VERSION "created by canmatrix"

NS_ :

BS_:

BU_: IPD

BO_ 859 ICBAD_BKPCANFD_100ms_FrP34: 8 IPD
 SG_ ISpdLmtMdResp : 25|2@0+ (1,0) [0|3] "null" Vector__XXX
 SG_ IAutoMainBeamLghtReq : 57|2@0+ (1,0) [0|3] "null" Vector__XXX

BO_ 895 ICBAD_BKPCANFD_100ms_FrP36: 16 IPD
 SG_ INarwSpcAstSwSts : 9|2@0+ (1,0) [0|3] "null" Vector__XXX
 SG_ INarwSpcAstBtnSts : 23|3@0+ (1,0) [0|7] "null" Vector__XXX
 SG_ IIPD_VehLckCtrlReq : 31|8@0+ (1,0) [0|255] "null" Vector__XXX
 SG_ IRembParkngInPrmt : 40|1@0+ (1,0) [0|1] "null" Vector__XXX
 SG_ IRembParkngInMapngResp : 41|1@0+ (1,0) [0|1] "null" Vector__XXX
 SG_ IRembParkngInPrmtSwSts : 49|2@0+ (1,0) [0|3] "null" Vector__XXX
 SG_ IRembParkngInMapngIndcr : 60|3@0+ (1,0) [0|7] "null" Vector__XXX
 SG_ IRembParkngInMapRutSeln : 63|3@0+ (1,0) [0|7] "null" Vector__XXX
 SG_ IIPDMCUTemp : 71|8@0+ (1,-40) [-40|215] "℃" Vector__XXX
 SG_ IIPDWtrClntInltReqFlg : 79|1@0+ (1,0) [0|1] "null" Vector__XXX
 SG_ ITrfGreenLghtActn : 103|1@0+ (1,0) [0|1] "null" Vector__XXX
 SG_ IRembParkngInMapngRutID : 108|5@0+ (1,0) [0|31] "null" Vector__XXX
 SG_ IRembParkngInMapngDistToEnd : 119|9@0+ (0.5,0) [0|255.5] "null" Vector__XXX
 SG_ IRembParkngInMapRutDltSeln : 126|4@0+ (1,0) [0|15] "null" Vector__XXX

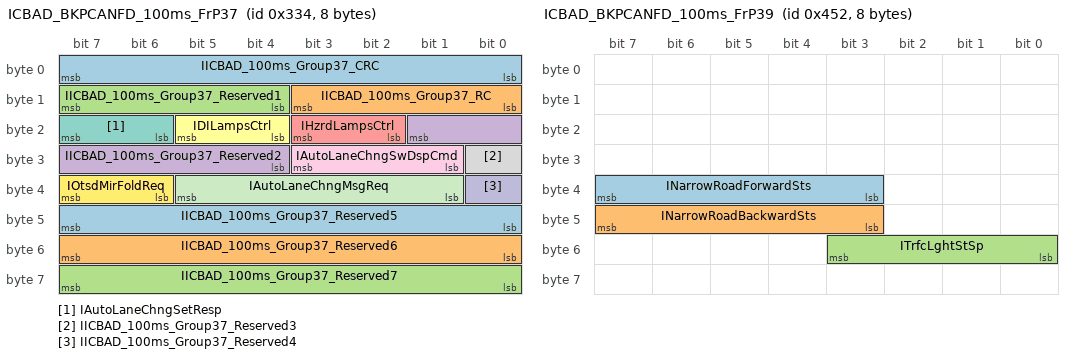
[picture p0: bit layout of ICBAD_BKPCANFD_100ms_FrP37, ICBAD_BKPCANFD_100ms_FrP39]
BO_ 820 ICBAD_BKPCANFD_100ms_FrP37: 8 IPD
 SG_ IICBAD_100ms_Group37_CRC : 7|8@0+ (1,0) [0|255] "null" Vector__XXX
 SG_ IICBAD_100ms_Group37_RC : 11|4@0+ (1,0) [0|15] "null" Vector__XXX
 SG_ IICBAD_100ms_Group37_Reserved1 : 15|4@0+ (1,0) [0|15] "null" Vector__XXX
 SG_ IICBAD_100ms_Group37_Reserved2 : 17|6@0+ (1,0) [0|63] "null" Vector__XXX
 SG_ IHzrdLampsCtrl : 19|2@0+ (1,0) [0|3] "null" Vector__XXX
 SG_ IDILampsCtrl : 21|2@0+ (1,0) [0|3] "null" Vector__XXX
 SG_ IAutoLaneChngSetResp : 23|2@0+ (1,0) [0|3] "null" Vector__XXX
 SG_ IICBAD_100ms_Group37_Reserved3 : 24|1@0+ (1,0) [0|1] "null" Vector__XXX
 SG_ IAutoLaneChngSwDspCmd : 27|3@0+ (1,0) [0|7] "null" Vector__XXX
 SG_ IICBAD_100ms_Group37_Reserved4 : 32|1@0+ (1,0) [0|1] "null" Vector__XXX
 SG_ IAutoLaneChngMsgReq : 37|5@0+ (1,0) [0|31] "null" Vector__XXX
 SG_ IOtsdMirFoldReq : 39|2@0+ (1,0) [0|3] "null" Vector__XXX
 SG_ IICBAD_100ms_Group37_Reserved5 : 47|8@0+ (1,0) [0|255] "null" Vector__XXX
 SG_ IICBAD_100ms_Group37_Reserved6 : 55|8@0+ (1,0) [0|255] "null" Vector__XXX
 SG_ IICBAD_100ms_Group37_Reserved7 : 63|8@0+ (1,0) [0|255] "null" Vector__XXX

BO_ 1105 ICBAD_BKPCANFD_100ms_FrP38: 32 IPD
 SG_ IELKSysSts : 66|3@0+ (1,0) [0|7] "null" Vector__XXX
 SG_ IELKSysFltSts : 74|3@0+ (1,0) [0|7] "null" Vector__XXX
 SG_ IAIParkngSpdswSts : 98|3@0+ (1,0) [0|7] "null" Vector__XXX
 SG_ INrwroadFwdSta : 122|3@0+ (1,0) [0|7] "null" Vector__XXX
 SG_ INrwroadsltSta : 130|3@0+ (1,0) [0|7] "null" Vector__XXX
 SG_ IIPDELKDspCmd : 194|2@0+ (1,0) [0|3] "null" Vector__XXX
 SG_ IMemParkngStrtBtnSts : 201|2@0+ (1,0) [0|3] "null" Vector__XXX
 SG_ IMemParkngBtnRcnm : 203|2@0+ (1,0) [0|3] "null" Vector__XXX
 SG_ IMemParkngBtnSts : 205|2@0+ (1,0) [0|3] "null" Vector__XXX

BO_ 1106 ICBAD_BKPCANFD_100ms_FrP39: 8 IPD
 SG_ INarrowRoadForwardSts : 39|5@0+ (1,0) [0|31] "null" Vector__XXX
 SG_ INarrowRoadBackwardSts : 47|5@0+ (1,0) [0|31] "null" Vector__XXX
 SG_ ITrfcLghtStSp : 51|4@0+ (1,0) [0|15] "null" Vector__XXX

BO_ 151 ICBAD_BKPCANFD_100ms_FrP44: 24 IPD
 SG_ IAIParkngEPAMdsts : 32|1@0+ (1,0) [0|1] "null" Vector__XXX
 SG_ ID2DSwReqResps : 41|2@0+ (1,0) [0|3] "null" Vector__XXX
 SG_ IFCTBSysFltSts : 77|2@0+ (1,0) [0|3] "null" Vector__XXX
 SG_ ID2DPriETClanSwReqResps : 79|2@0+ (1,0) [0|3] "null" Vector__XXX

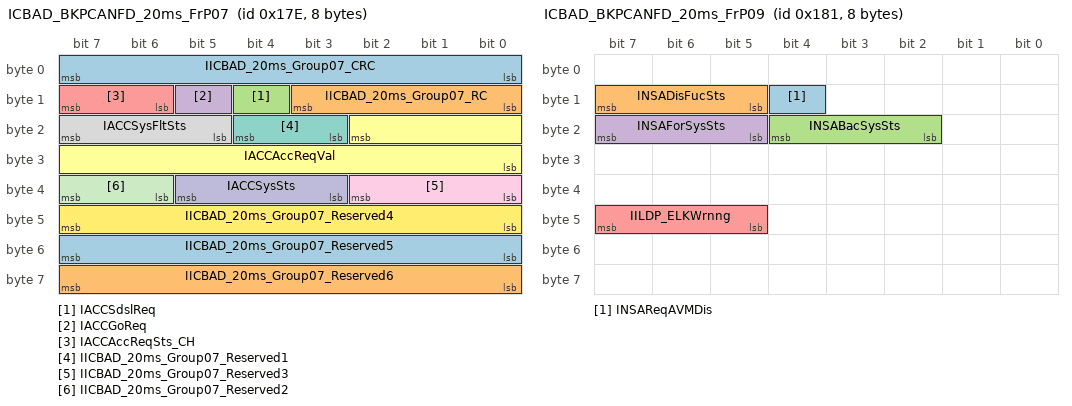
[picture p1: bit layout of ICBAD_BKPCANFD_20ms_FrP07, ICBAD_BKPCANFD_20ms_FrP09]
BO_ 382 ICBAD_BKPCANFD_20ms_FrP07: 8 IPD
 SG_ IICBAD_20ms_Group07_CRC : 7|8@0+ (1,0) [0|255] "null" Vector__XXX
 SG_ IICBAD_20ms_Group07_RC : 11|4@0+ (1,0) [0|15] "null" Vector__XXX
 SG_ IACCSdslReq : 12|1@0+ (1,0) [0|1] "null" Vector__XXX
 SG_ IACCGoReq : 13|1@0+ (1,0) [0|1] "null" Vector__XXX
 SG_ IACCAccReqSts_CH : 15|2@0+ (1,0) [0|3] "null" Vector__XXX
 SG_ IACCAccReqVal : 18|11@0+ (0.006,-10.278) [-10.278|2.004] "null" Vector__XXX
 SG_ IICBAD_20ms_Group07_Reserved1 : 20|2@0+ (1,0) [0|3] "null" Vector__XXX
 SG_ IACCSysFltSts : 23|3@0+ (1,0) [0|7] "null" Vector__XXX
 SG_ IICBAD_20ms_Group07_Reserved3 : 34|3@0+ (1,0) [0|7] "null" Vector__XXX
 SG_ IACCSysSts : 37|3@0+ (1,0) [0|7] "null" Vector__XXX
 SG_ IICBAD_20ms_Group07_Reserved2 : 39|2@0+ (1,0) [0|3] "null" Vector__XXX
 SG_ IICBAD_20ms_Group07_Reserved4 : 47|8@0+ (1,0) [0|255] "null" Vector__XXX
 SG_ IICBAD_20ms_Group07_Reserved5 : 55|8@0+ (1,0) [0|255] "null" Vector__XXX
 SG_ IICBAD_20ms_Group07_Reserved6 : 63|8@0+ (1,0) [0|255] "null" Vector__XXX

BO_ 385 ICBAD_BKPCANFD_20ms_FrP09: 8 IPD
 SG_ INSAReqAVMDis : 12|1@0+ (1,0) [0|1] "null" Vector__XXX
 SG_ INSADisFucSts : 15|3@0+ (1,0) [0|7] "null" Vector__XXX
 SG_ INSABacSysSts : 20|3@0+ (1,0) [0|7] "null" Vector__XXX
 SG_ INSAForSysSts : 23|3@0+ (1,0) [0|7] "null" Vector__XXX
 SG_ IILDP_ELKWrnng : 47|3@0+ (1,0) [0|7] "null" Vector__XXX

BO_ 736 ICBAD_BKPCANFD_50ms_FrP17: 20 IPD
 SG_ IFrtObsDist : 7|8@0+ (1,0) [0|255] "cm" Vector__XXX
 SG_ IFrtMidRObsRng : 11|4@0+ (1,0) [0|15] "null" Vector__XXX
 SG_ IFrtPDCAudWrnng : 15|4@0+ (1,0) [0|15] "null" Vector__XXX
 SG_ IRrMidLObsRng : 19|4@0+ (1,0) [0|15] "null" Vector__XXX
 SG_ IRLObsRng : 23|4@0+ (1,0) [0|15] "null" Vector__XXX
 SG_ IRrMidRObsRng : 31|4@0+ (1,0) [0|15] "null" Vector__XXX
 SG_ IPDCSysSts : 39|4@0+ (1,0) [0|15] "null" Vector__XXX
 SG_ IRrObsDist : 63|8@0+ (1,0) [0|255] "cm" Vector__XXX
 SG_ IFLSideObsRng : 67|4@0+ (1,0) [0|15] "null" Vector__XXX
 SG_ IRrPDCAudWrnng : 71|4@0+ (1,0) [0|15] "null" Vector__XXX
 SG_ IRLSideObsRng : 75|4@0+ (1,0) [0|15] "null" Vector__XXX
 SG_ IFRSideObsRng : 79|4@0+ (1,0) [0|15] "null" Vector__XXX
 SG_ IUndergndParkngGrgSts : 83|2@0+ (1,0) [0|3] "null" Vector__XXX
 SG_ IRRSideObsRng : 87|4@0+ (1,0) [0|15] "null" Vector__XXX
 SG_ IFLObsRng : 123|4@0+ (1,0) [0|15] "null" Vector__XXX
 SG_ IRRObsRng : 131|4@0+ (1,0) [0|15] "null" Vector__XXX
 SG_ IFRObsRng : 135|4@0+ (1,0) [0|15] "null" Vector__XXX
 SG_ ILADSAFnInd : 139|4@0+ (1,0) [0|15] "null" Vector__XXX
 SG_ IFrtMidLObsRng : 143|4@0+ (1,0) [0|15] "null" Vector__XXX
 SG_ IFRSObsRng : 147|4@0+ (1,0) [0|15] "null" Vector__XXX
 SG_ IFLSObsRng : 151|4@0+ (1,0) [0|15] "null" Vector__XXX
 SG_ IRRSObsRng : 155|4@0+ (1,0) [0|15] "null" Vector__XXX
 SG_ IRLSObsRng : 159|4@0+ (1,0) [0|15] "null" Vector__XXX

BO_ 314 ICBAD_CHCANFD_20ms_FrP08: 8 IPD
 SG_ ID2DSysSts : 31|4@0+ (1,0) [0|15] "null" Vector__XXX

BO_ 50 ICBAD_SecOC_ComKeyResp: 8 IPD
 SG_ IIPDTripCntResetResp : 6|1@0+ (1,0) [0|1] "null" Vector__XXX

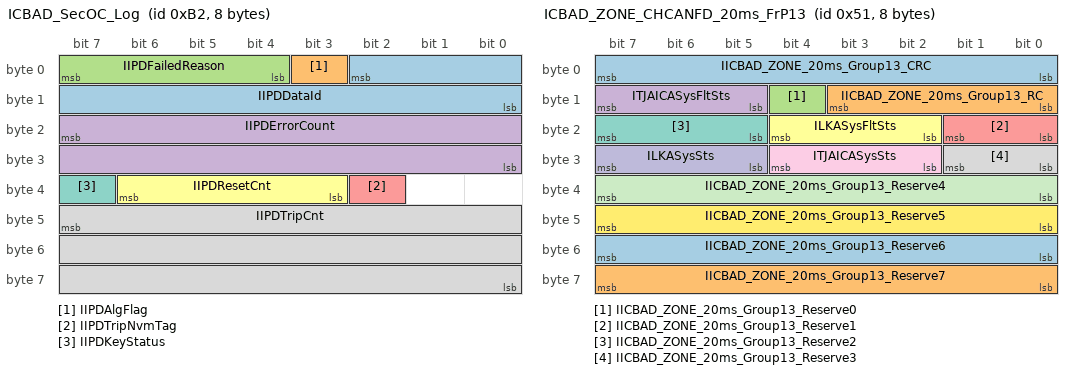
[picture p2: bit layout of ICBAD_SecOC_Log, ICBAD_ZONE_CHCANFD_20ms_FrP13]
BO_ 178 ICBAD_SecOC_Log: 8 IPD
 SG_ IIPDDataId : 2|11@0+ (1,0) [0|2047] "null" Vector__XXX
 SG_ IIPDAlgFlag : 3|1@0+ (1,0) [0|1] "null" Vector__XXX
 SG_ IIPDFailedReason : 7|4@0+ (1,0) [0|15] "null" Vector__XXX
 SG_ IIPDErrorCount : 23|16@0+ (1,0) [0|65535] "null" Vector__XXX
 SG_ IIPDTripNvmTag : 34|1@0+ (1,0) [0|1] "null" Vector__XXX
 SG_ IIPDResetCnt : 38|4@0+ (1,0) [0|15] "null" Vector__XXX
 SG_ IIPDKeyStatus : 39|1@0+ (1,0) [0|1] "null" Vector__XXX
 SG_ IIPDTripCnt : 47|24@0+ (1,0) [0|16777215] "null" Vector__XXX

BO_ 81 ICBAD_ZONE_CHCANFD_20ms_FrP13: 8 IPD
 SG_ IICBAD_ZONE_20ms_Group13_CRC : 7|8@0+ (1,0) [0|255] "null" Vector__XXX
 SG_ IICBAD_ZONE_20ms_Group13_RC : 11|4@0+ (1,0) [0|15] "null" Vector__XXX
 SG_ IICBAD_ZONE_20ms_Group13_Reserve0 : 12|1@0+ (1,0) [0|1] "null" Vector__XXX
 SG_ ITJAICASysFltSts : 15|3@0+ (1,0) [0|7] "null" Vector__XXX
 SG_ IICBAD_ZONE_20ms_Group13_Reserve1 : 17|2@0+ (1,0) [0|3] "null" Vector__XXX
 SG_ ILKASysFltSts : 20|3@0+ (1,0) [0|7] "null" Vector__XXX
 SG_ IICBAD_ZONE_20ms_Group13_Reserve2 : 23|3@0+ (1,0) [0|7] "null" Vector__XXX
 SG_ IICBAD_ZONE_20ms_Group13_Reserve3 : 25|2@0+ (1,0) [0|3] "null" Vector__XXX
 SG_ ITJAICASysSts : 28|3@0+ (1,0) [0|7] "null" Vector__XXX
 SG_ ILKASysSts : 31|3@0+ (1,0) [0|7] "null" Vector__XXX
 SG_ IICBAD_ZONE_20ms_Group13_Reserve4 : 39|8@0+ (1,0) [0|255] "null" Vector__XXX
 SG_ IICBAD_ZONE_20ms_Group13_Reserve5 : 47|8@0+ (1,0) [0|255] "null" Vector__XXX
 SG_ IICBAD_ZONE_20ms_Group13_Reserve6 : 55|8@0+ (1,0) [0|255] "null" Vector__XXX
 SG_ IICBAD_ZONE_20ms_Group13_Reserve7 : 63|8@0+ (1,0) [0|255] "null" Vector__XXX

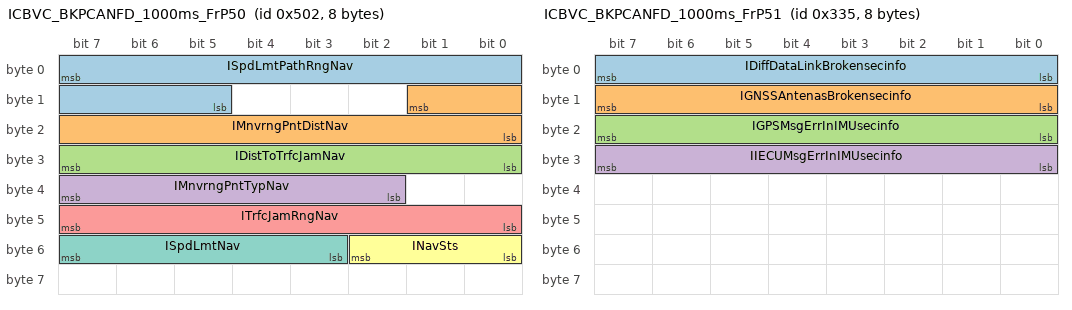
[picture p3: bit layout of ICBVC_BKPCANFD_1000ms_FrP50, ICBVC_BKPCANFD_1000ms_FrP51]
BO_ 1282 ICBVC_BKPCANFD_1000ms_FrP50: 8 Vector__XXX
 SG_ ISpdLmtPathRngNav : 7|11@0+ (0.01,0) [0.00|20.47] "km" IPD
 SG_ IMnvrngPntDistNav : 9|10@0+ (1,0) [0|1023] "m" IPD
 SG_ IDistToTrfcJamNav : 31|8@0+ (0.1,0) [0|25.5] "km" IPD
 SG_ IMnvrngPntTypNav : 39|6@0+ (1,0) [0|63] "null" IPD
 SG_ ITrfcJamRngNav : 47|8@0+ (0.1,0) [0|25.5] "km" IPD
 SG_ INavSts : 50|3@0+ (1,0) [0|7] "null" IPD
 SG_ ISpdLmtNav : 55|5@0+ (5,0) [0|155] "kph" IPD

BO_ 821 ICBVC_BKPCANFD_1000ms_FrP51: 8 Vector__XXX
 SG_ IDiffDataLinkBrokensecinfo : 7|8@0+ (1,0) [0|255] "null" IPD
 SG_ IGNSSAntenasBrokensecinfo : 15|8@0+ (1,0) [0|255] "null" IPD
 SG_ IGPSMsgErrInIMUsecinfo : 23|8@0+ (1,0) [0|255] "null" IPD
 SG_ IIECUMsgErrInIMUsecinfo : 31|8@0+ (1,0) [0|255] "null" IPD

BO_ 66 ICBVC_BKPCANFD_100ms_FrP01: 16 Vector__XXX
 SG_ IDspMeasmtSys : 15|1@0+ (1,0) [0|1] "null" IPD
 SG_ IUsgMdExtrCtrlAvlbl : 16|1@0+ (1,0) [0|1] "null" IPD
 SG_ IUsgMdCtrlSts : 17|1@0+ (1,0) [0|1] "null" IPD
 SG_ IRWSDrvMdReqV : 18|1@0+ (1,0) [0|1] "null" IPD
 SG_ IRWSDrvMdReq : 21|3@0+ (1,0) [0|7] "null" IPD
 SG_ IPDCSwReq : 23|2@0+ (1,0) [0|3] "null" IPD
 SG_ IPwrMdExtrCtrlAvlbl : 24|1@0+ (1,0) [0|1] "null" IPD
 SG_ IMdOfPwrMd : 25|1@0+ (1,0) [0|1] "null" IPD
 SG_ IClstrDspdVehSpd : 39|8@0+ (1,0) [0|255] "kph" IPD
 SG_ IFRSeatVentCtrlSts : 75|4@0+ (1,0) [0|15] "null" Vector__XXX
 SG_ IFLSeatVentCtrlSts : 83|4@0+ (1,0) [0|15] "null" Vector__XXX
 SG_ IFRSeatHeatCtrlSts : 87|4@0+ (1,0) [0|15] "null" Vector__XXX
 SG_ IFLSeatHeatCtrlSts : 95|4@0+ (1,0) [0|15] "null" Vector__XXX

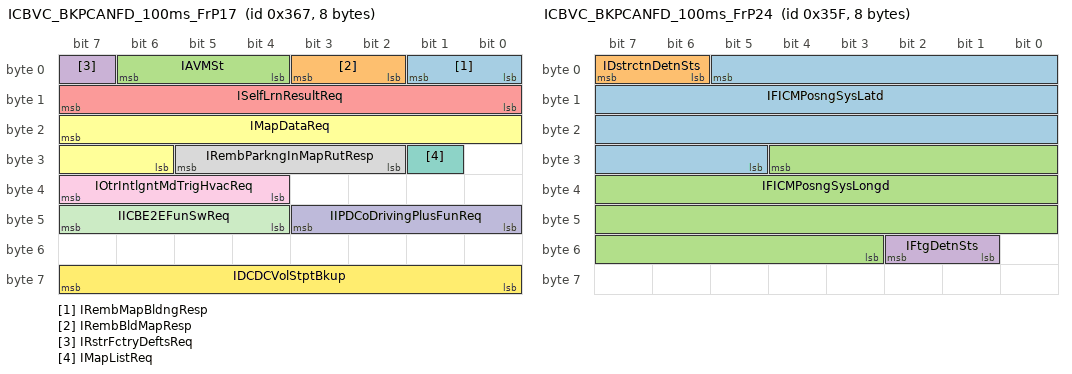
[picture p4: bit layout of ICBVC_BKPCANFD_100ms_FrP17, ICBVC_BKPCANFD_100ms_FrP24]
BO_ 871 ICBVC_BKPCANFD_100ms_FrP17: 8 Vector__XXX
 SG_ IRembMapBldngResp : 1|2@0+ (1,0) [0|3] "null" IPD
 SG_ IRembBldMapResp : 3|2@0+ (1,0) [0|3] "null" IPD
 SG_ IAVMSt : 6|3@0+ (1,0) [0|7] "null" IPD
 SG_ IRstrFctryDeftsReq : 7|1@0+ (1,0) [0|1] "null" IPD
 SG_ ISelfLrnResultReq : 15|8@0+ (1,0) [0|255] "null" IPD
 SG_ IMapDataReq : 23|10@0+ (1,0) [0|1023] "null" IPD
 SG_ IMapListReq : 25|1@0+ (1,0) [0|1] "null" IPD
 SG_ IRembParkngInMapRutResp : 29|4@0+ (1,0) [0|15] "null" IPD
 SG_ IOtrIntlgntMdTrigHvacReq : 39|4@0+ (1,0) [0|15] "null" Vector__XXX
 SG_ IIPDCoDrivingPlusFunReq : 43|4@0+ (1,0) [0|15] "null" IPD
 SG_ IICBE2EFunSwReq : 47|4@0+ (1,0) [0|15] "null" IPD
 SG_ IDCDCVolStptBkup : 63|8@0+ (0.03125,8.5) [8.50000|16.46875] "V" Vector__XXX

BO_ 863 ICBVC_BKPCANFD_100ms_FrP24: 8 Vector__XXX
 SG_ IFICMPosngSysLatd : 5|25@0- (0.000010,0) [-167.772160|167.772150] "Degree" IPD
 SG_ IDstrctnDetnSts : 7|2@0+ (1,0) [0|3] "null" IPD
 SG_ IFICMPosngSysLongd : 28|26@0- (0.000010,0) [-335.544320|335.544310] "Degree" IPD
 SG_ IFtgDetnSts : 50|2@0+ (1,0) [0|3] "null" IPD

BO_ 906 ICBVC_BKPCANFD_100ms_FrP25: 16 Vector__XXX
 SG_ INavCrntRoadTyp : 3|4@0+ (1,0) [0|15] "null" IPD
 SG_ INavNewIcon : 7|4@0+ (1,0) [0|15] "null" IPD
 SG_ IVceCntrl_CriSpdDecreValu : 15|8@0+ (1,0) [0|255] "kph" IPD
 SG_ IVceCntrl_CriSpdIncreValu : 23|8@0+ (1,0) [0|255] "kph" IPD
 SG_ IVceCntrl_CriSpdValu : 31|8@0+ (1,0) [0|255] "kph" IPD
 SG_ IMinorAdjSetReq : 33|2@0+ (1,0) [0|3] "null" IPD
 SG_ IVceCntrl_DistanLevl : 36|3@0+ (1,0) [0|7] "null" IPD
 SG_ IVceCntrl_DecreCriSpd : 39|3@0+ (1,0) [0|7] "null" IPD
 SG_ IParkOutEntrySetReq : 41|2@0+ (1,0) [0|3] "null" IPD
 SG_ IVceCntrl_AIPilot : 44|3@0+ (1,0) [0|7] "null" IPD
 SG_ INavTrfcLghtInfo : 47|3@0+ (1,0) [0|7] "null" IPD
 SG_ INavCountryCode : 49|10@0+ (1,0) [0|1023] "null" IPD
 SG_ IVceCntrl_DistanLevlIncre : 52|3@0+ (1,0) [0|7] "null" IPD
 SG_ IVceCntrl_DistanLevlDecre : 55|3@0+ (1,0) [0|7] "null" IPD
 SG_ INavSpdLmtValUnit : 66|2@0+ (1,0) [0|3] "null" IPD
 SG_ INavNewIconDist : 71|5@0+ (0.1,0) [0|3.1] "null" IPD
 SG_ INavSpdLmtValSts : 73|2@0+ (1,0) [0|3] "null" IPD
 SG_ INavDistFromFrtEleccEye : 79|6@0+ (0.1,0) [0|6.3] "null" IPD
 SG_ INavItvalSpdDetnDistRetDist : 87|15@0+ (0.1,0) [0|3276.7] "null" IPD
 SG_ INavSpdLmtVal : 103|15@0+ (0.015625,0) [0.000000|511.984375] "null" IPD
 SG_ IVceCntrl_IncreCriSpd : 122|3@0+ (1,0) [0|7] "null" IPD
 SG_ INavSpdLmtTyp : 126|4@0+ (1,0) [0|15] "null" IPD

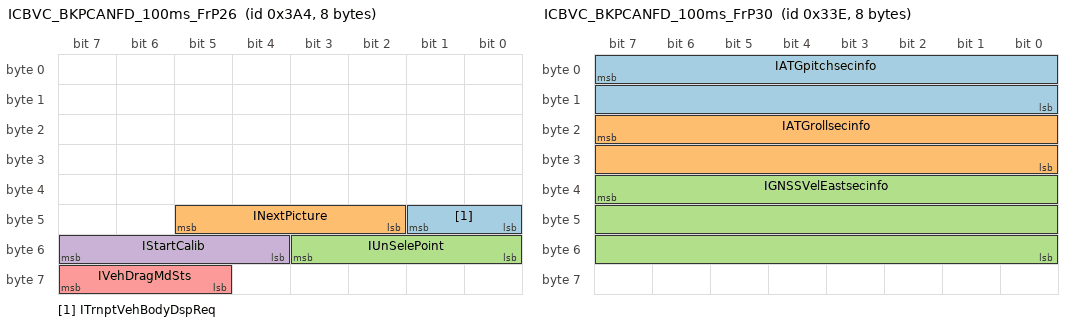
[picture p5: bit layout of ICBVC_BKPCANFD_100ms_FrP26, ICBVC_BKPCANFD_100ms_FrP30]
BO_ 932 ICBVC_BKPCANFD_100ms_FrP26: 8 Vector__XXX
 SG_ ITrnptVehBodyDspReq : 41|2@0+ (1,0) [0|3] "null" IPD
 SG_ INextPicture : 45|4@0+ (1,0) [0|15] "null" IPD
 SG_ IUnSelePoint : 51|4@0+ (1,0) [0|15] "null" IPD
 SG_ IStartCalib : 55|4@0+ (1,0) [0|15] "null" IPD
 SG_ IVehDragMdSts : 63|3@0+ (1,0) [0|7] "null" IPD

BO_ 830 ICBVC_BKPCANFD_100ms_FrP30: 8 Vector__XXX
 SG_ IATGpitchsecinfo : 7|16@0- (0.01,0) [-327.68|327.67] "null" IPD
 SG_ IATGrollsecinfo : 23|16@0- (0.01,0) [-327.68|327.67] "null" IPD
 SG_ IGNSSVelEastsecinfo : 39|24@0- (0.001,0) [-8388.608|8388.607] "null" IPD

BO_ 1104 ICBVC_BKPCANFD_100ms_FrP31: 20 Vector__XXX
 SG_ IParkngFuncICMRsrv01 : 15|4@0+ (1,0) [0|15] "N/A" IPD
 SG_ IMapDelete : 23|8@0+ (1,0) [0|255] "null" IPD
 SG_ IParkngFuncICMRsrv03 : 27|4@0+ (1,0) [0|15] "N/A" IPD
 SG_ IParkngFuncICMRsrv02 : 31|4@0+ (1,0) [0|15] "N/A" IPD
 SG_ IFrntWhlMinorAdjLeft : 35|4@0+ (1,0) [0|15] "null" IPD
 SG_ INrwroadFwdCtlReq : 39|4@0+ (1,0) [0|15] "null" IPD
 SG_ IRearWhlMinorAdjLeft : 43|4@0+ (1,0) [0|15] "null" IPD
 SG_ IFrntWhlMinorAdjRight : 47|4@0+ (1,0) [0|15] "null" IPD
 SG_ IMinorAdjForward : 51|4@0+ (1,0) [0|15] "null" IPD
 SG_ IRearWhlMinorAdjRight : 55|4@0+ (1,0) [0|15] "null" IPD
 SG_ ISpeedRegulationFixedReq : 59|4@0+ (1,0) [0|15] "null" IPD
 SG_ IMinorAdjBackward : 63|4@0+ (1,0) [0|15] "null" IPD
 SG_ IMemParkngReq : 64|1@0+ (1,0) [0|1] "null" IPD
 SG_ IParkngOutDirChs : 67|3@0+ (1,0) [0|7] "null" IPD
 SG_ ISpeedRegulationPerReq : 71|4@0+ (1,0) [0|15] "null" IPD
 SG_ ISlntSrchParkngLotSet : 73|2@0+ (1,0) [0|3] "null" IPD
 SG_ IDIYParkngLotSty : 76|3@0+ (1,0) [0|7] "null" IPD
 SG_ IAIParkngDrvStySet : 79|3@0+ (1,0) [0|7] "null" IPD
 SG_ IFucSwReq1 : 81|2@0+ (1,0) [0|3] "null" IPD
 SG_ IAIParkngSpdsw : 84|3@0+ (1,0) [0|7] "null" IPD
 SG_ IMnrAdjCntrlReq : 87|3@0+ (1,0) [0|7] "null" IPD
 SG_ IUNPSwReq : 89|2@0+ (1,0) [0|3] "null" IPD
 SG_ IFucSwReq2 : 92|3@0+ (1,0) [0|7] "null" IPD
 SG_ IVoicBrdstMode : 95|3@0+ (1,0) [0|7] "null" IPD
 SG_ IManualpilotSwReq : 97|2@0+ (1,0) [0|3] "null" IPD
 SG_ INrwroadsltReq : 100|3@0+ (1,0) [0|7] "null" IPD
 SG_ INrwroadFwdReq : 103|3@0+ (1,0) [0|7] "null" IPD
 SG_ IPilotplusSwReq : 105|2@0+ (1,0) [0|3] "null" IPD
 SG_ IParkngrampastsltReq : 108|3@0+ (1,0) [0|7] "null" IPD
 SG_ IParkngrampastReq : 111|3@0+ (1,0) [0|7] "null" IPD
 SG_ IParkngOutRcmnSet : 113|2@0+ (1,0) [0|3] "null" IPD
 SG_ IAIParkngOutSty : 115|2@0+ (1,0) [0|3] "null" IPD
 SG_ IRvrsTrckParkng : 117|2@0+ (1,0) [0|3] "null" IPD
 SG_ ISpeedRegulationModeReq : 119|2@0+ (1,0) [0|3] "null" IPD
 SG_ IMnrAdjReq : 122|1@0+ (1,0) [0|1] "null" IPD
 SG_ IDIYParkngLotReq : 123|1@0+ (1,0) [0|1] "null" IPD
 SG_ IEdtNameInd : 124|1@0+ (1,0) [0|1] "null" IPD
 SG_ ITryMemParkngNw : 125|1@0+ (1,0) [0|1] "null" IPD
 SG_ IDIYParkngLotSet : 127|2@0+ (1,0) [0|3] "null" IPD
 SG_ IParkngrampastCtlReq : 135|4@0+ (1,0) [0|15] "null" IPD

BO_ 832 ICBVC_BKPCANFD_100ms_FrP35: 8 Vector__XXX
 SG_ IAIPilotSwReq : 1|2@0+ (1,0) [0|3] "null" IPD
 SG_ IAIPilotDrvMdlReq : 4|3@0+ (1,0) [0|7] "null" IPD
 SG_ IFCWSnstvtLvlReq : 7|3@0+ (1,0) [0|7] "null" IPD
 SG_ IELKSwReq : 9|2@0+ (1,0) [0|3] "null" IPD
 SG_ ILDWAdoWrnngReq : 11|2@0+ (1,0) [0|3] "null" IPD
 SG_ IFCWSwReq : 13|2@0+ (1,0) [0|3] "null" IPD
 SG_ ITrfcLghtFuctionSwReq : 15|2@0+ (1,0) [0|3] "null" IPD
 SG_ IDOWSelReq : 17|2@0+ (1,0) [0|3] "null" IPD
 SG_ IBSDSelReq : 19|2@0+ (1,0) [0|3] "null" IPD
 SG_ IAIPilotAudSwReq : 21|2@0+ (1,0) [0|3] "null" IPD
 SG_ IEndToEndPilotSwReq : 23|2@0+ (1,0) [0|3] "null" IPD
 SG_ ILaneChngRecmedMdlReq : 25|2@0+ (1,0) [0|3] "null" IPD
 SG_ IAEBSwReq : 27|2@0+ (1,0) [0|3] "null" IPD
 SG_ ILDWLKAHptWrnngReq : 29|2@0+ (1,0) [0|3] "null" IPD
 SG_ IRCWSelReq : 31|2@0+ (1,0) [0|3] "null" IPD
 SG_ ILaneChngCnfmSwReq : 33|2@0+ (1,0) [0|3] "null" IPD
 SG_ IIntscnDclSwReq : 35|2@0+ (1,0) [0|3] "null" IPD
 SG_ IIntlgntParkngWifiSwReq : 37|2@0+ (1,0) [0|3] "null" IPD
 SG_ IIntlgntParkngNavSwReq : 39|2@0+ (1,0) [0|3] "null" IPD
 SG_ INOASwReq : 41|2@0+ (1,0) [0|3] "null" IPD
 SG_ INOAQukSwReq : 43|2@0+ (1,0) [0|3] "null" IPD
 SG_ INarwSpcAstSwReq : 45|2@0+ (1,0) [0|3] "null" IPD
 SG_ ILaneChngWrnngSwReq : 47|2@0+ (1,0) [0|3] "null" IPD
 SG_ ILDWSnstvtLvlReq : 49|2@0+ (1,0) [0|3] "null" IPD
 SG_ IRembParkngInPrmtSwReq : 51|2@0+ (1,0) [0|3] "null" IPD
 SG_ IRDASwReq : 53|2@0+ (1,0) [0|3] "null" IPD
 SG_ IRCTSysSelReq : 55|2@0+ (1,0) [0|3] "null" IPD
 SG_ ILCASelReq : 57|2@0+ (1,0) [0|3] "null" IPD
 SG_ ILDWLKASwReq : 60|3@0+ (1,0) [0|7] "null" IPD
 SG_ ISpdLmtMdlReq : 63|3@0+ (1,0) [0|7] "null" IPD

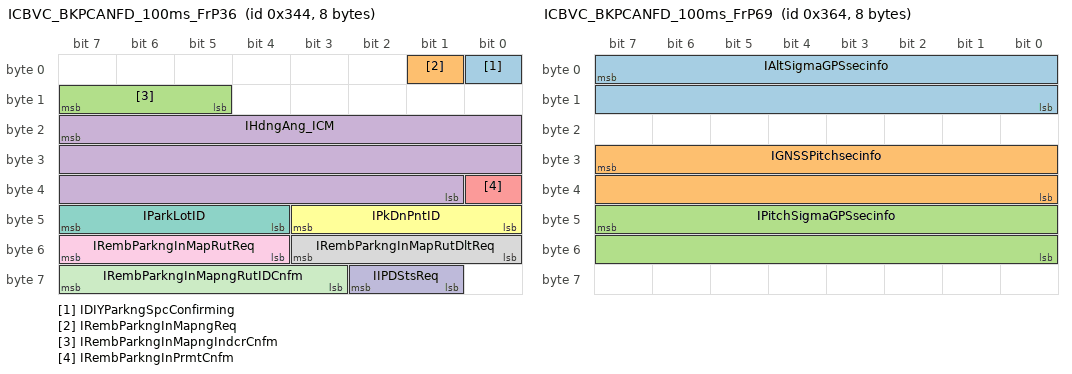
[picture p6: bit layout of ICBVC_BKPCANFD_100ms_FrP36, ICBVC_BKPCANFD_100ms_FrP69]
BO_ 836 ICBVC_BKPCANFD_100ms_FrP36: 8 Vector__XXX
 SG_ IDIYParkngSpcConfirming : 0|1@0+ (1,0) [0|1] "null" IPD
 SG_ IRembParkngInMapngReq : 1|1@0+ (1,0) [0|1] "null" IPD
 SG_ IRembParkngInMapngIndcrCnfm : 15|3@0+ (1,0) [0|7] "null" IPD
 SG_ IHdngAng_ICM : 23|23@0- (0.0000010,-3.14159) [-7.3358940|1.0527130] "null" IPD
 SG_ IRembParkngInPrmtCnfm : 32|1@0+ (1,0) [0|1] "null" IPD
 SG_ IPkDnPntID : 43|4@0+ (1,0) [0|15] "null" IPD
 SG_ IParkLotID : 47|4@0+ (1,0) [0|15] "null" IPD
 SG_ IRembParkngInMapRutDltReq : 51|4@0+ (1,0) [0|15] "null" IPD
 SG_ IRembParkngInMapRutReq : 55|4@0+ (1,0) [0|15] "null" IPD
 SG_ IIPDStsReq : 58|2@0+ (1,0) [0|3] "null" IPD
 SG_ IRembParkngInMapngRutIDCnfm : 63|5@0+ (1,0) [0|31] "null" IPD

BO_ 1007 ICBVC_BKPCANFD_100ms_FrP68: 8 Vector__XXX
 SG_ IGNSSVelNorthsecinfo : 7|24@0- (0.001,0) [-8388.608|8388.607] "null" IPD
 SG_ IGNSSVelUpsecinfo : 31|16@0- (0.001,0) [-32.768|32.767] "null" IPD

BO_ 868 ICBVC_BKPCANFD_100ms_FrP69: 8 Vector__XXX
 SG_ IAltSigmaGPSsecinfo : 7|16@0+ (0.001,0) [0.000|65.535] "null" IPD
 SG_ IGNSSPitchsecinfo : 31|16@0- (0.01,0) [-327.68|327.67] "null" IPD
 SG_ IPitchSigmaGPSsecinfo : 47|16@0+ (0.001,0) [0.000|65.535] "null" IPD

BO_ 827 ICBVC_BKPCANFD_100ms_FrP70: 8 Vector__XXX
 SG_ IGNSSLatitudesecinfo : 15|40@0- (1.0E-009,0) [-549.7558138880|549.7558138870] "Degree" IPD

BO_ 828 ICBVC_BKPCANFD_100ms_FrP71: 8 Vector__XXX
 SG_ IGNSSHeadingsecinfo : 7|16@0+ (0.01,0) [0.00|655.35] "null" IPD
 SG_ IGNSSHeightsecinfo : 31|24@0- (0.001,0) [-8388.608|8388.607] "null" IPD

BO_ 683 ICBVC_BKPCANFD_100ms_FrP72: 12 Vector__XXX
 SG_ IDrvrUseIDBradcst : 7|64@0+ (1,0) [0|18446744073709551615] "null" IPD
 SG_ IDrvrUseIDRoleInfo : 71|3@0+ (1,0) [0|7] "null" IPD

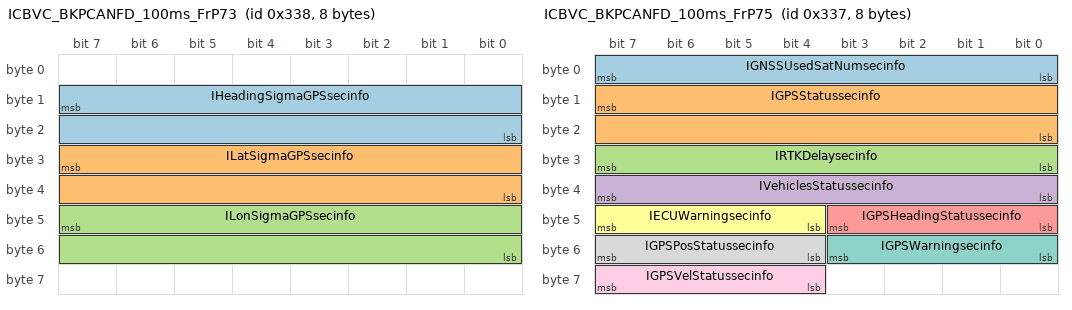
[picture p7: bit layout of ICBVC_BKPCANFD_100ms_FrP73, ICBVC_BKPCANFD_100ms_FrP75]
BO_ 824 ICBVC_BKPCANFD_100ms_FrP73: 8 Vector__XXX
 SG_ IHeadingSigmaGPSsecinfo : 15|16@0+ (0.001,0) [0.000|65.535] "null" IPD
 SG_ ILatSigmaGPSsecinfo : 31|16@0+ (0.001,0) [0.000|65.535] "null" IPD
 SG_ ILonSigmaGPSsecinfo : 47|16@0+ (0.001,0) [0.000|65.535] "null" IPD

BO_ 826 ICBVC_BKPCANFD_100ms_FrP74: 8 Vector__XXX
 SG_ IGNSSLongitudesecinfo : 15|40@0- (1.0E-009,0) [-549.7558138880|549.7558138870] "Degree" IPD

BO_ 823 ICBVC_BKPCANFD_100ms_FrP75: 8 Vector__XXX
 SG_ IGNSSUsedSatNumsecinfo : 7|8@0+ (1,0) [0|255] "null" IPD
 SG_ IGPSStatussecinfo : 15|16@0+ (1,0) [0|65535] "null" IPD
 SG_ IRTKDelaysecinfo : 31|8@0+ (1,0) [0|255] "Min" IPD
 SG_ IVehiclesStatussecinfo : 39|8@0+ (1,0) [0|255] "null" IPD
 SG_ IGPSHeadingStatussecinfo : 43|4@0+ (1,0) [0|15] "null" IPD
 SG_ IECUWarningsecinfo : 47|4@0+ (1,0) [0|15] "null" IPD
 SG_ IGPSWarningsecinfo : 51|4@0+ (1,0) [0|15] "null" IPD
 SG_ IGPSPosStatussecinfo : 55|4@0+ (1,0) [0|15] "null" IPD
 SG_ IGPSVelStatussecinfo : 63|4@0+ (1,0) [0|15] "null" IPD

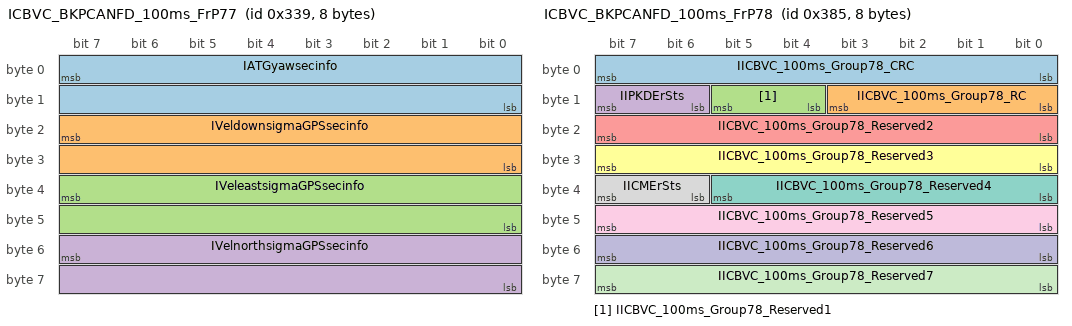
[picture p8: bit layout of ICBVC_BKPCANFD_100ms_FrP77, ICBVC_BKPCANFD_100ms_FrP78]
BO_ 825 ICBVC_BKPCANFD_100ms_FrP77: 8 Vector__XXX
 SG_ IATGyawsecinfo : 7|16@0- (0.01,0) [-327.68|327.67] "null" IPD
 SG_ IVeldownsigmaGPSsecinfo : 23|16@0+ (0.001,0) [0.000|65.535] "null" IPD
 SG_ IVeleastsigmaGPSsecinfo : 39|16@0+ (0.001,0) [0.000|65.535] "null" IPD
 SG_ IVelnorthsigmaGPSsecinfo : 55|16@0+ (0.001,0) [0.000|65.535] "null" IPD

BO_ 901 ICBVC_BKPCANFD_100ms_FrP78: 8 Vector__XXX
 SG_ IICBVC_100ms_Group78_CRC : 7|8@0+ (1,0) [0|255] "null" IPD
 SG_ IICBVC_100ms_Group78_RC : 11|4@0+ (1,0) [0|15] "null" IPD
 SG_ IICBVC_100ms_Group78_Reserved1 : 13|2@0+ (1,0) [0|3] "null" IPD
 SG_ IIPKDErSts : 15|2@0+ (1,0) [0|3] "null" IPD
 SG_ IICBVC_100ms_Group78_Reserved2 : 23|8@0+ (1,0) [0|255] "null" IPD
 SG_ IICBVC_100ms_Group78_Reserved3 : 31|8@0+ (1,0) [0|255] "null" IPD
 SG_ IICBVC_100ms_Group78_Reserved4 : 37|6@0+ (1,0) [0|63] "null" IPD
 SG_ IICMErSts : 39|2@0+ (1,0) [0|3] "null" IPD
 SG_ IICBVC_100ms_Group78_Reserved5 : 47|8@0+ (1,0) [0|255] "null" IPD
 SG_ IICBVC_100ms_Group78_Reserved6 : 55|8@0+ (1,0) [0|255] "null" IPD
 SG_ IICBVC_100ms_Group78_Reserved7 : 63|8@0+ (1,0) [0|255] "null" IPD

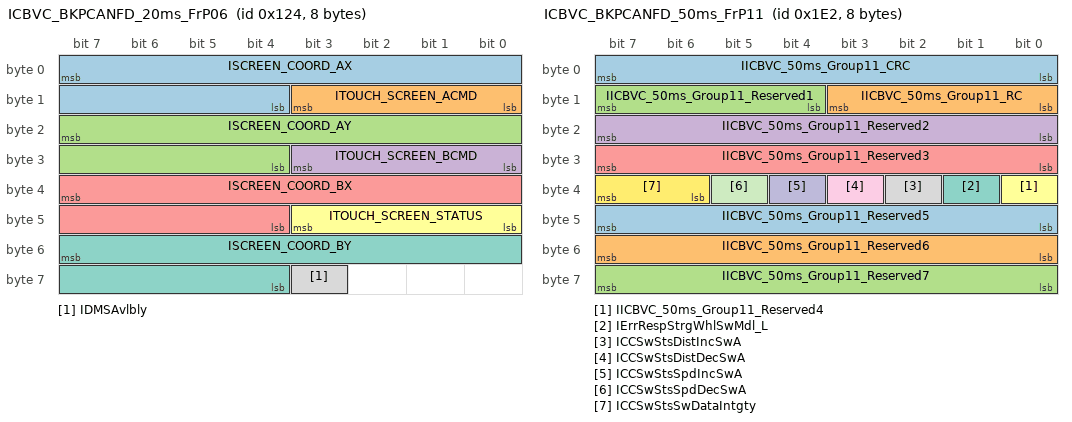
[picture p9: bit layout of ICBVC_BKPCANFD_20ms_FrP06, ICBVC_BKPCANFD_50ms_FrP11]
BO_ 292 ICBVC_BKPCANFD_20ms_FrP06: 8 Vector__XXX
 SG_ ISCREEN_COORD_AX : 7|12@0+ (1,0) [0|4095] "null" IPD
 SG_ ITOUCH_SCREEN_ACMD : 11|4@0+ (1,0) [0|15] "null" IPD
 SG_ ISCREEN_COORD_AY : 23|12@0+ (1,0) [0|4095] "null" IPD
 SG_ ITOUCH_SCREEN_BCMD : 27|4@0+ (1,0) [0|15] "null" IPD
 SG_ ISCREEN_COORD_BX : 39|12@0+ (1,0) [0|4095] "null" IPD
 SG_ ITOUCH_SCREEN_STATUS : 43|4@0+ (1,0) [0|15] "null" IPD
 SG_ ISCREEN_COORD_BY : 55|12@0+ (1,0) [0|4095] "null" IPD
 SG_ IDMSAvlbly : 59|1@0+ (1,0) [0|1] "null" IPD

BO_ 482 ICBVC_BKPCANFD_50ms_FrP11: 8 Vector__XXX
 SG_ IICBVC_50ms_Group11_CRC : 7|8@0+ (1,0) [0|255] "null" IPD
 SG_ IICBVC_50ms_Group11_RC : 11|4@0+ (1,0) [0|15] "null" IPD
 SG_ IICBVC_50ms_Group11_Reserved1 : 15|4@0+ (1,0) [0|15] "null" IPD
 SG_ IICBVC_50ms_Group11_Reserved2 : 23|8@0+ (1,0) [0|255] "null" IPD
 SG_ IICBVC_50ms_Group11_Reserved3 : 31|8@0+ (1,0) [0|255] "null" IPD
 SG_ IICBVC_50ms_Group11_Reserved4 : 32|1@0+ (1,0) [0|1] "null" IPD
 SG_ IErrRespStrgWhlSwMdl_L : 33|1@0+ (1,0) [0|1] "null" IPD
 SG_ ICCSwStsDistIncSwA : 34|1@0+ (1,0) [0|1] "null" IPD
 SG_ ICCSwStsDistDecSwA : 35|1@0+ (1,0) [0|1] "null" IPD
 SG_ ICCSwStsSpdIncSwA : 36|1@0+ (1,0) [0|1] "null" IPD
 SG_ ICCSwStsSpdDecSwA : 37|1@0+ (1,0) [0|1] "null" IPD
 SG_ ICCSwStsSwDataIntgty : 39|2@0+ (1,0) [0|3] "null" IPD
 SG_ IICBVC_50ms_Group11_Reserved5 : 47|8@0+ (1,0) [0|255] "null" IPD
 SG_ IICBVC_50ms_Group11_Reserved6 : 55|8@0+ (1,0) [0|255] "null" IPD
 SG_ IICBVC_50ms_Group11_Reserved7 : 63|8@0+ (1,0) [0|255] "null" IPD

BA_DEF_ BO_ "FrameTriggeringName" STRING;
BA_DEF_ BO_ "GenMsgCycleTime" INT 0 65535;
BA_DEF_ BO_ "GenMsgDelayTime" INT 0 65535;
BA_DEF_ BO_ "GenMsgSendType" ENUM  "cyclicX","spontanX","cyclicIfActiveX","spontanWithDelay","cyclicAndSpontanX","cyclicAndSpontanWithDelay","spontanWithRepitition","cyclicIfActiveAndSpontanWD","cyclicIfActiveFast","cyclicWithRepeatOnDemand","none";
BA_DEF_ BO_ "GenMsgStartValue" STRING;
BA_DEF_ BO_ "PduName" STRING;
BA_DEF_ BO_ "VFrameFormat" ENUM  "StandardCAN","ExtendedCAN","reserved","reserved","reserved","reserved","reserved","reserved","reserved","reserved","reserved","reserved","reserved","reserved","StandardCAN_FD","ExtendedCAN_FD";
BA_DEF_ SG_ "CompuMethodName" STRING;
BA_DEF_ SG_ "GenSigStartValue" FLOAT 0 100000000000;
BA_DEF_ SG_ "ISignalName" STRING;
BA_DEF_ SG_ "LongName" STRING;
BA_DEF_ SG_ "SysSignalName" STRING;
BA_DEF_ SG_ "SystemSignalLongSymbol" STRING;
BA_ "FrameTriggeringName" BO_ 859 "ICBAD_BKPCANFD_100ms_FrP34";
BA_ "GenMsgCycleTime" BO_ 859 100;
BA_ "GenMsgSendType" BO_ 859 0;
BA_ "GenMsgStartValue" BO_ 859 "0000000000000000";
BA_ "PduName" BO_ 859 "ICBAD_100ms_PDU34";
BA_ "VFrameFormat" BO_ 859 14;
BA_ "FrameTriggeringName" BO_ 895 "ICBAD_BKPCANFD_100ms_FrP36";
BA_ "GenMsgCycleTime" BO_ 895 100;
BA_ "GenMsgSendType" BO_ 895 0;
BA_ "GenMsgStartValue" BO_ 895 "0002000000000100ff00000000000000";
BA_ "PduName" BO_ 895 "ICBAD_100ms_PDU36";
BA_ "VFrameFormat" BO_ 895 14;
BA_ "FrameTriggeringName" BO_ 820 "ICBAD_BKPCANFD_100ms_FrP37";
BA_ "GenMsgCycleTime" BO_ 820 100;
BA_ "GenMsgSendType" BO_ 820 0;
BA_ "GenMsgStartValue" BO_ 820 "00f003f101ffffff";
BA_ "PduName" BO_ 820 "ICBAD_100ms_PDU37";
BA_ "VFrameFormat" BO_ 820 14;
BA_ "FrameTriggeringName" BO_ 1105 "ICBAD_BKPCANFD_100ms_FrP38";
BA_ "GenMsgCycleTime" BO_ 1105 100;
BA_ "GenMsgSendType" BO_ 1105 0;
BA_ "GenMsgStartValue" BO_ 1105 "0000000000000000010000000000000000000000000000000400000000000000";
BA_ "PduName" BO_ 1105 "ICBAD_100ms_PDU38";
BA_ "VFrameFormat" BO_ 1105 14;
BA_ "FrameTriggeringName" BO_ 1106 "ICBAD_BKPCANFD_100ms_FrP39";
BA_ "GenMsgCycleTime" BO_ 1106 100;
BA_ "GenMsgSendType" BO_ 1106 0;
BA_ "GenMsgStartValue" BO_ 1106 "0000000000000000";
BA_ "PduName" BO_ 1106 "ICBAD_100ms_PDU39";
BA_ "VFrameFormat" BO_ 1106 14;
BA_ "FrameTriggeringName" BO_ 151 "ICBAD_BKPCANFD_100ms_FrP44";
BA_ "GenMsgCycleTime" BO_ 151 100;
BA_ "GenMsgSendType" BO_ 151 0;
BA_ "GenMsgStartValue" BO_ 151 "000000000000000000000000000000000000000000000000";
BA_ "PduName" BO_ 151 "ICBAD_100ms_PDU44";
BA_ "VFrameFormat" BO_ 151 14;
BA_ "FrameTriggeringName" BO_ 382 "ICBAD_BKPCANFD_20ms_FrP07";
BA_ "GenMsgCycleTime" BO_ 382 20;
BA_ "GenMsgSendType" BO_ 382 0;
BA_ "GenMsgStartValue" BO_ 382 "00001eb1c7ffffff";
BA_ "PduName" BO_ 382 "ICBAD_20ms_PDU07";
BA_ "VFrameFormat" BO_ 382 14;
BA_ "FrameTriggeringName" BO_ 385 "ICBAD_BKPCANFD_20ms_FrP09";
BA_ "GenMsgCycleTime" BO_ 385 20;
BA_ "GenMsgSendType" BO_ 385 0;
BA_ "GenMsgStartValue" BO_ 385 "0000000000000000";
BA_ "PduName" BO_ 385 "ICBAD_20ms_PDU09";
BA_ "VFrameFormat" BO_ 385 14;
BA_ "FrameTriggeringName" BO_ 736 "ICBAD_BKPCANFD_50ms_FrP17";
BA_ "GenMsgCycleTime" BO_ 736 50;
BA_ "GenMsgSendType" BO_ 736 0;
BA_ "GenMsgStartValue" BO_ 736 "0000000000000000000000000000000000000000";
BA_ "PduName" BO_ 736 "ICBAD_50ms_PDU17";
BA_ "VFrameFormat" BO_ 736 14;
BA_ "FrameTriggeringName" BO_ 314 "ICBAD_CHCANFD_20ms_FrP08";
BA_ "GenMsgCycleTime" BO_ 314 20;
BA_ "GenMsgSendType" BO_ 314 0;
BA_ "GenMsgStartValue" BO_ 314 "0000000000000000";
BA_ "PduName" BO_ 314 "ICBAD_20ms_PDU08";
BA_ "VFrameFormat" BO_ 314 14;
BA_ "FrameTriggeringName" BO_ 50 "ICBAD_SecOC_ComKeyResp";
BA_ "GenMsgSendType" BO_ 50 1;
BA_ "GenMsgStartValue" BO_ 50 "0000000000000000";
BA_ "PduName" BO_ 50 "ICBAD_SecOCComKeyResp_PDU01";
BA_ "VFrameFormat" BO_ 50 14;
BA_ "FrameTriggeringName" BO_ 178 "ICBAD_SecOC_Log";
BA_ "GenMsgSendType" BO_ 178 1;
BA_ "GenMsgStartValue" BO_ 178 "0000000000000000";
BA_ "PduName" BO_ 178 "ICBAD_SecOCLog_PDU01";
BA_ "VFrameFormat" BO_ 178 14;
BA_ "FrameTriggeringName" BO_ 81 "ICBAD_ZONE_CHCANFD_20ms_FrP13";
BA_ "GenMsgCycleTime" BO_ 81 20;
BA_ "GenMsgSendType" BO_ 81 0;
BA_ "GenMsgStartValue" BO_ 81 "0010e303ffffffff";
BA_ "PduName" BO_ 81 "ICBAD_ZONE_20ms_PDU13";
BA_ "VFrameFormat" BO_ 81 14;
BA_ "FrameTriggeringName" BO_ 1282 "ICBVC_BKPCANFD_1000ms_FrP50";
BA_ "GenMsgCycleTime" BO_ 1282 1000;
BA_ "GenMsgSendType" BO_ 1282 0;
BA_ "GenMsgStartValue" BO_ 1282 "ffe3ffff00fff800";
BA_ "PduName" BO_ 1282 "ICBVC_1000ms_PDU50";
BA_ "VFrameFormat" BO_ 1282 14;
BA_ "FrameTriggeringName" BO_ 821 "ICBVC_BKPCANFD_1000ms_FrP51";
BA_ "GenMsgCycleTime" BO_ 821 1000;
BA_ "GenMsgSendType" BO_ 821 0;
BA_ "GenMsgStartValue" BO_ 821 "0000000000000000";
BA_ "PduName" BO_ 821 "ICBVC_1000ms_PDU51";
BA_ "VFrameFormat" BO_ 821 14;
BA_ "FrameTriggeringName" BO_ 66 "ICBVC_BKPCANFD_100ms_FrP01";
BA_ "GenMsgCycleTime" BO_ 66 100;
BA_ "GenMsgSendType" BO_ 66 0;
BA_ "GenMsgStartValue" BO_ 66 "00000400000000000000000000000000";
BA_ "PduName" BO_ 66 "ICBVC_100ms_PDU01";
BA_ "VFrameFormat" BO_ 66 14;
BA_ "FrameTriggeringName" BO_ 871 "ICBVC_BKPCANFD_100ms_FrP17";
BA_ "GenMsgCycleTime" BO_ 871 100;
BA_ "GenMsgSendType" BO_ 871 0;
BA_ "GenMsgStartValue" BO_ 871 "00000000000000fe";
BA_ "PduName" BO_ 871 "ICBVC_100ms_PDU17";
BA_ "VFrameFormat" BO_ 871 14;
BA_ "FrameTriggeringName" BO_ 863 "ICBVC_BKPCANFD_100ms_FrP24";
BA_ "GenMsgCycleTime" BO_ 863 100;
BA_ "GenMsgSendType" BO_ 863 0;
BA_ "GenMsgStartValue" BO_ 863 "0000000000000000";
BA_ "PduName" BO_ 863 "ICBVC_100ms_PDU24";
BA_ "VFrameFormat" BO_ 863 14;
BA_ "FrameTriggeringName" BO_ 906 "ICBVC_BKPCANFD_100ms_FrP25";
BA_ "GenMsgCycleTime" BO_ 906 100;
BA_ "GenMsgSendType" BO_ 906 0;
BA_ "GenMsgStartValue" BO_ 906 "00000000000000000402000000000000";
BA_ "PduName" BO_ 906 "ICBVC_100ms_PDU25";
BA_ "VFrameFormat" BO_ 906 14;
BA_ "FrameTriggeringName" BO_ 932 "ICBVC_BKPCANFD_100ms_FrP26";
BA_ "GenMsgCycleTime" BO_ 932 100;
BA_ "GenMsgSendType" BO_ 932 0;
BA_ "GenMsgStartValue" BO_ 932 "0000000000000000";
BA_ "PduName" BO_ 932 "ICBVC_100ms_PDU26";
BA_ "VFrameFormat" BO_ 932 14;
BA_ "FrameTriggeringName" BO_ 830 "ICBVC_BKPCANFD_100ms_FrP30";
BA_ "GenMsgCycleTime" BO_ 830 100;
BA_ "GenMsgSendType" BO_ 830 0;
BA_ "GenMsgStartValue" BO_ 830 "0000000000000000";
BA_ "PduName" BO_ 830 "ICBVC_100ms_PDU30";
BA_ "VFrameFormat" BO_ 830 14;
BA_ "FrameTriggeringName" BO_ 1104 "ICBVC_BKPCANFD_100ms_FrP31";
BA_ "GenMsgCycleTime" BO_ 1104 100;
BA_ "GenMsgSendType" BO_ 1104 0;
BA_ "GenMsgStartValue" BO_ 1104 "0000000000000000000000000000000000000000";
BA_ "PduName" BO_ 1104 "ICBVC_100ms_PDU31";
BA_ "VFrameFormat" BO_ 1104 14;
BA_ "FrameTriggeringName" BO_ 832 "ICBVC_BKPCANFD_100ms_FrP35";
BA_ "GenMsgCycleTime" BO_ 832 100;
BA_ "GenMsgSendType" BO_ 832 0;
BA_ "GenMsgStartValue" BO_ 832 "0000000000000000";
BA_ "PduName" BO_ 832 "ICBVC_100ms_PDU35";
BA_ "VFrameFormat" BO_ 832 14;
BA_ "FrameTriggeringName" BO_ 836 "ICBVC_BKPCANFD_100ms_FrP36";
BA_ "GenMsgCycleTime" BO_ 836 100;
BA_ "GenMsgSendType" BO_ 836 0;
BA_ "GenMsgStartValue" BO_ 836 "0000000000000000";
BA_ "PduName" BO_ 836 "ICBVC_100ms_PDU36";
BA_ "VFrameFormat" BO_ 836 14;
BA_ "FrameTriggeringName" BO_ 1007 "ICBVC_BKPCANFD_100ms_FrP68";
BA_ "GenMsgCycleTime" BO_ 1007 100;
BA_ "GenMsgSendType" BO_ 1007 0;
BA_ "GenMsgStartValue" BO_ 1007 "0000000000000000";
BA_ "PduName" BO_ 1007 "ICBVC_100ms_PDU68";
BA_ "VFrameFormat" BO_ 1007 14;
BA_ "FrameTriggeringName" BO_ 868 "ICBVC_BKPCANFD_100ms_FrP69";
BA_ "GenMsgCycleTime" BO_ 868 100;
BA_ "GenMsgSendType" BO_ 868 0;
BA_ "GenMsgStartValue" BO_ 868 "0000000000000000";
BA_ "PduName" BO_ 868 "ICBVC_100ms_PDU69";
BA_ "VFrameFormat" BO_ 868 14;
BA_ "FrameTriggeringName" BO_ 827 "ICBVC_BKPCANFD_100ms_FrP70";
BA_ "GenMsgCycleTime" BO_ 827 100;
BA_ "GenMsgSendType" BO_ 827 0;
BA_ "GenMsgStartValue" BO_ 827 "0000000000000000";
BA_ "PduName" BO_ 827 "ICBVC_100ms_PDU70";
BA_ "VFrameFormat" BO_ 827 14;
BA_ "FrameTriggeringName" BO_ 828 "ICBVC_BKPCANFD_100ms_FrP71";
BA_ "GenMsgCycleTime" BO_ 828 100;
BA_ "GenMsgSendType" BO_ 828 0;
BA_ "GenMsgStartValue" BO_ 828 "0000000000000000";
BA_ "PduName" BO_ 828 "ICBVC_100ms_PDU71";
BA_ "VFrameFormat" BO_ 828 14;
BA_ "FrameTriggeringName" BO_ 683 "ICBVC_BKPCANFD_100ms_FrP72";
BA_ "GenMsgCycleTime" BO_ 683 100;
BA_ "GenMsgSendType" BO_ 683 0;
BA_ "GenMsgStartValue" BO_ 683 "000000000000000000000000";
BA_ "PduName" BO_ 683 "ICBVC_100ms_PDU72";
BA_ "VFrameFormat" BO_ 683 14;
BA_ "FrameTriggeringName" BO_ 824 "ICBVC_BKPCANFD_100ms_FrP73";
BA_ "GenMsgCycleTime" BO_ 824 100;
BA_ "GenMsgSendType" BO_ 824 0;
BA_ "GenMsgStartValue" BO_ 824 "0000000000000000";
BA_ "PduName" BO_ 824 "ICBVC_100ms_PDU73";
BA_ "VFrameFormat" BO_ 824 14;
BA_ "FrameTriggeringName" BO_ 826 "ICBVC_BKPCANFD_100ms_FrP74";
BA_ "GenMsgCycleTime" BO_ 826 100;
BA_ "GenMsgSendType" BO_ 826 0;
BA_ "GenMsgStartValue" BO_ 826 "0000000000000000";
BA_ "PduName" BO_ 826 "ICBVC_100ms_PDU74";
BA_ "VFrameFormat" BO_ 826 14;
BA_ "FrameTriggeringName" BO_ 823 "ICBVC_BKPCANFD_100ms_FrP75";
BA_ "GenMsgCycleTime" BO_ 823 100;
BA_ "GenMsgSendType" BO_ 823 0;
BA_ "GenMsgStartValue" BO_ 823 "0000000000000000";
BA_ "PduName" BO_ 823 "ICBVC_100ms_PDU75";
BA_ "VFrameFormat" BO_ 823 14;
BA_ "FrameTriggeringName" BO_ 825 "ICBVC_BKPCANFD_100ms_FrP77";
BA_ "GenMsgCycleTime" BO_ 825 100;
BA_ "GenMsgSendType" BO_ 825 0;
BA_ "GenMsgStartValue" BO_ 825 "0000000000000000";
BA_ "PduName" BO_ 825 "ICBVC_100ms_PDU77";
BA_ "VFrameFormat" BO_ 825 14;
BA_ "FrameTriggeringName" BO_ 901 "ICBVC_BKPCANFD_100ms_FrP78";
BA_ "GenMsgCycleTime" BO_ 901 100;
BA_ "GenMsgSendType" BO_ 901 0;
BA_ "GenMsgStartValue" BO_ 901 "0030ffff3fffffff";
BA_ "PduName" BO_ 901 "ICBVC_100ms_PDU78";
BA_ "VFrameFormat" BO_ 901 14;
BA_ "FrameTriggeringName" BO_ 292 "ICBVC_BKPCANFD_20ms_FrP06";
BA_ "GenMsgCycleTime" BO_ 292 20;
BA_ "GenMsgSendType" BO_ 292 0;
BA_ "GenMsgStartValue" BO_ 292 "0000000000000008";
BA_ "PduName" BO_ 292 "ICBVC_20ms_PDU06";
BA_ "VFrameFormat" BO_ 292 14;
BA_ "FrameTriggeringName" BO_ 482 "ICBVC_BKPCANFD_50ms_FrP11";
BA_ "GenMsgCycleTime" BO_ 482 50;
BA_ "GenMsgSendType" BO_ 482 0;
BA_ "GenMsgStartValue" BO_ 482 "00f0ffff01ffffff";
BA_ "PduName" BO_ 482 "ICBVC_50ms_PDU11";
BA_ "VFrameFormat" BO_ 482 14;
BA_ "CompuMethodName" SG_ 859 ISpdLmtMdResp "SpdLmtMdResp";
BA_ "ISignalName" SG_ 859 ISpdLmtMdResp "ISpdLmtMdResp";
BA_ "LongName" SG_ 859 ISpdLmtMdResp "Speed Limit Mode Response";
BA_ "SysSignalName" SG_ 859 ISpdLmtMdResp "SpdLmtMdResp";
BA_ "CompuMethodName" SG_ 859 IAutoMainBeamLghtReq "AutoMainBeamLghtReq";
BA_ "ISignalName" SG_ 859 IAutoMainBeamLghtReq "IAutoMainBeamLghtReq";
BA_ "LongName" SG_ 859 IAutoMainBeamLghtReq "Auto Main Beam Light Request";
BA_ "SysSignalName" SG_ 859 IAutoMainBeamLghtReq "AutoMainBeamLghtReq";
BA_ "CompuMethodName" SG_ 895 INarwSpcAstSwSts "NarwSpcAstSwSts";
BA_ "GenSigStartValue" SG_ 895 INarwSpcAstSwSts 2;
BA_ "ISignalName" SG_ 895 INarwSpcAstSwSts "INarwSpcAstSwSts";
BA_ "LongName" SG_ 895 INarwSpcAstSwSts "Narrow Space Assist Switch Status";
BA_ "SysSignalName" SG_ 895 INarwSpcAstSwSts "NarwSpcAstSwSts";
BA_ "CompuMethodName" SG_ 895 INarwSpcAstBtnSts "NarwSpcAstBtnSts";
BA_ "ISignalName" SG_ 895 INarwSpcAstBtnSts "INarwSpcAstBtnSts";
BA_ "LongName" SG_ 895 INarwSpcAstBtnSts "Narrow Space Assist Button Status";
BA_ "SysSignalName" SG_ 895 INarwSpcAstBtnSts "NarwSpcAstBtnSts";
BA_ "CompuMethodName" SG_ 895 IIPD_VehLckCtrlReq "IPD_VehLckCtrlReq";
BA_ "ISignalName" SG_ 895 IIPD_VehLckCtrlReq "IIPD_VehLckCtrlReq";
BA_ "LongName" SG_ 895 IIPD_VehLckCtrlReq "Vehicle lock request";
BA_ "SysSignalName" SG_ 895 IIPD_VehLckCtrlReq "IPD_VehLckCtrlReq";
BA_ "CompuMethodName" SG_ 895 IRembParkngInPrmt "RembParkngInPrmt";
BA_ "ISignalName" SG_ 895 IRembParkngInPrmt "IRembParkngInPrmt";
BA_ "LongName" SG_ 895 IRembParkngInPrmt "Remember Parking In Prompt";
BA_ "SysSignalName" SG_ 895 IRembParkngInPrmt "RembParkngInPrmt";
BA_ "CompuMethodName" SG_ 895 IRembParkngInMapngResp "RembParkngInMapngResp";
BA_ "ISignalName" SG_ 895 IRembParkngInMapngResp "IRembParkngInMapngResp";
BA_ "LongName" SG_ 895 IRembParkngInMapngResp "Remember Parking In Mapping Response";
BA_ "SysSignalName" SG_ 895 IRembParkngInMapngResp "RembParkngInMapngResp";
BA_ "CompuMethodName" SG_ 895 IRembParkngInPrmtSwSts "RembParkngInPrmtSwSts";
BA_ "GenSigStartValue" SG_ 895 IRembParkngInPrmtSwSts 1;
BA_ "ISignalName" SG_ 895 IRembParkngInPrmtSwSts "IRembParkngInPrmtSwSts";
BA_ "LongName" SG_ 895 IRembParkngInPrmtSwSts "Remember Parking In Prompt Switch Status";
BA_ "SysSignalName" SG_ 895 IRembParkngInPrmtSwSts "RembParkngInPrmtSwSts";
BA_ "CompuMethodName" SG_ 895 IRembParkngInMapngIndcr "RembParkngInMapngIndcr";
BA_ "ISignalName" SG_ 895 IRembParkngInMapngIndcr "IRembParkngInMapngIndcr";
BA_ "LongName" SG_ 895 IRembParkngInMapngIndcr "Remember Parking In Mapping Indicator";
BA_ "SysSignalName" SG_ 895 IRembParkngInMapngIndcr "RembParkngInMapngIndcr";
BA_ "CompuMethodName" SG_ 895 IRembParkngInMapRutSeln "RembParkngInMapRutSeln";
BA_ "ISignalName" SG_ 895 IRembParkngInMapRutSeln "IRembParkngInMapRutSeln";
BA_ "LongName" SG_ 895 IRembParkngInMapRutSeln "Remember Parking In Map Route Selection";
BA_ "SysSignalName" SG_ 895 IRembParkngInMapRutSeln "RembParkngInMapRutSeln";
BA_ "CompuMethodName" SG_ 895 IIPDMCUTemp "IPDMCUTemp";
BA_ "GenSigStartValue" SG_ 895 IIPDMCUTemp 255;
BA_ "ISignalName" SG_ 895 IIPDMCUTemp "IIPDMCUTemp";
BA_ "LongName" SG_ 895 IIPDMCUTemp "IPD MCU Temperature";
BA_ "SysSignalName" SG_ 895 IIPDMCUTemp "IPDMCUTemp";
BA_ "CompuMethodName" SG_ 895 IIPDWtrClntInltReqFlg "IPDWtrClntInltReqFlg";
BA_ "ISignalName" SG_ 895 IIPDWtrClntInltReqFlg "IIPDWtrClntInltReqFlg";
BA_ "LongName" SG_ 895 IIPDWtrClntInltReqFlg "IPD_water_coolant_inlet_request_flag";
BA_ "SysSignalName" SG_ 895 IIPDWtrClntInltReqFlg "IPDWtrClntInltReqFlg";
BA_ "CompuMethodName" SG_ 895 ITrfGreenLghtActn "TrfGreenLghtActn";
BA_ "ISignalName" SG_ 895 ITrfGreenLghtActn "ITrfGreenLghtActn";
BA_ "LongName" SG_ 895 ITrfGreenLghtActn "Traffic Green Light Attention";
BA_ "SysSignalName" SG_ 895 ITrfGreenLghtActn "TrfGreenLghtActn";
BA_ "CompuMethodName" SG_ 895 IRembParkngInMapngRutID "RembParkngInMapngRutID";
BA_ "ISignalName" SG_ 895 IRembParkngInMapngRutID "IRembParkngInMapngRutID";
BA_ "LongName" SG_ 895 IRembParkngInMapngRutID "Remember Parking In Maping Route Id";
BA_ "SysSignalName" SG_ 895 IRembParkngInMapngRutID "RembParkngInMapngRutID";
BA_ "CompuMethodName" SG_ 895 IRembParkngInMapngDistToEnd "RembParkngInMapngDistToEnd";
BA_ "ISignalName" SG_ 895 IRembParkngInMapngDistToEnd "IRembParkngInMapngDistToEnd";
BA_ "LongName" SG_ 895 IRembParkngInMapngDistToEnd "Remember Parking In Mapping Distance To End";
BA_ "SysSignalName" SG_ 895 IRembParkngInMapngDistToEnd "RembParkngInMapngDistToEnd";
BA_ "CompuMethodName" SG_ 895 IRembParkngInMapRutDltSeln "RembParkngInMapRutDltSeln";
BA_ "ISignalName" SG_ 895 IRembParkngInMapRutDltSeln "IRembParkngInMapRutDltSeln";
BA_ "LongName" SG_ 895 IRembParkngInMapRutDltSeln "Remember Parking In Map Route Delete Selectio";
BA_ "SysSignalName" SG_ 895 IRembParkngInMapRutDltSeln "RembParkngInMapRutDltSeln";
BA_ "CompuMethodName" SG_ 820 IICBAD_100ms_Group37_CRC "ICBAD_100ms_Group37_CRC";
BA_ "ISignalName" SG_ 820 IICBAD_100ms_Group37_CRC "IICBAD_100ms_Group37_CRC";
BA_ "SysSignalName" SG_ 820 IICBAD_100ms_Group37_CRC "ICBAD_100ms_Group37_CRC";
BA_ "CompuMethodName" SG_ 820 IICBAD_100ms_Group37_RC "ICBAD_100ms_Group37_RC";
BA_ "ISignalName" SG_ 820 IICBAD_100ms_Group37_RC "IICBAD_100ms_Group37_RC";
BA_ "SysSignalName" SG_ 820 IICBAD_100ms_Group37_RC "ICBAD_100ms_Group37_RC";
BA_ "CompuMethodName" SG_ 820 IICBAD_100ms_Group37_Reserved1 "ICBAD_100ms_Group37_Reserved1";
BA_ "GenSigStartValue" SG_ 820 IICBAD_100ms_Group37_Reserved1 15;
BA_ "ISignalName" SG_ 820 IICBAD_100ms_Group37_Reserved1 "IICBAD_100ms_Group37_Reserved1";
BA_ "SysSignalName" SG_ 820 IICBAD_100ms_Group37_Reserved1 "ICBAD_100ms_Group37_Reserved1";
BA_ "CompuMethodName" SG_ 820 IICBAD_100ms_Group37_Reserved2 "ICBAD_100ms_Group37_Reserved2";
BA_ "GenSigStartValue" SG_ 820 IICBAD_100ms_Group37_Reserved2 63;
BA_ "ISignalName" SG_ 820 IICBAD_100ms_Group37_Reserved2 "IICBAD_100ms_Group37_Reserved2";
BA_ "SysSignalName" SG_ 820 IICBAD_100ms_Group37_Reserved2 "ICBAD_100ms_Group37_Reserved2";
BA_ "CompuMethodName" SG_ 820 IHzrdLampsCtrl "HzrdLampsCtrl";
BA_ "ISignalName" SG_ 820 IHzrdLampsCtrl "IHzrdLampsCtrl";
BA_ "LongName" SG_ 820 IHzrdLampsCtrl "Hazard Lamps Control";
BA_ "SysSignalName" SG_ 820 IHzrdLampsCtrl "HzrdLampsCtrl";
BA_ "CompuMethodName" SG_ 820 IDILampsCtrl "DILampsCtrl";
BA_ "ISignalName" SG_ 820 IDILampsCtrl "IDILampsCtrl";
BA_ "LongName" SG_ 820 IDILampsCtrl "Direction Lamps Control";
BA_ "SysSignalName" SG_ 820 IDILampsCtrl "DILampsCtrl";
BA_ "CompuMethodName" SG_ 820 IAutoLaneChngSetResp "AutoLaneChngSetResp";
BA_ "ISignalName" SG_ 820 IAutoLaneChngSetResp "IAutoLaneChngSetResp";
BA_ "LongName" SG_ 820 IAutoLaneChngSetResp "Auto Lane Change Set Response";
BA_ "SysSignalName" SG_ 820 IAutoLaneChngSetResp "AutoLaneChngSetResp";
BA_ "CompuMethodName" SG_ 820 IICBAD_100ms_Group37_Reserved3 "ICBAD_100ms_Group37_Reserved3";
BA_ "GenSigStartValue" SG_ 820 IICBAD_100ms_Group37_Reserved3 1;
BA_ "ISignalName" SG_ 820 IICBAD_100ms_Group37_Reserved3 "IICBAD_100ms_Group37_Reserved3";
BA_ "SysSignalName" SG_ 820 IICBAD_100ms_Group37_Reserved3 "ICBAD_100ms_Group37_Reserved3";
BA_ "CompuMethodName" SG_ 820 IAutoLaneChngSwDspCmd "AutoLaneChngSwDspCmd";
BA_ "ISignalName" SG_ 820 IAutoLaneChngSwDspCmd "IAutoLaneChngSwDspCmd";
BA_ "LongName" SG_ 820 IAutoLaneChngSwDspCmd "Auto_Lane_Change_Switch_Display_Command";
BA_ "SysSignalName" SG_ 820 IAutoLaneChngSwDspCmd "AutoLaneChngSwDspCmd";
BA_ "CompuMethodName" SG_ 820 IICBAD_100ms_Group37_Reserved4 "ICBAD_100ms_Group37_Reserved4";
BA_ "GenSigStartValue" SG_ 820 IICBAD_100ms_Group37_Reserved4 1;
BA_ "ISignalName" SG_ 820 IICBAD_100ms_Group37_Reserved4 "IICBAD_100ms_Group37_Reserved4";
BA_ "SysSignalName" SG_ 820 IICBAD_100ms_Group37_Reserved4 "ICBAD_100ms_Group37_Reserved4";
BA_ "CompuMethodName" SG_ 820 IAutoLaneChngMsgReq "AutoLaneChngMsgReq";
BA_ "ISignalName" SG_ 820 IAutoLaneChngMsgReq "IAutoLaneChngMsgReq";
BA_ "LongName" SG_ 820 IAutoLaneChngMsgReq "Auto Lane Change Message Request";
BA_ "SysSignalName" SG_ 820 IAutoLaneChngMsgReq "AutoLaneChngMsgReq";
BA_ "CompuMethodName" SG_ 820 IOtsdMirFoldReq "OtsdMirFoldReq";
BA_ "ISignalName" SG_ 820 IOtsdMirFoldReq "IOtsdMirFoldReq";
BA_ "LongName" SG_ 820 IOtsdMirFoldReq "Outside Mirror Fold Request";
BA_ "SysSignalName" SG_ 820 IOtsdMirFoldReq "OtsdMirFoldReq";
BA_ "CompuMethodName" SG_ 820 IICBAD_100ms_Group37_Reserved5 "ICBAD_100ms_Group37_Reserved5";
BA_ "GenSigStartValue" SG_ 820 IICBAD_100ms_Group37_Reserved5 255;
BA_ "ISignalName" SG_ 820 IICBAD_100ms_Group37_Reserved5 "IICBAD_100ms_Group37_Reserved5";
BA_ "SysSignalName" SG_ 820 IICBAD_100ms_Group37_Reserved5 "ICBAD_100ms_Group37_Reserved5";
BA_ "CompuMethodName" SG_ 820 IICBAD_100ms_Group37_Reserved6 "ICBAD_100ms_Group37_Reserved6";
BA_ "GenSigStartValue" SG_ 820 IICBAD_100ms_Group37_Reserved6 255;
BA_ "ISignalName" SG_ 820 IICBAD_100ms_Group37_Reserved6 "IICBAD_100ms_Group37_Reserved6";
BA_ "SysSignalName" SG_ 820 IICBAD_100ms_Group37_Reserved6 "ICBAD_100ms_Group37_Reserved6";
BA_ "CompuMethodName" SG_ 820 IICBAD_100ms_Group37_Reserved7 "ICBAD_100ms_Group37_Reserved7";
BA_ "GenSigStartValue" SG_ 820 IICBAD_100ms_Group37_Reserved7 255;
BA_ "ISignalName" SG_ 820 IICBAD_100ms_Group37_Reserved7 "IICBAD_100ms_Group37_Reserved7";
BA_ "SysSignalName" SG_ 820 IICBAD_100ms_Group37_Reserved7 "ICBAD_100ms_Group37_Reserved7";
BA_ "CompuMethodName" SG_ 1105 IELKSysSts "ELKSysSts";
BA_ "GenSigStartValue" SG_ 1105 IELKSysSts 1;
BA_ "ISignalName" SG_ 1105 IELKSysSts "IELKSysSts";
BA_ "LongName" SG_ 1105 IELKSysSts "ELK System Status";
BA_ "SysSignalName" SG_ 1105 IELKSysSts "ELKSysSts";
BA_ "CompuMethodName" SG_ 1105 IELKSysFltSts "ELKSysFltSts";
BA_ "ISignalName" SG_ 1105 IELKSysFltSts "IELKSysFltSts";
BA_ "LongName" SG_ 1105 IELKSysFltSts "Emergency_Lane_Keeping_System_Fault_Status from IPD";
BA_ "SysSignalName" SG_ 1105 IELKSysFltSts "ELKSysFltSts";
BA_ "CompuMethodName" SG_ 1105 IAIParkngSpdswSts "AIParkngSpdswSts";
BA_ "ISignalName" SG_ 1105 IAIParkngSpdswSts "IAIParkngSpdswSts";
BA_ "LongName" SG_ 1105 IAIParkngSpdswSts "Ai Parking Speed Switch Set Status";
BA_ "SysSignalName" SG_ 1105 IAIParkngSpdswSts "AIParkngSpdswSts";
BA_ "CompuMethodName" SG_ 1105 INrwroadFwdSta "NrwroadFwdSta";
BA_ "ISignalName" SG_ 1105 INrwroadFwdSta "INrwroadFwdSta";
BA_ "LongName" SG_ 1105 INrwroadFwdSta "Narrow Road Forward Switch Response Status";
BA_ "SysSignalName" SG_ 1105 INrwroadFwdSta "NrwroadFwdSta";
BA_ "CompuMethodName" SG_ 1105 INrwroadsltSta "NrwroadsltSta";
BA_ "ISignalName" SG_ 1105 INrwroadsltSta "INrwroadsltSta";
BA_ "LongName" SG_ 1105 INrwroadsltSta "Narrow Road Forward Silently Status";
BA_ "SysSignalName" SG_ 1105 INrwroadsltSta "NrwroadsltSta";
BA_ "CompuMethodName" SG_ 1105 IIPDELKDspCmd "IPDELKDspCmd";
BA_ "GenSigStartValue" SG_ 1105 IIPDELKDspCmd 2;
BA_ "ISignalName" SG_ 1105 IIPDELKDspCmd "IIPDELKDspCmd";
BA_ "LongName" SG_ 1105 IIPDELKDspCmd "Emergency_Lane_Keeping_Display_Command from IPD";
BA_ "SysSignalName" SG_ 1105 IIPDELKDspCmd "IPDELKDspCmd";
BA_ "CompuMethodName" SG_ 1105 IMemParkngStrtBtnSts "MemParkngStrtBtnSts";
BA_ "ISignalName" SG_ 1105 IMemParkngStrtBtnSts "IMemParkngStrtBtnSts";
BA_ "LongName" SG_ 1105 IMemParkngStrtBtnSts "Memory Parking Start Button State";
BA_ "SysSignalName" SG_ 1105 IMemParkngStrtBtnSts "MemParkngStrtBtnSts";
BA_ "CompuMethodName" SG_ 1105 IMemParkngBtnRcnm "MemParkngBtnRcnm";
BA_ "ISignalName" SG_ 1105 IMemParkngBtnRcnm "IMemParkngBtnRcnm";
BA_ "LongName" SG_ 1105 IMemParkngBtnRcnm "Memory Parking Button Recommand";
BA_ "SysSignalName" SG_ 1105 IMemParkngBtnRcnm "MemParkngBtnRcnm";
BA_ "CompuMethodName" SG_ 1105 IMemParkngBtnSts "MemParkngBtnSts";
BA_ "ISignalName" SG_ 1105 IMemParkngBtnSts "IMemParkngBtnSts";
BA_ "LongName" SG_ 1105 IMemParkngBtnSts "Memory Parking Button State";
BA_ "SysSignalName" SG_ 1105 IMemParkngBtnSts "MemParkngBtnSts";
BA_ "CompuMethodName" SG_ 1106 INarrowRoadForwardSts "NarrowRoadForwardSts";
BA_ "ISignalName" SG_ 1106 INarrowRoadForwardSts "INarrowRoadForwardSts";
BA_ "LongName" SG_ 1106 INarrowRoadForwardSts "Narrow Road Forward Switch Status";
BA_ "SysSignalName" SG_ 1106 INarrowRoadForwardSts "NarrowRoadForwardSts";
BA_ "CompuMethodName" SG_ 1106 INarrowRoadBackwardSts "NarrowRoadBackwardSts";
BA_ "ISignalName" SG_ 1106 INarrowRoadBackwardSts "INarrowRoadBackwardSts";
BA_ "LongName" SG_ 1106 INarrowRoadBackwardSts "Narrow Road Backward Status";
BA_ "SysSignalName" SG_ 1106 INarrowRoadBackwardSts "NarrowRoadBackwardSts";
BA_ "CompuMethodName" SG_ 1106 ITrfcLghtStSp "TrfcLghtStSp";
BA_ "ISignalName" SG_ 1106 ITrfcLghtStSp "ITrfcLghtStSp";
BA_ "LongName" SG_ 1106 ITrfcLghtStSp "Traffic Light Start/Stop Status";
BA_ "SysSignalName" SG_ 1106 ITrfcLghtStSp "TrfcLghtStSp";
BA_ "CompuMethodName" SG_ 151 IAIParkngEPAMdsts "AIParkngEPAMdsts";
BA_ "ISignalName" SG_ 151 IAIParkngEPAMdsts "IAIParkngEPAMdsts";
BA_ "LongName" SG_ 151 IAIParkngEPAMdsts "AIParking Exterior Parking Assist Model Status";
BA_ "SysSignalName" SG_ 151 IAIParkngEPAMdsts "AIParkngEPAMdsts";
BA_ "CompuMethodName" SG_ 151 ID2DSwReqResps "D2DSwReqResps";
BA_ "ISignalName" SG_ 151 ID2DSwReqResps "ID2DSwReqResps";
BA_ "LongName" SG_ 151 ID2DSwReqResps "D2D Swicth Request Response";
BA_ "SysSignalName" SG_ 151 ID2DSwReqResps "D2DSwReqResps";
BA_ "CompuMethodName" SG_ 151 IFCTBSysFltSts "FCTBSysFltSts";
BA_ "ISignalName" SG_ 151 IFCTBSysFltSts "IFCTBSysFltSts";
BA_ "LongName" SG_ 151 IFCTBSysFltSts "FCTB System Fault status";
BA_ "SysSignalName" SG_ 151 IFCTBSysFltSts "FCTBSysFltSts";
BA_ "CompuMethodName" SG_ 151 ID2DPriETClanSwReqResps "D2DPriETClanSwReqResps";
BA_ "ISignalName" SG_ 151 ID2DPriETClanSwReqResps "ID2DPriETClanSwReqResps";
BA_ "LongName" SG_ 151 ID2DPriETClanSwReqResps "D2D Priority ETC Lane Switch Request Response";
BA_ "SysSignalName" SG_ 151 ID2DPriETClanSwReqResps "D2DPriETClanSwReqResps";
BA_ "CompuMethodName" SG_ 382 IICBAD_20ms_Group07_CRC "ICBAD_20ms_Group07_CRC";
BA_ "ISignalName" SG_ 382 IICBAD_20ms_Group07_CRC "IICBAD_20ms_Group07_CRC";
BA_ "SysSignalName" SG_ 382 IICBAD_20ms_Group07_CRC "ICBAD_20ms_Group07_CRC";
BA_ "CompuMethodName" SG_ 382 IICBAD_20ms_Group07_RC "ICBAD_20ms_Group07_RC";
BA_ "ISignalName" SG_ 382 IICBAD_20ms_Group07_RC "IICBAD_20ms_Group07_RC";
BA_ "SysSignalName" SG_ 382 IICBAD_20ms_Group07_RC "ICBAD_20ms_Group07_RC";
BA_ "CompuMethodName" SG_ 382 IACCSdslReq "ACCSdslReq";
BA_ "ISignalName" SG_ 382 IACCSdslReq "IACCSdslReq";
BA_ "LongName" SG_ 382 IACCSdslReq "Adaptive Cruise Control Standstill Request";
BA_ "SysSignalName" SG_ 382 IACCSdslReq "ACCSdslReq";
BA_ "CompuMethodName" SG_ 382 IACCGoReq "ACCGoReq";
BA_ "ISignalName" SG_ 382 IACCGoReq "IACCGoReq";
BA_ "LongName" SG_ 382 IACCGoReq "Adaptive Cruise Control Go Request";
BA_ "SysSignalName" SG_ 382 IACCGoReq "ACCGoReq";
BA_ "CompuMethodName" SG_ 382 IACCAccReqSts_CH "ACCAccReqSts_CH";
BA_ "ISignalName" SG_ 382 IACCAccReqSts_CH "IACCAccReqSts_CH";
BA_ "LongName" SG_ 382 IACCAccReqSts_CH "Adaptive Cruise Control Acceleration Request Status";
BA_ "SysSignalName" SG_ 382 IACCAccReqSts_CH "ACCAccReqSts_CH";
BA_ "CompuMethodName" SG_ 382 IACCAccReqVal "ACCAccReqVal";
BA_ "GenSigStartValue" SG_ 382 IACCAccReqVal 1713;
BA_ "ISignalName" SG_ 382 IACCAccReqVal "IACCAccReqVal";
BA_ "LongName" SG_ 382 IACCAccReqVal "Adaptive Cruise Control Acceleration Request Value";
BA_ "SysSignalName" SG_ 382 IACCAccReqVal "ACCAccReqVal";
BA_ "CompuMethodName" SG_ 382 IICBAD_20ms_Group07_Reserved1 "ICBAD_20ms_Group07_Reserved1";
BA_ "GenSigStartValue" SG_ 382 IICBAD_20ms_Group07_Reserved1 3;
BA_ "ISignalName" SG_ 382 IICBAD_20ms_Group07_Reserved1 "IICBAD_20ms_Group07_Reserved1";
BA_ "SysSignalName" SG_ 382 IICBAD_20ms_Group07_Reserved1 "ICBAD_20ms_Group07_Reserved1";
BA_ "CompuMethodName" SG_ 382 IACCSysFltSts "ACCSysFltSts";
BA_ "ISignalName" SG_ 382 IACCSysFltSts "IACCSysFltSts";
BA_ "LongName" SG_ 382 IACCSysFltSts "Adaptive Cruise Control System Fault Status";
BA_ "SysSignalName" SG_ 382 IACCSysFltSts "ACCSysFltSts";
BA_ "CompuMethodName" SG_ 382 IICBAD_20ms_Group07_Reserved3 "ICBAD_20ms_Group07_Reserved3";
BA_ "GenSigStartValue" SG_ 382 IICBAD_20ms_Group07_Reserved3 7;
BA_ "ISignalName" SG_ 382 IICBAD_20ms_Group07_Reserved3 "IICBAD_20ms_Group07_Reserved3";
BA_ "SysSignalName" SG_ 382 IICBAD_20ms_Group07_Reserved3 "ICBAD_20ms_Group07_Reserved3";
BA_ "CompuMethodName" SG_ 382 IACCSysSts "ACCSysSts";
BA_ "ISignalName" SG_ 382 IACCSysSts "IACCSysSts";
BA_ "LongName" SG_ 382 IACCSysSts "Adaptive Cruise Control System Status";
BA_ "SysSignalName" SG_ 382 IACCSysSts "ACCSysSts";
BA_ "CompuMethodName" SG_ 382 IICBAD_20ms_Group07_Reserved2 "ICBAD_20ms_Group07_Reserved2";
BA_ "GenSigStartValue" SG_ 382 IICBAD_20ms_Group07_Reserved2 3;
BA_ "ISignalName" SG_ 382 IICBAD_20ms_Group07_Reserved2 "IICBAD_20ms_Group07_Reserved2";
BA_ "SysSignalName" SG_ 382 IICBAD_20ms_Group07_Reserved2 "ICBAD_20ms_Group07_Reserved2";
BA_ "CompuMethodName" SG_ 382 IICBAD_20ms_Group07_Reserved4 "ICBAD_20ms_Group07_Reserved4";
BA_ "GenSigStartValue" SG_ 382 IICBAD_20ms_Group07_Reserved4 255;
BA_ "ISignalName" SG_ 382 IICBAD_20ms_Group07_Reserved4 "IICBAD_20ms_Group07_Reserved4";
BA_ "SysSignalName" SG_ 382 IICBAD_20ms_Group07_Reserved4 "ICBAD_20ms_Group07_Reserved4";
BA_ "CompuMethodName" SG_ 382 IICBAD_20ms_Group07_Reserved5 "ICBAD_20ms_Group07_Reserved5";
BA_ "GenSigStartValue" SG_ 382 IICBAD_20ms_Group07_Reserved5 255;
BA_ "ISignalName" SG_ 382 IICBAD_20ms_Group07_Reserved5 "IICBAD_20ms_Group07_Reserved5";
BA_ "SysSignalName" SG_ 382 IICBAD_20ms_Group07_Reserved5 "ICBAD_20ms_Group07_Reserved5";
BA_ "CompuMethodName" SG_ 382 IICBAD_20ms_Group07_Reserved6 "ICBAD_20ms_Group07_Reserved6";
BA_ "GenSigStartValue" SG_ 382 IICBAD_20ms_Group07_Reserved6 255;
BA_ "ISignalName" SG_ 382 IICBAD_20ms_Group07_Reserved6 "IICBAD_20ms_Group07_Reserved6";
BA_ "SysSignalName" SG_ 382 IICBAD_20ms_Group07_Reserved6 "ICBAD_20ms_Group07_Reserved6";
BA_ "CompuMethodName" SG_ 385 INSAReqAVMDis "NSAReqAVMDis";
BA_ "ISignalName" SG_ 385 INSAReqAVMDis "INSAReqAVMDis";
BA_ "LongName" SG_ 385 INSAReqAVMDis "NSA Request AVM Display";
BA_ "SysSignalName" SG_ 385 INSAReqAVMDis "NSAReqAVMDis";
BA_ "CompuMethodName" SG_ 385 INSADisFucSts "NSADisFucSts";
BA_ "ISignalName" SG_ 385 INSADisFucSts "INSADisFucSts";
BA_ "LongName" SG_ 385 INSADisFucSts "NSA Display Function Status";
BA_ "SysSignalName" SG_ 385 INSADisFucSts "NSADisFucSts";
BA_ "CompuMethodName" SG_ 385 INSABacSysSts "NSABacSysSts";
BA_ "ISignalName" SG_ 385 INSABacSysSts "INSABacSysSts";
BA_ "LongName" SG_ 385 INSABacSysSts "NSA Backward Systerm Status";
BA_ "SysSignalName" SG_ 385 INSABacSysSts "NSABacSysSts";
BA_ "CompuMethodName" SG_ 385 INSAForSysSts "NSAForSysSts";
BA_ "ISignalName" SG_ 385 INSAForSysSts "INSAForSysSts";
BA_ "LongName" SG_ 385 INSAForSysSts "NSA Forward Systerm Status";
BA_ "SysSignalName" SG_ 385 INSAForSysSts "NSAForSysSts";
BA_ "CompuMethodName" SG_ 385 IILDP_ELKWrnng "ILDP_ELKWrnng";
BA_ "ISignalName" SG_ 385 IILDP_ELKWrnng "IILDP_ELKWrnng";
BA_ "LongName" SG_ 385 IILDP_ELKWrnng "LDP ELK Warning Status";
BA_ "SysSignalName" SG_ 385 IILDP_ELKWrnng "ILDP_ELKWrnng";
BA_ "CompuMethodName" SG_ 736 IFrtObsDist "FrtObsDist";
BA_ "ISignalName" SG_ 736 IFrtObsDist "IFrtObsDist";
BA_ "LongName" SG_ 736 IFrtObsDist "Front Obstacle Distance";
BA_ "SysSignalName" SG_ 736 IFrtObsDist "FrtObsDist";
BA_ "CompuMethodName" SG_ 736 IFrtMidRObsRng "FrtMidRObsRng";
BA_ "ISignalName" SG_ 736 IFrtMidRObsRng "IFrtMidRObsRng";
BA_ "LongName" SG_ 736 IFrtMidRObsRng "Front Middle Right Obstacle Range";
BA_ "SysSignalName" SG_ 736 IFrtMidRObsRng "FrtMidRObsRng";
BA_ "CompuMethodName" SG_ 736 IFrtPDCAudWrnng "FrtPDCAudWrnng";
BA_ "ISignalName" SG_ 736 IFrtPDCAudWrnng "IFrtPDCAudWrnng";
BA_ "LongName" SG_ 736 IFrtPDCAudWrnng "Front Park Distance Control Audible Warning";
BA_ "SysSignalName" SG_ 736 IFrtPDCAudWrnng "FrtPDCAudWrnng";
BA_ "CompuMethodName" SG_ 736 IRrMidLObsRng "RrMidLObsRng";
BA_ "ISignalName" SG_ 736 IRrMidLObsRng "IRrMidLObsRng";
BA_ "LongName" SG_ 736 IRrMidLObsRng "Rear Middle Left Obstacle Range";
BA_ "SysSignalName" SG_ 736 IRrMidLObsRng "RrMidLObsRng";
BA_ "CompuMethodName" SG_ 736 IRLObsRng "RLObsRng";
BA_ "ISignalName" SG_ 736 IRLObsRng "IRLObsRng";
BA_ "LongName" SG_ 736 IRLObsRng "Rear Left Obstacle Range";
BA_ "SysSignalName" SG_ 736 IRLObsRng "RLObsRng";
BA_ "CompuMethodName" SG_ 736 IRrMidRObsRng "RrMidRObsRng";
BA_ "ISignalName" SG_ 736 IRrMidRObsRng "IRrMidRObsRng";
BA_ "LongName" SG_ 736 IRrMidRObsRng "Rear Middle Right Obstacle Range";
BA_ "SysSignalName" SG_ 736 IRrMidRObsRng "RrMidRObsRng";
BA_ "CompuMethodName" SG_ 736 IPDCSysSts "PDCSysSts";
BA_ "ISignalName" SG_ 736 IPDCSysSts "IPDCSysSts";
BA_ "LongName" SG_ 736 IPDCSysSts "Park Distance Control System Status";
BA_ "SysSignalName" SG_ 736 IPDCSysSts "PDCSysSts";
BA_ "CompuMethodName" SG_ 736 IRrObsDist "RrObsDist";
BA_ "ISignalName" SG_ 736 IRrObsDist "IRrObsDist";
BA_ "LongName" SG_ 736 IRrObsDist "Rear Obstacle Distance";
BA_ "SysSignalName" SG_ 736 IRrObsDist "RrObsDist";
BA_ "CompuMethodName" SG_ 736 IFLSideObsRng "FLSideObsRng";
BA_ "ISignalName" SG_ 736 IFLSideObsRng "IFLSideObsRng";
BA_ "LongName" SG_ 736 IFLSideObsRng "Front Left Side Obstacle Range";
BA_ "SysSignalName" SG_ 736 IFLSideObsRng "FLSideObsRng";
BA_ "CompuMethodName" SG_ 736 IRrPDCAudWrnng "RrPDCAudWrnng";
BA_ "ISignalName" SG_ 736 IRrPDCAudWrnng "IRrPDCAudWrnng";
BA_ "LongName" SG_ 736 IRrPDCAudWrnng "Rear Park Distance Control Audible Warning";
BA_ "SysSignalName" SG_ 736 IRrPDCAudWrnng "RrPDCAudWrnng";
BA_ "CompuMethodName" SG_ 736 IRLSideObsRng "RLSideObsRng";
BA_ "ISignalName" SG_ 736 IRLSideObsRng "IRLSideObsRng";
BA_ "LongName" SG_ 736 IRLSideObsRng "Rear Left Side Obstacle Range";
BA_ "SysSignalName" SG_ 736 IRLSideObsRng "RLSideObsRng";
BA_ "CompuMethodName" SG_ 736 IFRSideObsRng "FRSideObsRng";
BA_ "ISignalName" SG_ 736 IFRSideObsRng "IFRSideObsRng";
BA_ "LongName" SG_ 736 IFRSideObsRng "Front Right Side Obstacle Range";
BA_ "SysSignalName" SG_ 736 IFRSideObsRng "FRSideObsRng";
BA_ "CompuMethodName" SG_ 736 IUndergndParkngGrgSts "UndergndParkngGrgSts";
BA_ "ISignalName" SG_ 736 IUndergndParkngGrgSts "IUndergndParkngGrgSts";
BA_ "LongName" SG_ 736 IUndergndParkngGrgSts "Underground Parking Garage Status";
BA_ "SysSignalName" SG_ 736 IUndergndParkngGrgSts "UndergndParkngGrgSts";
BA_ "CompuMethodName" SG_ 736 IRRSideObsRng "RRSideObsRng";
BA_ "ISignalName" SG_ 736 IRRSideObsRng "IRRSideObsRng";
BA_ "LongName" SG_ 736 IRRSideObsRng "Rear Right Side Obstacle Range";
BA_ "SysSignalName" SG_ 736 IRRSideObsRng "RRSideObsRng";
BA_ "CompuMethodName" SG_ 736 IFLObsRng "FLObsRng";
BA_ "ISignalName" SG_ 736 IFLObsRng "IFLObsRng";
BA_ "LongName" SG_ 736 IFLObsRng "Front Left Obstacle Range";
BA_ "SysSignalName" SG_ 736 IFLObsRng "FLObsRng";
BA_ "CompuMethodName" SG_ 736 IRRObsRng "RRObsRng";
BA_ "ISignalName" SG_ 736 IRRObsRng "IRRObsRng";
BA_ "LongName" SG_ 736 IRRObsRng "Rear Right Obstacle Range";
BA_ "SysSignalName" SG_ 736 IRRObsRng "RRObsRng";
BA_ "CompuMethodName" SG_ 736 IFRObsRng "FRObsRng";
BA_ "ISignalName" SG_ 736 IFRObsRng "IFRObsRng";
BA_ "LongName" SG_ 736 IFRObsRng "Front Right Obstacle Range";
BA_ "SysSignalName" SG_ 736 IFRObsRng "FRObsRng";
BA_ "CompuMethodName" SG_ 736 ILADSAFnInd "LADSAFnInd";
BA_ "ISignalName" SG_ 736 ILADSAFnInd "ILADSAFnInd";
BA_ "LongName" SG_ 736 ILADSAFnInd "Advanced Park Assist Active Function Indication";
BA_ "SysSignalName" SG_ 736 ILADSAFnInd "LADSAFnInd";
BA_ "CompuMethodName" SG_ 736 IFrtMidLObsRng "FrtMidLObsRng";
BA_ "ISignalName" SG_ 736 IFrtMidLObsRng "IFrtMidLObsRng";
BA_ "LongName" SG_ 736 IFrtMidLObsRng "Front Middle Left Obstacle Range";
BA_ "SysSignalName" SG_ 736 IFrtMidLObsRng "FrtMidLObsRng";
BA_ "CompuMethodName" SG_ 736 IFRSObsRng "FRSObsRng";
BA_ "ISignalName" SG_ 736 IFRSObsRng "IFRSObsRng";
BA_ "LongName" SG_ 736 IFRSObsRng "Front Right Side Obstacle Range";
BA_ "SysSignalName" SG_ 736 IFRSObsRng "FRSObsRng";
BA_ "CompuMethodName" SG_ 736 IFLSObsRng "FLSObsRng";
BA_ "ISignalName" SG_ 736 IFLSObsRng "IFLSObsRng";
BA_ "LongName" SG_ 736 IFLSObsRng "Front Left Side Obstacle Range";
BA_ "SysSignalName" SG_ 736 IFLSObsRng "FLSObsRng";
BA_ "CompuMethodName" SG_ 736 IRRSObsRng "RRSObsRng";
BA_ "ISignalName" SG_ 736 IRRSObsRng "IRRSObsRng";
BA_ "LongName" SG_ 736 IRRSObsRng "Rear Right Side Obstacle Range";
BA_ "SysSignalName" SG_ 736 IRRSObsRng "RRSObsRng";
BA_ "CompuMethodName" SG_ 736 IRLSObsRng "RLSObsRng";
BA_ "ISignalName" SG_ 736 IRLSObsRng "IRLSObsRng";
BA_ "LongName" SG_ 736 IRLSObsRng "Rear Left Side Obstacle Range";
BA_ "SysSignalName" SG_ 736 IRLSObsRng "RLSObsRng";
BA_ "CompuMethodName" SG_ 314 ID2DSysSts "D2DSysSts";
BA_ "ISignalName" SG_ 314 ID2DSysSts "ID2DSysSts";
BA_ "LongName" SG_ 314 ID2DSysSts "D2D System Status";
BA_ "SysSignalName" SG_ 314 ID2DSysSts "D2DSysSts";
BA_ "CompuMethodName" SG_ 50 IIPDTripCntResetResp "IPDTripCntResetResp";
BA_ "ISignalName" SG_ 50 IIPDTripCntResetResp "IIPDTripCntResetResp";
BA_ "LongName" SG_ 50 IIPDTripCntResetResp "IPD Trip Counter Reset Response";
BA_ "SysSignalName" SG_ 50 IIPDTripCntResetResp "IPDTripCntResetResp";
BA_ "CompuMethodName" SG_ 178 IIPDDataId "IPDDataId";
BA_ "ISignalName" SG_ 178 IIPDDataId "IIPDDataId";
BA_ "LongName" SG_ 178 IIPDDataId "IPDDataId";
BA_ "SysSignalName" SG_ 178 IIPDDataId "IPDDataId";
BA_ "CompuMethodName" SG_ 178 IIPDAlgFlag "IPDAlgFlag";
BA_ "ISignalName" SG_ 178 IIPDAlgFlag "IIPDAlgFlag";
BA_ "LongName" SG_ 178 IIPDAlgFlag "IPDAlgorismFlag";
BA_ "SysSignalName" SG_ 178 IIPDAlgFlag "IPDAlgFlag";
BA_ "CompuMethodName" SG_ 178 IIPDFailedReason "IPDFailedReason";
BA_ "ISignalName" SG_ 178 IIPDFailedReason "IIPDFailedReason";
BA_ "LongName" SG_ 178 IIPDFailedReason "IPDFailedReason";
BA_ "SysSignalName" SG_ 178 IIPDFailedReason "IPDFailedReason";
BA_ "CompuMethodName" SG_ 178 IIPDErrorCount "IPDErrorCount";
BA_ "ISignalName" SG_ 178 IIPDErrorCount "IIPDErrorCount";
BA_ "LongName" SG_ 178 IIPDErrorCount "IPDErrorCount";
BA_ "SysSignalName" SG_ 178 IIPDErrorCount "IPDErrorCount";
BA_ "CompuMethodName" SG_ 178 IIPDTripNvmTag "IPDTripNvmTag";
BA_ "ISignalName" SG_ 178 IIPDTripNvmTag "IIPDTripNvmTag";
BA_ "LongName" SG_ 178 IIPDTripNvmTag "IPDTripNvmTag";
BA_ "SysSignalName" SG_ 178 IIPDTripNvmTag "IPDTripNvmTag";
BA_ "CompuMethodName" SG_ 178 IIPDResetCnt "IPDResetCnt";
BA_ "ISignalName" SG_ 178 IIPDResetCnt "IIPDResetCnt";
BA_ "LongName" SG_ 178 IIPDResetCnt "IPDResetCounter";
BA_ "SysSignalName" SG_ 178 IIPDResetCnt "IPDResetCnt";
BA_ "CompuMethodName" SG_ 178 IIPDKeyStatus "IPDKeyStatus";
BA_ "ISignalName" SG_ 178 IIPDKeyStatus "IIPDKeyStatus";
BA_ "LongName" SG_ 178 IIPDKeyStatus "IPDKeyStatus";
BA_ "SysSignalName" SG_ 178 IIPDKeyStatus "IPDKeyStatus";
BA_ "CompuMethodName" SG_ 178 IIPDTripCnt "IPDTripCnt";
BA_ "ISignalName" SG_ 178 IIPDTripCnt "IIPDTripCnt";
BA_ "LongName" SG_ 178 IIPDTripCnt "IPDTripCounter";
BA_ "SysSignalName" SG_ 178 IIPDTripCnt "IPDTripCnt";
BA_ "CompuMethodName" SG_ 81 IICBAD_ZONE_20ms_Group13_CRC "ICBAD_ZONE_20ms_Group13_CRC";
BA_ "ISignalName" SG_ 81 IICBAD_ZONE_20ms_Group13_CRC "IICBAD_ZONE_20ms_Group13_CRC";
BA_ "SysSignalName" SG_ 81 IICBAD_ZONE_20ms_Group13_CRC "ICBAD_ZONE_20ms_Group13_CRC";
BA_ "CompuMethodName" SG_ 81 IICBAD_ZONE_20ms_Group13_RC "ICBAD_ZONE_20ms_Group13_RC";
BA_ "ISignalName" SG_ 81 IICBAD_ZONE_20ms_Group13_RC "IICBAD_ZONE_20ms_Group13_RC";
BA_ "SysSignalName" SG_ 81 IICBAD_ZONE_20ms_Group13_RC "ICBAD_ZONE_20ms_Group13_RC";
BA_ "CompuMethodName" SG_ 81 IICBAD_ZONE_20ms_Group13_Reserve0 "ICBAD_ZONE_20ms_Group13_Reserved1";
BA_ "GenSigStartValue" SG_ 81 IICBAD_ZONE_20ms_Group13_Reserve0 1;
BA_ "ISignalName" SG_ 81 IICBAD_ZONE_20ms_Group13_Reserve0 "IICBAD_ZONE_20ms_Group13_Reserved1";
BA_ "SysSignalName" SG_ 81 IICBAD_ZONE_20ms_Group13_Reserve0 "ICBAD_ZONE_20ms_Group13_Reserved1";
BA_ "SystemSignalLongSymbol" SG_ 81 IICBAD_ZONE_20ms_Group13_Reserve0 "IICBAD_ZONE_20ms_Group13_Reserved1";
BA_ "CompuMethodName" SG_ 81 ITJAICASysFltSts "TJAICASysFltSts";
BA_ "ISignalName" SG_ 81 ITJAICASysFltSts "ITJAICASysFltSts";
BA_ "LongName" SG_ 81 ITJAICASysFltSts "Traffic Jam Assist Integrated Cruise Assist Fault Status";
BA_ "SysSignalName" SG_ 81 ITJAICASysFltSts "TJAICASysFltSts";
BA_ "CompuMethodName" SG_ 81 IICBAD_ZONE_20ms_Group13_Reserve1 "ICBAD_ZONE_20ms_Group13_Reserved3";
BA_ "GenSigStartValue" SG_ 81 IICBAD_ZONE_20ms_Group13_Reserve1 3;
BA_ "ISignalName" SG_ 81 IICBAD_ZONE_20ms_Group13_Reserve1 "IICBAD_ZONE_20ms_Group13_Reserved3";
BA_ "SysSignalName" SG_ 81 IICBAD_ZONE_20ms_Group13_Reserve1 "ICBAD_ZONE_20ms_Group13_Reserved3";
BA_ "SystemSignalLongSymbol" SG_ 81 IICBAD_ZONE_20ms_Group13_Reserve1 "IICBAD_ZONE_20ms_Group13_Reserved3";
BA_ "CompuMethodName" SG_ 81 ILKASysFltSts "LKASysFltSts";
BA_ "ISignalName" SG_ 81 ILKASysFltSts "ILKASysFltSts";
BA_ "LongName" SG_ 81 ILKASysFltSts "Lane Keeping Assist System Fault Status";
BA_ "SysSignalName" SG_ 81 ILKASysFltSts "LKASysFltSts";
BA_ "CompuMethodName" SG_ 81 IICBAD_ZONE_20ms_Group13_Reserve2 "ICBAD_ZONE_20ms_Group13_Reserved2";
BA_ "GenSigStartValue" SG_ 81 IICBAD_ZONE_20ms_Group13_Reserve2 7;
BA_ "ISignalName" SG_ 81 IICBAD_ZONE_20ms_Group13_Reserve2 "IICBAD_ZONE_20ms_Group13_Reserved2";
BA_ "SysSignalName" SG_ 81 IICBAD_ZONE_20ms_Group13_Reserve2 "ICBAD_ZONE_20ms_Group13_Reserved2";
BA_ "SystemSignalLongSymbol" SG_ 81 IICBAD_ZONE_20ms_Group13_Reserve2 "IICBAD_ZONE_20ms_Group13_Reserved2";
BA_ "CompuMethodName" SG_ 81 IICBAD_ZONE_20ms_Group13_Reserve3 "ICBAD_ZONE_20ms_Group13_Reserved4";
BA_ "GenSigStartValue" SG_ 81 IICBAD_ZONE_20ms_Group13_Reserve3 3;
BA_ "ISignalName" SG_ 81 IICBAD_ZONE_20ms_Group13_Reserve3 "IICBAD_ZONE_20ms_Group13_Reserved4";
BA_ "SysSignalName" SG_ 81 IICBAD_ZONE_20ms_Group13_Reserve3 "ICBAD_ZONE_20ms_Group13_Reserved4";
BA_ "SystemSignalLongSymbol" SG_ 81 IICBAD_ZONE_20ms_Group13_Reserve3 "IICBAD_ZONE_20ms_Group13_Reserved4";
BA_ "CompuMethodName" SG_ 81 ITJAICASysSts "TJAICASysSts";
BA_ "ISignalName" SG_ 81 ITJAICASysSts "ITJAICASysSts";
BA_ "LongName" SG_ 81 ITJAICASysSts "Traffic Jam Assist Integrated Cruise Assist System Status";
BA_ "SysSignalName" SG_ 81 ITJAICASysSts "TJAICASysSts";
BA_ "CompuMethodName" SG_ 81 ILKASysSts "LKASysSts";
BA_ "ISignalName" SG_ 81 ILKASysSts "ILKASysSts";
BA_ "LongName" SG_ 81 ILKASysSts "Lane Keeping Assist System Status";
BA_ "SysSignalName" SG_ 81 ILKASysSts "LKASysSts";
BA_ "CompuMethodName" SG_ 81 IICBAD_ZONE_20ms_Group13_Reserve4 "ICBAD_ZONE_20ms_Group13_Reserved5";
BA_ "GenSigStartValue" SG_ 81 IICBAD_ZONE_20ms_Group13_Reserve4 255;
BA_ "ISignalName" SG_ 81 IICBAD_ZONE_20ms_Group13_Reserve4 "IICBAD_ZONE_20ms_Group13_Reserved5";
BA_ "SysSignalName" SG_ 81 IICBAD_ZONE_20ms_Group13_Reserve4 "ICBAD_ZONE_20ms_Group13_Reserved5";
BA_ "SystemSignalLongSymbol" SG_ 81 IICBAD_ZONE_20ms_Group13_Reserve4 "IICBAD_ZONE_20ms_Group13_Reserved5";
BA_ "CompuMethodName" SG_ 81 IICBAD_ZONE_20ms_Group13_Reserve5 "ICBAD_ZONE_20ms_Group13_Reserved6";
BA_ "GenSigStartValue" SG_ 81 IICBAD_ZONE_20ms_Group13_Reserve5 255;
BA_ "ISignalName" SG_ 81 IICBAD_ZONE_20ms_Group13_Reserve5 "IICBAD_ZONE_20ms_Group13_Reserved6";
BA_ "SysSignalName" SG_ 81 IICBAD_ZONE_20ms_Group13_Reserve5 "ICBAD_ZONE_20ms_Group13_Reserved6";
BA_ "SystemSignalLongSymbol" SG_ 81 IICBAD_ZONE_20ms_Group13_Reserve5 "IICBAD_ZONE_20ms_Group13_Reserved6";
BA_ "CompuMethodName" SG_ 81 IICBAD_ZONE_20ms_Group13_Reserve6 "ICBAD_ZONE_20ms_Group13_Reserved7";
BA_ "GenSigStartValue" SG_ 81 IICBAD_ZONE_20ms_Group13_Reserve6 255;
BA_ "ISignalName" SG_ 81 IICBAD_ZONE_20ms_Group13_Reserve6 "IICBAD_ZONE_20ms_Group13_Reserved7";
BA_ "SysSignalName" SG_ 81 IICBAD_ZONE_20ms_Group13_Reserve6 "ICBAD_ZONE_20ms_Group13_Reserved7";
BA_ "SystemSignalLongSymbol" SG_ 81 IICBAD_ZONE_20ms_Group13_Reserve6 "IICBAD_ZONE_20ms_Group13_Reserved7";
BA_ "CompuMethodName" SG_ 81 IICBAD_ZONE_20ms_Group13_Reserve7 "ICBAD_ZONE_20ms_Group13_Reserved8";
BA_ "GenSigStartValue" SG_ 81 IICBAD_ZONE_20ms_Group13_Reserve7 255;
BA_ "ISignalName" SG_ 81 IICBAD_ZONE_20ms_Group13_Reserve7 "IICBAD_ZONE_20ms_Group13_Reserved8";
BA_ "SysSignalName" SG_ 81 IICBAD_ZONE_20ms_Group13_Reserve7 "ICBAD_ZONE_20ms_Group13_Reserved8";
BA_ "SystemSignalLongSymbol" SG_ 81 IICBAD_ZONE_20ms_Group13_Reserve7 "IICBAD_ZONE_20ms_Group13_Reserved8";
BA_ "CompuMethodName" SG_ 1282 ISpdLmtPathRngNav "SpdLmtPathRngNav";
BA_ "GenSigStartValue" SG_ 1282 ISpdLmtPathRngNav 2047;
BA_ "ISignalName" SG_ 1282 ISpdLmtPathRngNav "ISpdLmtPathRngNav";
BA_ "LongName" SG_ 1282 ISpdLmtPathRngNav "Speed_Limit_Path_Range_Navigation";
BA_ "SysSignalName" SG_ 1282 ISpdLmtPathRngNav "SpdLmtPathRngNav";
BA_ "CompuMethodName" SG_ 1282 IMnvrngPntDistNav "MnvrngPntDistNav";
BA_ "GenSigStartValue" SG_ 1282 IMnvrngPntDistNav 1023;
BA_ "ISignalName" SG_ 1282 IMnvrngPntDistNav "IMnvrngPntDistNav";
BA_ "LongName" SG_ 1282 IMnvrngPntDistNav "Maneuvering_Point_Distance_Navigation";
BA_ "SysSignalName" SG_ 1282 IMnvrngPntDistNav "MnvrngPntDistNav";
BA_ "CompuMethodName" SG_ 1282 IDistToTrfcJamNav "DistToTrfcJamNav";
BA_ "GenSigStartValue" SG_ 1282 IDistToTrfcJamNav 255;
BA_ "ISignalName" SG_ 1282 IDistToTrfcJamNav "IDistToTrfcJamNav";
BA_ "LongName" SG_ 1282 IDistToTrfcJamNav "Distance_To_Traffic_Jam_Navigation";
BA_ "SysSignalName" SG_ 1282 IDistToTrfcJamNav "DistToTrfcJamNav";
BA_ "CompuMethodName" SG_ 1282 IMnvrngPntTypNav "MnvrngPntTypNav";
BA_ "ISignalName" SG_ 1282 IMnvrngPntTypNav "IMnvrngPntTypNav";
BA_ "LongName" SG_ 1282 IMnvrngPntTypNav "Maneuvering_Point_Type_Navigation";
BA_ "SysSignalName" SG_ 1282 IMnvrngPntTypNav "MnvrngPntTypNav";
BA_ "CompuMethodName" SG_ 1282 ITrfcJamRngNav "TrfcJamRngNav";
BA_ "GenSigStartValue" SG_ 1282 ITrfcJamRngNav 255;
BA_ "ISignalName" SG_ 1282 ITrfcJamRngNav "ITrfcJamRngNav";
BA_ "LongName" SG_ 1282 ITrfcJamRngNav "Traffic_Jam_Range_Navigation";
BA_ "SysSignalName" SG_ 1282 ITrfcJamRngNav "TrfcJamRngNav";
BA_ "CompuMethodName" SG_ 1282 INavSts "NavSts";
BA_ "ISignalName" SG_ 1282 INavSts "INavSts";
BA_ "LongName" SG_ 1282 INavSts "Navigation_Status";
BA_ "SysSignalName" SG_ 1282 INavSts "NavSts";
BA_ "CompuMethodName" SG_ 1282 ISpdLmtNav "SpdLmtNav";
BA_ "GenSigStartValue" SG_ 1282 ISpdLmtNav 31;
BA_ "ISignalName" SG_ 1282 ISpdLmtNav "ISpdLmtNav";
BA_ "LongName" SG_ 1282 ISpdLmtNav "Speed_Limit_Navigation";
BA_ "SysSignalName" SG_ 1282 ISpdLmtNav "SpdLmtNav";
BA_ "CompuMethodName" SG_ 821 IDiffDataLinkBrokensecinfo "DiffDataLinkBrokensecinfo";
BA_ "ISignalName" SG_ 821 IDiffDataLinkBrokensecinfo "IDiffDataLinkBrokensecinfo";
BA_ "LongName" SG_ 821 IDiffDataLinkBrokensecinfo "Diff_Data_Link_Merged_Broken";
BA_ "SysSignalName" SG_ 821 IDiffDataLinkBrokensecinfo "DiffDataLinkBrokensecinfo";
BA_ "CompuMethodName" SG_ 821 IGNSSAntenasBrokensecinfo "GNSSAntenasBrokensecinfo";
BA_ "ISignalName" SG_ 821 IGNSSAntenasBrokensecinfo "IGNSSAntenasBrokensecinfo";
BA_ "LongName" SG_ 821 IGNSSAntenasBrokensecinfo "Gnss_Antenas_Broken";
BA_ "SysSignalName" SG_ 821 IGNSSAntenasBrokensecinfo "GNSSAntenasBrokensecinfo";
BA_ "CompuMethodName" SG_ 821 IGPSMsgErrInIMUsecinfo "GPSMsgErrInIMUsecinfo";
BA_ "ISignalName" SG_ 821 IGPSMsgErrInIMUsecinfo "IGPSMsgErrInIMUsecinfo";
BA_ "LongName" SG_ 821 IGPSMsgErrInIMUsecinfo "Gps_Msg_Errin_Imu";
BA_ "SysSignalName" SG_ 821 IGPSMsgErrInIMUsecinfo "GPSMsgErrInIMUsecinfo";
BA_ "CompuMethodName" SG_ 821 IIECUMsgErrInIMUsecinfo "IECUMsgErrInIMUsecinfo";
BA_ "ISignalName" SG_ 821 IIECUMsgErrInIMUsecinfo "IIECUMsgErrInIMUsecinfo";
BA_ "LongName" SG_ 821 IIECUMsgErrInIMUsecinfo "Iecu_Msg_Errin_Imu";
BA_ "SysSignalName" SG_ 821 IIECUMsgErrInIMUsecinfo "IECUMsgErrInIMUsecinfo";
BA_ "CompuMethodName" SG_ 66 IDspMeasmtSys "DspMeasmtSys";
BA_ "ISignalName" SG_ 66 IDspMeasmtSys "IDspMeasmtSys";
BA_ "LongName" SG_ 66 IDspMeasmtSys "Display Measurement System";
BA_ "SysSignalName" SG_ 66 IDspMeasmtSys "DspMeasmtSys";
BA_ "CompuMethodName" SG_ 66 IUsgMdExtrCtrlAvlbl "UsgMdExtrCtrlAvlbl";
BA_ "ISignalName" SG_ 66 IUsgMdExtrCtrlAvlbl "IUsgMdExtrCtrlAvlbl";
BA_ "LongName" SG_ 66 IUsgMdExtrCtrlAvlbl "Usage Mode Exterior Control Available";
BA_ "SysSignalName" SG_ 66 IUsgMdExtrCtrlAvlbl "UsgMdExtrCtrlAvlbl";
BA_ "CompuMethodName" SG_ 66 IUsgMdCtrlSts "UsgMdCtrlSts";
BA_ "ISignalName" SG_ 66 IUsgMdCtrlSts "IUsgMdCtrlSts";
BA_ "LongName" SG_ 66 IUsgMdCtrlSts "Usage Mode Control Status";
BA_ "SysSignalName" SG_ 66 IUsgMdCtrlSts "UsgMdCtrlSts";
BA_ "CompuMethodName" SG_ 66 IRWSDrvMdReqV "RWSDrvMdReqV";
BA_ "GenSigStartValue" SG_ 66 IRWSDrvMdReqV 1;
BA_ "ISignalName" SG_ 66 IRWSDrvMdReqV "IRWSDrvMdReqV";
BA_ "LongName" SG_ 66 IRWSDrvMdReqV "Rear_Wheel_Steering_Dive_Mode_Request_Valid";
BA_ "SysSignalName" SG_ 66 IRWSDrvMdReqV "RWSDrvMdReqV";
BA_ "CompuMethodName" SG_ 66 IRWSDrvMdReq "RWSDrvMdReq";
BA_ "ISignalName" SG_ 66 IRWSDrvMdReq "IRWSDrvMdReq";
BA_ "LongName" SG_ 66 IRWSDrvMdReq "Rear_Wheel_Steering_Dive_Mode_Request";
BA_ "SysSignalName" SG_ 66 IRWSDrvMdReq "RWSDrvMdReq";
BA_ "CompuMethodName" SG_ 66 IPDCSwReq "PDCSwReq";
BA_ "ISignalName" SG_ 66 IPDCSwReq "IPDCSwReq";
BA_ "LongName" SG_ 66 IPDCSwReq "Park Distance Control Switch Request";
BA_ "SysSignalName" SG_ 66 IPDCSwReq "PDCSwReq";
BA_ "CompuMethodName" SG_ 66 IPwrMdExtrCtrlAvlbl "PwrMdExtrCtrlAvlbl";
BA_ "ISignalName" SG_ 66 IPwrMdExtrCtrlAvlbl "IPwrMdExtrCtrlAvlbl";
BA_ "LongName" SG_ 66 IPwrMdExtrCtrlAvlbl "Power_Mode_Exterior_Control_Available";
BA_ "SysSignalName" SG_ 66 IPwrMdExtrCtrlAvlbl "PwrMdExtrCtrlAvlbl";
BA_ "CompuMethodName" SG_ 66 IMdOfPwrMd "MdOfPwrMd";
BA_ "ISignalName" SG_ 66 IMdOfPwrMd "IMdOfPwrMd";
BA_ "LongName" SG_ 66 IMdOfPwrMd "Mode_Of_Power_Mode";
BA_ "SysSignalName" SG_ 66 IMdOfPwrMd "MdOfPwrMd";
BA_ "CompuMethodName" SG_ 66 IClstrDspdVehSpd "ClstrDspdVehSpd";
BA_ "ISignalName" SG_ 66 IClstrDspdVehSpd "IClstrDspdVehSpd";
BA_ "LongName" SG_ 66 IClstrDspdVehSpd "Cluster Displayed Vehicle Speed";
BA_ "SysSignalName" SG_ 66 IClstrDspdVehSpd "ClstrDspdVehSpd";
BA_ "CompuMethodName" SG_ 66 IFRSeatVentCtrlSts "FRSeatVentCtrlSts";
BA_ "ISignalName" SG_ 66 IFRSeatVentCtrlSts "IFRSeatVentCtrlSts";
BA_ "SysSignalName" SG_ 66 IFRSeatVentCtrlSts "FRSeatVentCtrlSts";
BA_ "CompuMethodName" SG_ 66 IFLSeatVentCtrlSts "FLSeatVentCtrlSts";
BA_ "ISignalName" SG_ 66 IFLSeatVentCtrlSts "IFLSeatVentCtrlSts";
BA_ "SysSignalName" SG_ 66 IFLSeatVentCtrlSts "FLSeatVentCtrlSts";
BA_ "CompuMethodName" SG_ 66 IFRSeatHeatCtrlSts "FRSeatHeatCtrlSts";
BA_ "ISignalName" SG_ 66 IFRSeatHeatCtrlSts "IFRSeatHeatCtrlSts";
BA_ "SysSignalName" SG_ 66 IFRSeatHeatCtrlSts "FRSeatHeatCtrlSts";
BA_ "CompuMethodName" SG_ 66 IFLSeatHeatCtrlSts "FLSeatHeatCtrlSts";
BA_ "ISignalName" SG_ 66 IFLSeatHeatCtrlSts "IFLSeatHeatCtrlSts";
BA_ "SysSignalName" SG_ 66 IFLSeatHeatCtrlSts "FLSeatHeatCtrlSts";
BA_ "CompuMethodName" SG_ 871 IRembMapBldngResp "RembMapBldngResp";
BA_ "ISignalName" SG_ 871 IRembMapBldngResp "IRembMapBldngResp";
BA_ "LongName" SG_ 871 IRembMapBldngResp "Remember Map Building Response";
BA_ "SysSignalName" SG_ 871 IRembMapBldngResp "RembMapBldngResp";
BA_ "CompuMethodName" SG_ 871 IRembBldMapResp "RembBldMapResp";
BA_ "ISignalName" SG_ 871 IRembBldMapResp "IRembBldMapResp";
BA_ "LongName" SG_ 871 IRembBldMapResp "Remember_Build_Map_Response";
BA_ "SysSignalName" SG_ 871 IRembBldMapResp "RembBldMapResp";
BA_ "CompuMethodName" SG_ 871 IAVMSt "AVMSt";
BA_ "ISignalName" SG_ 871 IAVMSt "IAVMSt";
BA_ "LongName" SG_ 871 IAVMSt "AVM_Display_Stats";
BA_ "SysSignalName" SG_ 871 IAVMSt "AVMSt";
BA_ "CompuMethodName" SG_ 871 IRstrFctryDeftsReq "RstrFctryDeftsReq";
BA_ "ISignalName" SG_ 871 IRstrFctryDeftsReq "IRstrFctryDeftsReq";
BA_ "LongName" SG_ 871 IRstrFctryDeftsReq "Restore_Factory_Defaults_Request";
BA_ "SysSignalName" SG_ 871 IRstrFctryDeftsReq "RstrFctryDeftsReq";
BA_ "CompuMethodName" SG_ 871 ISelfLrnResultReq "SelfLrnResultReq";
BA_ "ISignalName" SG_ 871 ISelfLrnResultReq "ISelfLrnResultReq";
BA_ "LongName" SG_ 871 ISelfLrnResultReq "Self Learning Result Request";
BA_ "SysSignalName" SG_ 871 ISelfLrnResultReq "SelfLrnResultReq";
BA_ "CompuMethodName" SG_ 871 IMapDataReq "MapDataReq";
BA_ "ISignalName" SG_ 871 IMapDataReq "IMapDataReq";
BA_ "LongName" SG_ 871 IMapDataReq "Map Data Request";
BA_ "SysSignalName" SG_ 871 IMapDataReq "MapDataReq";
BA_ "CompuMethodName" SG_ 871 IMapListReq "MapListReq";
BA_ "ISignalName" SG_ 871 IMapListReq "IMapListReq";
BA_ "LongName" SG_ 871 IMapListReq "Map List Request";
BA_ "SysSignalName" SG_ 871 IMapListReq "MapListReq";
BA_ "CompuMethodName" SG_ 871 IRembParkngInMapRutResp "RembParkngInMapRutResp";
BA_ "ISignalName" SG_ 871 IRembParkngInMapRutResp "IRembParkngInMapRutResp";
BA_ "LongName" SG_ 871 IRembParkngInMapRutResp "Remember Parking In Map Route Response";
BA_ "SysSignalName" SG_ 871 IRembParkngInMapRutResp "RembParkngInMapRutResp";
BA_ "CompuMethodName" SG_ 871 IOtrIntlgntMdTrigHvacReq "OtrIntlgntMdTrigHvacReq";
BA_ "ISignalName" SG_ 871 IOtrIntlgntMdTrigHvacReq "IOtrIntlgntMdTrigHvacReq";
BA_ "LongName" SG_ 871 IOtrIntlgntMdTrigHvacReq "Other Intelligent Mode Trigger Hvac Request";
BA_ "SysSignalName" SG_ 871 IOtrIntlgntMdTrigHvacReq "OtrIntlgntMdTrigHvacReq";
BA_ "CompuMethodName" SG_ 871 IIPDCoDrivingPlusFunReq "IPDCoDrivingPlusFunReq";
BA_ "ISignalName" SG_ 871 IIPDCoDrivingPlusFunReq "IIPDCoDrivingPlusFunReq";
BA_ "LongName" SG_ 871 IIPDCoDrivingPlusFunReq "IPD Cooperation Driving Plus Function Request";
BA_ "SysSignalName" SG_ 871 IIPDCoDrivingPlusFunReq "IPDCoDrivingPlusFunReq";
BA_ "CompuMethodName" SG_ 871 IICBE2EFunSwReq "ICBE2EFunSwReq";
BA_ "ISignalName" SG_ 871 IICBE2EFunSwReq "IICBE2EFunSwReq";
BA_ "LongName" SG_ 871 IICBE2EFunSwReq "ICB End to End Function Switch Request";
BA_ "SysSignalName" SG_ 871 IICBE2EFunSwReq "ICBE2EFunSwReq";
BA_ "CompuMethodName" SG_ 871 IDCDCVolStptBkup "DCDCVolStptBkup";
BA_ "GenSigStartValue" SG_ 871 IDCDCVolStptBkup 254;
BA_ "ISignalName" SG_ 871 IDCDCVolStptBkup "IDCDCVolStptBkup";
BA_ "LongName" SG_ 871 IDCDCVolStptBkup "Direct_Current_Direct_Current_Voltage_Setpoint_Backup";
BA_ "SysSignalName" SG_ 871 IDCDCVolStptBkup "DCDCVolStptBkup";
BA_ "CompuMethodName" SG_ 863 IFICMPosngSysLatd "FICMPosngSysLatd";
BA_ "ISignalName" SG_ 863 IFICMPosngSysLatd "IFICMPosngSysLatd";
BA_ "LongName" SG_ 863 IFICMPosngSysLatd "Front_Infotainment_Control_Module_Positioning_System_Latitude";
BA_ "SysSignalName" SG_ 863 IFICMPosngSysLatd "FICMPosngSysLatd";
BA_ "CompuMethodName" SG_ 863 IDstrctnDetnSts "DstrctnDetnSts";
BA_ "ISignalName" SG_ 863 IDstrctnDetnSts "IDstrctnDetnSts";
BA_ "LongName" SG_ 863 IDstrctnDetnSts "Distraction Detection Status";
BA_ "SysSignalName" SG_ 863 IDstrctnDetnSts "DstrctnDetnSts";
BA_ "CompuMethodName" SG_ 863 IFICMPosngSysLongd "FICMPosngSysLongd";
BA_ "ISignalName" SG_ 863 IFICMPosngSysLongd "IFICMPosngSysLongd";
BA_ "LongName" SG_ 863 IFICMPosngSysLongd "Front_Infotainment_Control_Module_Positioning_System_Longitude";
BA_ "SysSignalName" SG_ 863 IFICMPosngSysLongd "FICMPosngSysLongd";
BA_ "CompuMethodName" SG_ 863 IFtgDetnSts "FtgDetnSts";
BA_ "ISignalName" SG_ 863 IFtgDetnSts "IFtgDetnSts";
BA_ "LongName" SG_ 863 IFtgDetnSts "Fatigue Detection Status";
BA_ "SysSignalName" SG_ 863 IFtgDetnSts "FtgDetnSts";
BA_ "CompuMethodName" SG_ 906 INavCrntRoadTyp "NavCrntRoadTyp";
BA_ "ISignalName" SG_ 906 INavCrntRoadTyp "INavCrntRoadTyp";
BA_ "LongName" SG_ 906 INavCrntRoadTyp "Navigation_Current_Road_Type";
BA_ "SysSignalName" SG_ 906 INavCrntRoadTyp "NavCrntRoadTyp";
BA_ "CompuMethodName" SG_ 906 INavNewIcon "NavNewIcon";
BA_ "ISignalName" SG_ 906 INavNewIcon "INavNewIcon";
BA_ "LongName" SG_ 906 INavNewIcon "Navigation_New_Icon";
BA_ "SysSignalName" SG_ 906 INavNewIcon "NavNewIcon";
BA_ "CompuMethodName" SG_ 906 IVceCntrl_CriSpdDecreValu "VceCntrl_CriSpdDecreValu";
BA_ "ISignalName" SG_ 906 IVceCntrl_CriSpdDecreValu "IVceCntrl_CriSpdDecreValu";
BA_ "LongName" SG_ 906 IVceCntrl_CriSpdDecreValu "Voice_Control_Cruise_Speed_Decrease_Value";
BA_ "SysSignalName" SG_ 906 IVceCntrl_CriSpdDecreValu "VceCntrl_CriSpdDecreValu";
BA_ "CompuMethodName" SG_ 906 IVceCntrl_CriSpdIncreValu "VceCntrl_CriSpdIncreValu";
BA_ "ISignalName" SG_ 906 IVceCntrl_CriSpdIncreValu "IVceCntrl_CriSpdIncreValu";
BA_ "LongName" SG_ 906 IVceCntrl_CriSpdIncreValu "Voice_Control_Cruise_Speed_Increase_Value";
BA_ "SysSignalName" SG_ 906 IVceCntrl_CriSpdIncreValu "VceCntrl_CriSpdIncreValu";
BA_ "CompuMethodName" SG_ 906 IVceCntrl_CriSpdValu "VceCntrl_CriSpdValu";
BA_ "ISignalName" SG_ 906 IVceCntrl_CriSpdValu "IVceCntrl_CriSpdValu";
BA_ "LongName" SG_ 906 IVceCntrl_CriSpdValu "Voice_Control_Cruise_Speed_Value";
BA_ "SysSignalName" SG_ 906 IVceCntrl_CriSpdValu "VceCntrl_CriSpdValu";
BA_ "CompuMethodName" SG_ 906 IMinorAdjSetReq "MinorAdjSetReq";
BA_ "ISignalName" SG_ 906 IMinorAdjSetReq "IMinorAdjSetReq";
BA_ "LongName" SG_ 906 IMinorAdjSetReq "Parking minor adjust setting request";
BA_ "SysSignalName" SG_ 906 IMinorAdjSetReq "MinorAdjSetReq";
BA_ "CompuMethodName" SG_ 906 IVceCntrl_DistanLevl "VceCntrl_DistanLevl";
BA_ "ISignalName" SG_ 906 IVceCntrl_DistanLevl "IVceCntrl_DistanLevl";
BA_ "LongName" SG_ 906 IVceCntrl_DistanLevl "Voice_Control_Distance_Level";
BA_ "SysSignalName" SG_ 906 IVceCntrl_DistanLevl "VceCntrl_DistanLevl";
BA_ "CompuMethodName" SG_ 906 IVceCntrl_DecreCriSpd "VceCntrl_DecreCriSpd";
BA_ "ISignalName" SG_ 906 IVceCntrl_DecreCriSpd "IVceCntrl_DecreCriSpd";
BA_ "LongName" SG_ 906 IVceCntrl_DecreCriSpd "Voice_Control_Decrease_Cruise_Speed";
BA_ "SysSignalName" SG_ 906 IVceCntrl_DecreCriSpd "VceCntrl_DecreCriSpd";
BA_ "CompuMethodName" SG_ 906 IParkOutEntrySetReq "ParkOutEntrySetReq";
BA_ "ISignalName" SG_ 906 IParkOutEntrySetReq "IParkOutEntrySetReq";
BA_ "LongName" SG_ 906 IParkOutEntrySetReq "parking out entry type set request";
BA_ "SysSignalName" SG_ 906 IParkOutEntrySetReq "ParkOutEntrySetReq";
BA_ "CompuMethodName" SG_ 906 IVceCntrl_AIPilot "VceCntrl_AIPilot";
BA_ "ISignalName" SG_ 906 IVceCntrl_AIPilot "IVceCntrl_AIPilot";
BA_ "LongName" SG_ 906 IVceCntrl_AIPilot "Voice_Control_Aipilot";
BA_ "SysSignalName" SG_ 906 IVceCntrl_AIPilot "VceCntrl_AIPilot";
BA_ "CompuMethodName" SG_ 906 INavTrfcLghtInfo "NavTrfcLghtInfo";
BA_ "ISignalName" SG_ 906 INavTrfcLghtInfo "INavTrfcLghtInfo";
BA_ "LongName" SG_ 906 INavTrfcLghtInfo "Navigation_Traffic_Light_Command";
BA_ "SysSignalName" SG_ 906 INavTrfcLghtInfo "NavTrfcLghtInfo";
BA_ "CompuMethodName" SG_ 906 INavCountryCode "NavCountryCode";
BA_ "ISignalName" SG_ 906 INavCountryCode "INavCountryCode";
BA_ "LongName" SG_ 906 INavCountryCode "Navigation_Country_Code";
BA_ "SysSignalName" SG_ 906 INavCountryCode "NavCountryCode";
BA_ "CompuMethodName" SG_ 906 IVceCntrl_DistanLevlIncre "VceCntrl_DistanLevlIncre";
BA_ "ISignalName" SG_ 906 IVceCntrl_DistanLevlIncre "IVceCntrl_DistanLevlIncre";
BA_ "LongName" SG_ 906 IVceCntrl_DistanLevlIncre "Voice_Control_Distance_Level_Increase";
BA_ "SysSignalName" SG_ 906 IVceCntrl_DistanLevlIncre "VceCntrl_DistanLevlIncre";
BA_ "CompuMethodName" SG_ 906 IVceCntrl_DistanLevlDecre "VceCntrl_DistanLevlDecre";
BA_ "ISignalName" SG_ 906 IVceCntrl_DistanLevlDecre "IVceCntrl_DistanLevlDecre";
BA_ "LongName" SG_ 906 IVceCntrl_DistanLevlDecre "Voice_Control_Distance_Level_Decrease";
BA_ "SysSignalName" SG_ 906 IVceCntrl_DistanLevlDecre "VceCntrl_DistanLevlDecre";
BA_ "CompuMethodName" SG_ 906 INavSpdLmtValUnit "NavSpdLmtValUnit";
BA_ "GenSigStartValue" SG_ 906 INavSpdLmtValUnit 2;
BA_ "ISignalName" SG_ 906 INavSpdLmtValUnit "INavSpdLmtValUnit";
BA_ "LongName" SG_ 906 INavSpdLmtValUnit "Navigation_Speed_Limit_Value_Units";
BA_ "SysSignalName" SG_ 906 INavSpdLmtValUnit "NavSpdLmtValUnit";
BA_ "CompuMethodName" SG_ 906 INavNewIconDist "NavNewIconDist";
BA_ "ISignalName" SG_ 906 INavNewIconDist "INavNewIconDist";
BA_ "LongName" SG_ 906 INavNewIconDist "Navigation_New_Icon_Distance";
BA_ "SysSignalName" SG_ 906 INavNewIconDist "NavNewIconDist";
BA_ "CompuMethodName" SG_ 906 INavSpdLmtValSts "NavSpdLmtValSts";
BA_ "GenSigStartValue" SG_ 906 INavSpdLmtValSts 2;
BA_ "ISignalName" SG_ 906 INavSpdLmtValSts "INavSpdLmtValSts";
BA_ "LongName" SG_ 906 INavSpdLmtValSts "Navigation_Speed_Limit_Status";
BA_ "SysSignalName" SG_ 906 INavSpdLmtValSts "NavSpdLmtValSts";
BA_ "CompuMethodName" SG_ 906 INavDistFromFrtEleccEye "NavDistFromFrtEleccEye";
BA_ "ISignalName" SG_ 906 INavDistFromFrtEleccEye "INavDistFromFrtEleccEye";
BA_ "LongName" SG_ 906 INavDistFromFrtEleccEye "Navigation_Distance_From_Front_Electronic_Eye";
BA_ "SysSignalName" SG_ 906 INavDistFromFrtEleccEye "NavDistFromFrtEleccEye";
BA_ "CompuMethodName" SG_ 906 INavItvalSpdDetnDistRetDist "NavItvalSpdDetnDistRetDist";
BA_ "ISignalName" SG_ 906 INavItvalSpdDetnDistRetDist "INavItvalSpdDetnDistRetDist";
BA_ "LongName" SG_ 906 INavItvalSpdDetnDistRetDist "Navigation_Interval_Speed_Detection_Rest_Distance";
BA_ "SysSignalName" SG_ 906 INavItvalSpdDetnDistRetDist "NavItvalSpdDetnDistRetDist";
BA_ "CompuMethodName" SG_ 906 INavSpdLmtVal "NavSpdLmtVal";
BA_ "ISignalName" SG_ 906 INavSpdLmtVal "INavSpdLmtVal";
BA_ "LongName" SG_ 906 INavSpdLmtVal "Navigation_Speed_Limit_Value";
BA_ "SysSignalName" SG_ 906 INavSpdLmtVal "NavSpdLmtVal";
BA_ "CompuMethodName" SG_ 906 IVceCntrl_IncreCriSpd "VceCntrl_IncreCriSpd";
BA_ "ISignalName" SG_ 906 IVceCntrl_IncreCriSpd "IVceCntrl_IncreCriSpd";
BA_ "LongName" SG_ 906 IVceCntrl_IncreCriSpd "Voice_Control_Increase_Cruise_Speed";
BA_ "SysSignalName" SG_ 906 IVceCntrl_IncreCriSpd "VceCntrl_IncreCriSpd";
BA_ "CompuMethodName" SG_ 906 INavSpdLmtTyp "NavSpdLmtTyp";
BA_ "ISignalName" SG_ 906 INavSpdLmtTyp "INavSpdLmtTyp";
BA_ "LongName" SG_ 906 INavSpdLmtTyp "Navigation_Speed_Limit_Type";
BA_ "SysSignalName" SG_ 906 INavSpdLmtTyp "NavSpdLmtTyp";
BA_ "CompuMethodName" SG_ 932 ITrnptVehBodyDspReq "TrnptVehBodyDspReq";
BA_ "ISignalName" SG_ 932 ITrnptVehBodyDspReq "ITrnptVehBodyDspReq";
BA_ "LongName" SG_ 932 ITrnptVehBodyDspReq "Transparent_Vehicle_Body_Display_Request";
BA_ "SysSignalName" SG_ 932 ITrnptVehBodyDspReq "TrnptVehBodyDspReq";
BA_ "CompuMethodName" SG_ 932 INextPicture "NextPicture";
BA_ "ISignalName" SG_ 932 INextPicture "INextPicture";
BA_ "LongName" SG_ 932 INextPicture "NextPicture";
BA_ "SysSignalName" SG_ 932 INextPicture "NextPicture";
BA_ "CompuMethodName" SG_ 932 IUnSelePoint "UnSelePoint";
BA_ "ISignalName" SG_ 932 IUnSelePoint "IUnSelePoint";
BA_ "LongName" SG_ 932 IUnSelePoint "PointSelectUndo";
BA_ "SysSignalName" SG_ 932 IUnSelePoint "UnSelePoint";
BA_ "CompuMethodName" SG_ 932 IStartCalib "StartCalib";
BA_ "ISignalName" SG_ 932 IStartCalib "IStartCalib";
BA_ "LongName" SG_ 932 IStartCalib "StartCalibration";
BA_ "SysSignalName" SG_ 932 IStartCalib "StartCalib";
BA_ "CompuMethodName" SG_ 932 IVehDragMdSts "VehDragMdSts";
BA_ "ISignalName" SG_ 932 IVehDragMdSts "IVehDragMdSts";
BA_ "LongName" SG_ 932 IVehDragMdSts "Vehicle_Dragging_Mode_Status";
BA_ "SysSignalName" SG_ 932 IVehDragMdSts "VehDragMdSts";
BA_ "CompuMethodName" SG_ 830 IATGpitchsecinfo "ATGpitchsecinfo";
BA_ "ISignalName" SG_ 830 IATGpitchsecinfo "IATGpitchsecinfo";
BA_ "LongName" SG_ 830 IATGpitchsecinfo "Atg_Pitch";
BA_ "SysSignalName" SG_ 830 IATGpitchsecinfo "ATGpitchsecinfo";
BA_ "CompuMethodName" SG_ 830 IATGrollsecinfo "ATGrollsecinfo";
BA_ "ISignalName" SG_ 830 IATGrollsecinfo "IATGrollsecinfo";
BA_ "LongName" SG_ 830 IATGrollsecinfo "Atg_Roll";
BA_ "SysSignalName" SG_ 830 IATGrollsecinfo "ATGrollsecinfo";
BA_ "CompuMethodName" SG_ 830 IGNSSVelEastsecinfo "GNSSVelEastsecinfo";
BA_ "ISignalName" SG_ 830 IGNSSVelEastsecinfo "IGNSSVelEastsecinfo";
BA_ "LongName" SG_ 830 IGNSSVelEastsecinfo "Gnss_Veleast";
BA_ "SysSignalName" SG_ 830 IGNSSVelEastsecinfo "GNSSVelEastsecinfo";
BA_ "CompuMethodName" SG_ 1104 IParkngFuncICMRsrv01 "ParkngFuncICMRsrv01";
BA_ "ISignalName" SG_ 1104 IParkngFuncICMRsrv01 "IParkngFuncICMRsrv01";
BA_ "LongName" SG_ 1104 IParkngFuncICMRsrv01 "parking function ICM send reserved01";
BA_ "SysSignalName" SG_ 1104 IParkngFuncICMRsrv01 "ParkngFuncICMRsrv01";
BA_ "CompuMethodName" SG_ 1104 IMapDelete "MapDelete";
BA_ "ISignalName" SG_ 1104 IMapDelete "IMapDelete";
BA_ "LongName" SG_ 1104 IMapDelete "Memory Map delete";
BA_ "SysSignalName" SG_ 1104 IMapDelete "MapDelete";
BA_ "CompuMethodName" SG_ 1104 IParkngFuncICMRsrv03 "ParkngFuncICMRsrv03";
BA_ "ISignalName" SG_ 1104 IParkngFuncICMRsrv03 "IParkngFuncICMRsrv03";
BA_ "LongName" SG_ 1104 IParkngFuncICMRsrv03 "parking function ICM send reserved03";
BA_ "SysSignalName" SG_ 1104 IParkngFuncICMRsrv03 "ParkngFuncICMRsrv03";
BA_ "CompuMethodName" SG_ 1104 IParkngFuncICMRsrv02 "ParkngFuncICMRsrv02";
BA_ "ISignalName" SG_ 1104 IParkngFuncICMRsrv02 "IParkngFuncICMRsrv02";
BA_ "LongName" SG_ 1104 IParkngFuncICMRsrv02 "parking function ICM send reserved02";
BA_ "SysSignalName" SG_ 1104 IParkngFuncICMRsrv02 "ParkngFuncICMRsrv02";
BA_ "CompuMethodName" SG_ 1104 IFrntWhlMinorAdjLeft "FrntWhlMinorAdjLeft";
BA_ "ISignalName" SG_ 1104 IFrntWhlMinorAdjLeft "IFrntWhlMinorAdjLeft";
BA_ "LongName" SG_ 1104 IFrntWhlMinorAdjLeft "Front Wheel Parking Minor Adjust Left";
BA_ "SysSignalName" SG_ 1104 IFrntWhlMinorAdjLeft "FrntWhlMinorAdjLeft";
BA_ "CompuMethodName" SG_ 1104 INrwroadFwdCtlReq "NrwroadFwdCtlReq";
BA_ "ISignalName" SG_ 1104 INrwroadFwdCtlReq "INrwroadFwdCtlReq";
BA_ "LongName" SG_ 1104 INrwroadFwdCtlReq "Narrow road forward control requst";
BA_ "SysSignalName" SG_ 1104 INrwroadFwdCtlReq "NrwroadFwdCtlReq";
BA_ "CompuMethodName" SG_ 1104 IRearWhlMinorAdjLeft "RearWhlMinorAdjLeft";
BA_ "ISignalName" SG_ 1104 IRearWhlMinorAdjLeft "IRearWhlMinorAdjLeft";
BA_ "LongName" SG_ 1104 IRearWhlMinorAdjLeft "Rear Wheel Parking Minor Adjust Left";
BA_ "SysSignalName" SG_ 1104 IRearWhlMinorAdjLeft "RearWhlMinorAdjLeft";
BA_ "CompuMethodName" SG_ 1104 IFrntWhlMinorAdjRight "FrntWhlMinorAdjRight";
BA_ "ISignalName" SG_ 1104 IFrntWhlMinorAdjRight "IFrntWhlMinorAdjRight";
BA_ "LongName" SG_ 1104 IFrntWhlMinorAdjRight "Front Wheel Parking Minor Adjust Right";
BA_ "SysSignalName" SG_ 1104 IFrntWhlMinorAdjRight "FrntWhlMinorAdjRight";
BA_ "CompuMethodName" SG_ 1104 IMinorAdjForward "MinorAdjForward";
BA_ "ISignalName" SG_ 1104 IMinorAdjForward "IMinorAdjForward";
BA_ "LongName" SG_ 1104 IMinorAdjForward "Parking Minor Adjust Forward";
BA_ "SysSignalName" SG_ 1104 IMinorAdjForward "MinorAdjForward";
BA_ "CompuMethodName" SG_ 1104 IRearWhlMinorAdjRight "RearWhlMinorAdjRight";
BA_ "ISignalName" SG_ 1104 IRearWhlMinorAdjRight "IRearWhlMinorAdjRight";
BA_ "LongName" SG_ 1104 IRearWhlMinorAdjRight "Rear Wheel Parking Minor Adjust Right";
BA_ "SysSignalName" SG_ 1104 IRearWhlMinorAdjRight "RearWhlMinorAdjRight";
BA_ "CompuMethodName" SG_ 1104 ISpeedRegulationFixedReq "SpeedRegulationFixedReq";
BA_ "ISignalName" SG_ 1104 ISpeedRegulationFixedReq "ISpeedRegulationFixedReq";
BA_ "LongName" SG_ 1104 ISpeedRegulationFixedReq "SpeedRegulationFixedReq";
BA_ "SysSignalName" SG_ 1104 ISpeedRegulationFixedReq "SpeedRegulationFixedReq";
BA_ "CompuMethodName" SG_ 1104 IMinorAdjBackward "MinorAdjBackward";
BA_ "ISignalName" SG_ 1104 IMinorAdjBackward "IMinorAdjBackward";
BA_ "LongName" SG_ 1104 IMinorAdjBackward "Parking Minor Adjust Backward";
BA_ "SysSignalName" SG_ 1104 IMinorAdjBackward "MinorAdjBackward";
BA_ "CompuMethodName" SG_ 1104 IMemParkngReq "MemParkngReq";
BA_ "ISignalName" SG_ 1104 IMemParkngReq "IMemParkngReq";
BA_ "LongName" SG_ 1104 IMemParkngReq "Memory Parking Request";
BA_ "SysSignalName" SG_ 1104 IMemParkngReq "MemParkngReq";
BA_ "CompuMethodName" SG_ 1104 IParkngOutDirChs "ParkngOutDirChs";
BA_ "ISignalName" SG_ 1104 IParkngOutDirChs "IParkngOutDirChs";
BA_ "LongName" SG_ 1104 IParkngOutDirChs "parking out direction choosen";
BA_ "SysSignalName" SG_ 1104 IParkngOutDirChs "ParkngOutDirChs";
BA_ "CompuMethodName" SG_ 1104 ISpeedRegulationPerReq "SpeedRegulationPerReq";
BA_ "ISignalName" SG_ 1104 ISpeedRegulationPerReq "ISpeedRegulationPerReq";
BA_ "LongName" SG_ 1104 ISpeedRegulationPerReq "SpeedRegulationPerReq";
BA_ "SysSignalName" SG_ 1104 ISpeedRegulationPerReq "SpeedRegulationPerReq";
BA_ "CompuMethodName" SG_ 1104 ISlntSrchParkngLotSet "SlntSrchParkngLotSet";
BA_ "ISignalName" SG_ 1104 ISlntSrchParkngLotSet "ISlntSrchParkngLotSet";
BA_ "LongName" SG_ 1104 ISlntSrchParkngLotSet "slient search parking lot function set";
BA_ "SysSignalName" SG_ 1104 ISlntSrchParkngLotSet "SlntSrchParkngLotSet";
BA_ "CompuMethodName" SG_ 1104 IDIYParkngLotSty "DIYParkngLotSty";
BA_ "ISignalName" SG_ 1104 IDIYParkngLotSty "IDIYParkngLotSty";
BA_ "LongName" SG_ 1104 IDIYParkngLotSty "DIY Parking lot style";
BA_ "SysSignalName" SG_ 1104 IDIYParkngLotSty "DIYParkngLotSty";
BA_ "CompuMethodName" SG_ 1104 IAIParkngDrvStySet "AIParkngDrvStySet";
BA_ "ISignalName" SG_ 1104 IAIParkngDrvStySet "IAIParkngDrvStySet";
BA_ "LongName" SG_ 1104 IAIParkngDrvStySet "AI Parking driving style set";
BA_ "SysSignalName" SG_ 1104 IAIParkngDrvStySet "AIParkngDrvStySet";
BA_ "CompuMethodName" SG_ 1104 IFucSwReq1 "FucSwReq1";
BA_ "ISignalName" SG_ 1104 IFucSwReq1 "IFucSwReq1";
BA_ "LongName" SG_ 1104 IFucSwReq1 "Fuction Switch Request1";
BA_ "SysSignalName" SG_ 1104 IFucSwReq1 "FucSwReq1";
BA_ "CompuMethodName" SG_ 1104 IAIParkngSpdsw "AIParkngSpdsw";
BA_ "ISignalName" SG_ 1104 IAIParkngSpdsw "IAIParkngSpdsw";
BA_ "LongName" SG_ 1104 IAIParkngSpdsw "Ai Parking speed switch";
BA_ "SysSignalName" SG_ 1104 IAIParkngSpdsw "AIParkngSpdsw";
BA_ "CompuMethodName" SG_ 1104 IMnrAdjCntrlReq "MnrAdjCntrlReq";
BA_ "ISignalName" SG_ 1104 IMnrAdjCntrlReq "IMnrAdjCntrlReq";
BA_ "LongName" SG_ 1104 IMnrAdjCntrlReq "Minor adjust control request";
BA_ "SysSignalName" SG_ 1104 IMnrAdjCntrlReq "MnrAdjCntrlReq";
BA_ "CompuMethodName" SG_ 1104 IUNPSwReq "UNPSwReq";
BA_ "ISignalName" SG_ 1104 IUNPSwReq "IUNPSwReq";
BA_ "LongName" SG_ 1104 IUNPSwReq "UNP Switch Request";
BA_ "SysSignalName" SG_ 1104 IUNPSwReq "UNPSwReq";
BA_ "CompuMethodName" SG_ 1104 IFucSwReq2 "FucSwReq2";
BA_ "ISignalName" SG_ 1104 IFucSwReq2 "IFucSwReq2";
BA_ "LongName" SG_ 1104 IFucSwReq2 "Fuction Switch Request2";
BA_ "SysSignalName" SG_ 1104 IFucSwReq2 "FucSwReq2";
BA_ "CompuMethodName" SG_ 1104 IVoicBrdstMode "VoicBrdstMode";
BA_ "ISignalName" SG_ 1104 IVoicBrdstMode "IVoicBrdstMode";
BA_ "LongName" SG_ 1104 IVoicBrdstMode "Voice Broadcast Mode";
BA_ "SysSignalName" SG_ 1104 IVoicBrdstMode "VoicBrdstMode";
BA_ "CompuMethodName" SG_ 1104 IManualpilotSwReq "ManualpilotSwReq";
BA_ "ISignalName" SG_ 1104 IManualpilotSwReq "IManualpilotSwReq";
BA_ "LongName" SG_ 1104 IManualpilotSwReq "Manual pilot Switch Request";
BA_ "SysSignalName" SG_ 1104 IManualpilotSwReq "ManualpilotSwReq";
BA_ "CompuMethodName" SG_ 1104 INrwroadsltReq "NrwroadsltReq";
BA_ "ISignalName" SG_ 1104 INrwroadsltReq "INrwroadsltReq";
BA_ "LongName" SG_ 1104 INrwroadsltReq "Narrow road forwardsilentlyReq";
BA_ "SysSignalName" SG_ 1104 INrwroadsltReq "NrwroadsltReq";
BA_ "CompuMethodName" SG_ 1104 INrwroadFwdReq "NrwroadFwdReq";
BA_ "ISignalName" SG_ 1104 INrwroadFwdReq "INrwroadFwdReq";
BA_ "LongName" SG_ 1104 INrwroadFwdReq "Narrow road forwardReq";
BA_ "SysSignalName" SG_ 1104 INrwroadFwdReq "NrwroadFwdReq";
BA_ "CompuMethodName" SG_ 1104 IPilotplusSwReq "PilotplusSwReq";
BA_ "ISignalName" SG_ 1104 IPilotplusSwReq "IPilotplusSwReq";
BA_ "LongName" SG_ 1104 IPilotplusSwReq "Pilot plus Switch Request";
BA_ "SysSignalName" SG_ 1104 IPilotplusSwReq "PilotplusSwReq";
BA_ "CompuMethodName" SG_ 1104 IParkngrampastsltReq "ParkngrampastsltReq";
BA_ "ISignalName" SG_ 1104 IParkngrampastsltReq "IParkngrampastsltReq";
BA_ "LongName" SG_ 1104 IParkngrampastsltReq "Parking ramp assistsilentlyReq";
BA_ "SysSignalName" SG_ 1104 IParkngrampastsltReq "ParkngrampastsltReq";
BA_ "CompuMethodName" SG_ 1104 IParkngrampastReq "ParkngrampastReq";
BA_ "ISignalName" SG_ 1104 IParkngrampastReq "IParkngrampastReq";
BA_ "LongName" SG_ 1104 IParkngrampastReq "Parking ramp assistReq";
BA_ "SysSignalName" SG_ 1104 IParkngrampastReq "ParkngrampastReq";
BA_ "CompuMethodName" SG_ 1104 IParkngOutRcmnSet "ParkngOutRcmnSet";
BA_ "ISignalName" SG_ 1104 IParkngOutRcmnSet "IParkngOutRcmnSet";
BA_ "LongName" SG_ 1104 IParkngOutRcmnSet "parking out recommand set";
BA_ "SysSignalName" SG_ 1104 IParkngOutRcmnSet "ParkngOutRcmnSet";
BA_ "CompuMethodName" SG_ 1104 IAIParkngOutSty "AIParkngOutSty";
BA_ "ISignalName" SG_ 1104 IAIParkngOutSty "IAIParkngOutSty";
BA_ "LongName" SG_ 1104 IAIParkngOutSty "AI Parking out style";
BA_ "SysSignalName" SG_ 1104 IAIParkngOutSty "AIParkngOutSty";
BA_ "CompuMethodName" SG_ 1104 IRvrsTrckParkng "RvrsTrckParkng";
BA_ "ISignalName" SG_ 1104 IRvrsTrckParkng "IRvrsTrckParkng";
BA_ "LongName" SG_ 1104 IRvrsTrckParkng "Reverse tracking parking";
BA_ "SysSignalName" SG_ 1104 IRvrsTrckParkng "RvrsTrckParkng";
BA_ "CompuMethodName" SG_ 1104 ISpeedRegulationModeReq "SpeedRegulationModeReq";
BA_ "ISignalName" SG_ 1104 ISpeedRegulationModeReq "ISpeedRegulationModeReq";
BA_ "LongName" SG_ 1104 ISpeedRegulationModeReq "SpeedRegulationModeReq";
BA_ "SysSignalName" SG_ 1104 ISpeedRegulationModeReq "SpeedRegulationModeReq";
BA_ "CompuMethodName" SG_ 1104 IMnrAdjReq "MnrAdjReq";
BA_ "ISignalName" SG_ 1104 IMnrAdjReq "IMnrAdjReq";
BA_ "LongName" SG_ 1104 IMnrAdjReq "Minor adjust request";
BA_ "SysSignalName" SG_ 1104 IMnrAdjReq "MnrAdjReq";
BA_ "CompuMethodName" SG_ 1104 IDIYParkngLotReq "DIYParkngLotReq";
BA_ "ISignalName" SG_ 1104 IDIYParkngLotReq "IDIYParkngLotReq";
BA_ "LongName" SG_ 1104 IDIYParkngLotReq "DIY Parking lot function request";
BA_ "SysSignalName" SG_ 1104 IDIYParkngLotReq "DIYParkngLotReq";
BA_ "CompuMethodName" SG_ 1104 IEdtNameInd "EdtNameInd";
BA_ "ISignalName" SG_ 1104 IEdtNameInd "IEdtNameInd";
BA_ "LongName" SG_ 1104 IEdtNameInd "edit path name Indicate";
BA_ "SysSignalName" SG_ 1104 IEdtNameInd "EdtNameInd";
BA_ "CompuMethodName" SG_ 1104 ITryMemParkngNw "TryMemParkngNw";
BA_ "ISignalName" SG_ 1104 ITryMemParkngNw "ITryMemParkngNw";
BA_ "LongName" SG_ 1104 ITryMemParkngNw "Try memory parking now";
BA_ "SysSignalName" SG_ 1104 ITryMemParkngNw "TryMemParkngNw";
BA_ "CompuMethodName" SG_ 1104 IDIYParkngLotSet "DIYParkngLotSet";
BA_ "ISignalName" SG_ 1104 IDIYParkngLotSet "IDIYParkngLotSet";
BA_ "LongName" SG_ 1104 IDIYParkngLotSet "DIY parking lot function set";
BA_ "SysSignalName" SG_ 1104 IDIYParkngLotSet "DIYParkngLotSet";
BA_ "CompuMethodName" SG_ 1104 IParkngrampastCtlReq "ParkngrampastCtlReq";
BA_ "ISignalName" SG_ 1104 IParkngrampastCtlReq "IParkngrampastCtlReq";
BA_ "LongName" SG_ 1104 IParkngrampastCtlReq "Parking ramp assist control requst";
BA_ "SysSignalName" SG_ 1104 IParkngrampastCtlReq "ParkngrampastCtlReq";
BA_ "CompuMethodName" SG_ 832 IAIPilotSwReq "AIPilotSwReq";
BA_ "ISignalName" SG_ 832 IAIPilotSwReq "IAIPilotSwReq";
BA_ "LongName" SG_ 832 IAIPilotSwReq "Aipilot_Switch_Command";
BA_ "SysSignalName" SG_ 832 IAIPilotSwReq "AIPilotSwReq";
BA_ "CompuMethodName" SG_ 832 IAIPilotDrvMdlReq "AIPilotDrvMdlReq";
BA_ "ISignalName" SG_ 832 IAIPilotDrvMdlReq "IAIPilotDrvMdlReq";
BA_ "LongName" SG_ 832 IAIPilotDrvMdlReq "Ai Pilot Drive Model Request";
BA_ "SysSignalName" SG_ 832 IAIPilotDrvMdlReq "AIPilotDrvMdlReq";
BA_ "CompuMethodName" SG_ 832 IFCWSnstvtLvlReq "FCWSnstvtLvlReq";
BA_ "ISignalName" SG_ 832 IFCWSnstvtLvlReq "IFCWSnstvtLvlReq";
BA_ "LongName" SG_ 832 IFCWSnstvtLvlReq "Forward_Collision_Warning_Sensitivity_Level_Request";
BA_ "SysSignalName" SG_ 832 IFCWSnstvtLvlReq "FCWSnstvtLvlReq";
BA_ "CompuMethodName" SG_ 832 IELKSwReq "ELKSwReq";
BA_ "ISignalName" SG_ 832 IELKSwReq "IELKSwReq";
BA_ "LongName" SG_ 832 IELKSwReq "Emergency Lane Keeping Switch Request";
BA_ "SysSignalName" SG_ 832 IELKSwReq "ELKSwReq";
BA_ "CompuMethodName" SG_ 832 ILDWAdoWrnngReq "LDWAdoWrnngReq";
BA_ "ISignalName" SG_ 832 ILDWAdoWrnngReq "ILDWAdoWrnngReq";
BA_ "LongName" SG_ 832 ILDWAdoWrnngReq "Lane_Departure_Warning_Audio_Warning_Request";
BA_ "SysSignalName" SG_ 832 ILDWAdoWrnngReq "LDWAdoWrnngReq";
BA_ "CompuMethodName" SG_ 832 IFCWSwReq "FCWSwReq";
BA_ "ISignalName" SG_ 832 IFCWSwReq "IFCWSwReq";
BA_ "LongName" SG_ 832 IFCWSwReq "Forward_Collision_Warning_Switch_Request";
BA_ "SysSignalName" SG_ 832 IFCWSwReq "FCWSwReq";
BA_ "CompuMethodName" SG_ 832 ITrfcLghtFuctionSwReq "TrfcLghtFuctionSwReq";
BA_ "ISignalName" SG_ 832 ITrfcLghtFuctionSwReq "ITrfcLghtFuctionSwReq";
BA_ "LongName" SG_ 832 ITrfcLghtFuctionSwReq "Traffic_Light_Fuction_Switch_Request";
BA_ "SysSignalName" SG_ 832 ITrfcLghtFuctionSwReq "TrfcLghtFuctionSwReq";
BA_ "CompuMethodName" SG_ 832 IDOWSelReq "DOWSelReq";
BA_ "ISignalName" SG_ 832 IDOWSelReq "IDOWSelReq";
BA_ "LongName" SG_ 832 IDOWSelReq "Door_Open_Warning_Select_Request";
BA_ "SysSignalName" SG_ 832 IDOWSelReq "DOWSelReq";
BA_ "CompuMethodName" SG_ 832 IBSDSelReq "BSDSelReq";
BA_ "ISignalName" SG_ 832 IBSDSelReq "IBSDSelReq";
BA_ "LongName" SG_ 832 IBSDSelReq "Blind_Spot_Detect_Select_Request";
BA_ "SysSignalName" SG_ 832 IBSDSelReq "BSDSelReq";
BA_ "CompuMethodName" SG_ 832 IAIPilotAudSwReq "AIPilotAudSwReq";
BA_ "ISignalName" SG_ 832 IAIPilotAudSwReq "IAIPilotAudSwReq";
BA_ "LongName" SG_ 832 IAIPilotAudSwReq "Ai Pilot Audio Switch Request";
BA_ "SysSignalName" SG_ 832 IAIPilotAudSwReq "AIPilotAudSwReq";
BA_ "CompuMethodName" SG_ 832 IEndToEndPilotSwReq "EndToEndPilotSwReq";
BA_ "ISignalName" SG_ 832 IEndToEndPilotSwReq "IEndToEndPilotSwReq";
BA_ "LongName" SG_ 832 IEndToEndPilotSwReq "End To End Pilot Switch Request";
BA_ "SysSignalName" SG_ 832 IEndToEndPilotSwReq "EndToEndPilotSwReq";
BA_ "CompuMethodName" SG_ 832 ILaneChngRecmedMdlReq "LaneChngRecmedMdlReq";
BA_ "ISignalName" SG_ 832 ILaneChngRecmedMdlReq "ILaneChngRecmedMdlReq";
BA_ "LongName" SG_ 832 ILaneChngRecmedMdlReq "Lane_Change_Recommend_Model_Request";
BA_ "SysSignalName" SG_ 832 ILaneChngRecmedMdlReq "LaneChngRecmedMdlReq";
BA_ "CompuMethodName" SG_ 832 IAEBSwReq "AEBSwReq";
BA_ "ISignalName" SG_ 832 IAEBSwReq "IAEBSwReq";
BA_ "LongName" SG_ 832 IAEBSwReq "Autonomous_Emergency_Braking_Switch_Request";
BA_ "SysSignalName" SG_ 832 IAEBSwReq "AEBSwReq";
BA_ "CompuMethodName" SG_ 832 ILDWLKAHptWrnngReq "LDWLKAHptWrnngReq";
BA_ "ISignalName" SG_ 832 ILDWLKAHptWrnngReq "ILDWLKAHptWrnngReq";
BA_ "LongName" SG_ 832 ILDWLKAHptWrnngReq "Lane_Departure_Warning_Lane_Keeping_Haptic_Assist_Warning_Request";
BA_ "SysSignalName" SG_ 832 ILDWLKAHptWrnngReq "LDWLKAHptWrnngReq";
BA_ "CompuMethodName" SG_ 832 IRCWSelReq "RCWSelReq";
BA_ "ISignalName" SG_ 832 IRCWSelReq "IRCWSelReq";
BA_ "LongName" SG_ 832 IRCWSelReq "Rear_Collision_Warningselect_Request";
BA_ "SysSignalName" SG_ 832 IRCWSelReq "RCWSelReq";
BA_ "CompuMethodName" SG_ 832 ILaneChngCnfmSwReq "LaneChngCnfmSwReq";
BA_ "ISignalName" SG_ 832 ILaneChngCnfmSwReq "ILaneChngCnfmSwReq";
BA_ "LongName" SG_ 832 ILaneChngCnfmSwReq "Lane Change Confirm Switch Request";
BA_ "SysSignalName" SG_ 832 ILaneChngCnfmSwReq "LaneChngCnfmSwReq";
BA_ "CompuMethodName" SG_ 832 IIntscnDclSwReq "IntscnDclSwReq";
BA_ "ISignalName" SG_ 832 IIntscnDclSwReq "IIntscnDclSwReq";
BA_ "LongName" SG_ 832 IIntscnDclSwReq "Intersection Deceleration Switch Request";
BA_ "SysSignalName" SG_ 832 IIntscnDclSwReq "IntscnDclSwReq";
BA_ "CompuMethodName" SG_ 832 IIntlgntParkngWifiSwReq "IntlgntParkngWifiSwReq";
BA_ "ISignalName" SG_ 832 IIntlgntParkngWifiSwReq "IIntlgntParkngWifiSwReq";
BA_ "LongName" SG_ 832 IIntlgntParkngWifiSwReq "Intelligent Parking Wifi Switch Request";
BA_ "SysSignalName" SG_ 832 IIntlgntParkngWifiSwReq "IntlgntParkngWifiSwReq";
BA_ "CompuMethodName" SG_ 832 IIntlgntParkngNavSwReq "IntlgntParkngNavSwReq";
BA_ "ISignalName" SG_ 832 IIntlgntParkngNavSwReq "IIntlgntParkngNavSwReq";
BA_ "LongName" SG_ 832 IIntlgntParkngNavSwReq "Intelligent Parking Navigation Switch Request";
BA_ "SysSignalName" SG_ 832 IIntlgntParkngNavSwReq "IntlgntParkngNavSwReq";
BA_ "CompuMethodName" SG_ 832 INOASwReq "NOASwReq";
BA_ "ISignalName" SG_ 832 INOASwReq "INOASwReq";
BA_ "LongName" SG_ 832 INOASwReq "Noa Switch Request";
BA_ "SysSignalName" SG_ 832 INOASwReq "NOASwReq";
BA_ "CompuMethodName" SG_ 832 INOAQukSwReq "NOAQukSwReq";
BA_ "ISignalName" SG_ 832 INOAQukSwReq "INOAQukSwReq";
BA_ "LongName" SG_ 832 INOAQukSwReq "Noa Quick Switch Request";
BA_ "SysSignalName" SG_ 832 INOAQukSwReq "NOAQukSwReq";
BA_ "CompuMethodName" SG_ 832 INarwSpcAstSwReq "NarwSpcAstSwReq";
BA_ "ISignalName" SG_ 832 INarwSpcAstSwReq "INarwSpcAstSwReq";
BA_ "LongName" SG_ 832 INarwSpcAstSwReq "Narrow Space Assist Switch Request";
BA_ "SysSignalName" SG_ 832 INarwSpcAstSwReq "NarwSpcAstSwReq";
BA_ "CompuMethodName" SG_ 832 ILaneChngWrnngSwReq "LaneChngWrnngSwReq";
BA_ "ISignalName" SG_ 832 ILaneChngWrnngSwReq "ILaneChngWrnngSwReq";
BA_ "LongName" SG_ 832 ILaneChngWrnngSwReq "Lane Change Warning Switch Request";
BA_ "SysSignalName" SG_ 832 ILaneChngWrnngSwReq "LaneChngWrnngSwReq";
BA_ "CompuMethodName" SG_ 832 ILDWSnstvtLvlReq "LDWSnstvtLvlReq";
BA_ "ISignalName" SG_ 832 ILDWSnstvtLvlReq "ILDWSnstvtLvlReq";
BA_ "LongName" SG_ 832 ILDWSnstvtLvlReq "Lane_Departure_Warning_Sensitivity_Level_Request";
BA_ "SysSignalName" SG_ 832 ILDWSnstvtLvlReq "LDWSnstvtLvlReq";
BA_ "CompuMethodName" SG_ 832 IRembParkngInPrmtSwReq "RembParkngInPrmtSwReq";
BA_ "ISignalName" SG_ 832 IRembParkngInPrmtSwReq "IRembParkngInPrmtSwReq";
BA_ "LongName" SG_ 832 IRembParkngInPrmtSwReq "Remember Parking In Prompt Switch Request";
BA_ "SysSignalName" SG_ 832 IRembParkngInPrmtSwReq "RembParkngInPrmtSwReq";
BA_ "CompuMethodName" SG_ 832 IRDASwReq "RDASwReq";
BA_ "ISignalName" SG_ 832 IRDASwReq "IRDASwReq";
BA_ "LongName" SG_ 832 IRDASwReq "Rear_Drive_Assist_Switch_Request";
BA_ "SysSignalName" SG_ 832 IRDASwReq "RDASwReq";
BA_ "CompuMethodName" SG_ 832 IRCTSysSelReq "RCTSysSelReq";
BA_ "ISignalName" SG_ 832 IRCTSysSelReq "IRCTSysSelReq";
BA_ "LongName" SG_ 832 IRCTSysSelReq "Rear_Cross_Traffic_System_Select_Request";
BA_ "SysSignalName" SG_ 832 IRCTSysSelReq "RCTSysSelReq";
BA_ "CompuMethodName" SG_ 832 ILCASelReq "LCASelReq";
BA_ "ISignalName" SG_ 832 ILCASelReq "ILCASelReq";
BA_ "LongName" SG_ 832 ILCASelReq "Lane_Change_Assist_Select_Request";
BA_ "SysSignalName" SG_ 832 ILCASelReq "LCASelReq";
BA_ "CompuMethodName" SG_ 832 ILDWLKASwReq "LDWLKASwReq";
BA_ "ISignalName" SG_ 832 ILDWLKASwReq "ILDWLKASwReq";
BA_ "LongName" SG_ 832 ILDWLKASwReq "Lane_Departure_Warning_Lane_Keeping_Assist_Switch_Request";
BA_ "SysSignalName" SG_ 832 ILDWLKASwReq "LDWLKASwReq";
BA_ "CompuMethodName" SG_ 832 ISpdLmtMdlReq "SpdLmtMdlReq";
BA_ "ISignalName" SG_ 832 ISpdLmtMdlReq "ISpdLmtMdlReq";
BA_ "LongName" SG_ 832 ISpdLmtMdlReq "Speed_Limit_Modle_Request";
BA_ "SysSignalName" SG_ 832 ISpdLmtMdlReq "SpdLmtMdlReq";
BA_ "CompuMethodName" SG_ 836 IDIYParkngSpcConfirming "DIYParkngSpcConfirming";
BA_ "ISignalName" SG_ 836 IDIYParkngSpcConfirming "IDIYParkngSpcConfirming";
BA_ "LongName" SG_ 836 IDIYParkngSpcConfirming "Diy Parking Space Confirming";
BA_ "SysSignalName" SG_ 836 IDIYParkngSpcConfirming "DIYParkngSpcConfirming";
BA_ "CompuMethodName" SG_ 836 IRembParkngInMapngReq "RembParkngInMapngReq";
BA_ "ISignalName" SG_ 836 IRembParkngInMapngReq "IRembParkngInMapngReq";
BA_ "LongName" SG_ 836 IRembParkngInMapngReq "Remember Parking In Mapping Request";
BA_ "SysSignalName" SG_ 836 IRembParkngInMapngReq "RembParkngInMapngReq";
BA_ "CompuMethodName" SG_ 836 IRembParkngInMapngIndcrCnfm "RembParkngInMapngIndcrCnfm";
BA_ "ISignalName" SG_ 836 IRembParkngInMapngIndcrCnfm "IRembParkngInMapngIndcrCnfm";
BA_ "LongName" SG_ 836 IRembParkngInMapngIndcrCnfm "Remember Parking In Mapping Indicator Confirm";
BA_ "SysSignalName" SG_ 836 IRembParkngInMapngIndcrCnfm "RembParkngInMapngIndcrCnfm";
BA_ "CompuMethodName" SG_ 836 IHdngAng_ICM "HdngAng_ICM";
BA_ "ISignalName" SG_ 836 IHdngAng_ICM "IHdngAng_ICM";
BA_ "LongName" SG_ 836 IHdngAng_ICM "Heading Angle ICM";
BA_ "SysSignalName" SG_ 836 IHdngAng_ICM "HdngAng_ICM";
BA_ "CompuMethodName" SG_ 836 IRembParkngInPrmtCnfm "RembParkngInPrmtCnfm";
BA_ "ISignalName" SG_ 836 IRembParkngInPrmtCnfm "IRembParkngInPrmtCnfm";
BA_ "LongName" SG_ 836 IRembParkngInPrmtCnfm "Remember Parking In Prompt Confirm";
BA_ "SysSignalName" SG_ 836 IRembParkngInPrmtCnfm "RembParkngInPrmtCnfm";
BA_ "CompuMethodName" SG_ 836 IPkDnPntID "PkDnPntID";
BA_ "ISignalName" SG_ 836 IPkDnPntID "IPkDnPntID";
BA_ "LongName" SG_ 836 IPkDnPntID "Pick Down Point Identification";
BA_ "SysSignalName" SG_ 836 IPkDnPntID "PkDnPntID";
BA_ "CompuMethodName" SG_ 836 IParkLotID "ParkLotID";
BA_ "ISignalName" SG_ 836 IParkLotID "IParkLotID";
BA_ "LongName" SG_ 836 IParkLotID "Parking Lot Identification";
BA_ "SysSignalName" SG_ 836 IParkLotID "ParkLotID";
BA_ "CompuMethodName" SG_ 836 IRembParkngInMapRutDltReq "RembParkngInMapRutDltReq";
BA_ "ISignalName" SG_ 836 IRembParkngInMapRutDltReq "IRembParkngInMapRutDltReq";
BA_ "LongName" SG_ 836 IRembParkngInMapRutDltReq "Remember Parking In Map Route Delete Request";
BA_ "SysSignalName" SG_ 836 IRembParkngInMapRutDltReq "RembParkngInMapRutDltReq";
BA_ "CompuMethodName" SG_ 836 IRembParkngInMapRutReq "RembParkngInMapRutReq";
BA_ "ISignalName" SG_ 836 IRembParkngInMapRutReq "IRembParkngInMapRutReq";
BA_ "LongName" SG_ 836 IRembParkngInMapRutReq "Remember Parking In Map Route Request";
BA_ "SysSignalName" SG_ 836 IRembParkngInMapRutReq "RembParkngInMapRutReq";
BA_ "CompuMethodName" SG_ 836 IIPDStsReq "IPDStsReq";
BA_ "ISignalName" SG_ 836 IIPDStsReq "IIPDStsReq";
BA_ "LongName" SG_ 836 IIPDStsReq "IPD Status Request";
BA_ "SysSignalName" SG_ 836 IIPDStsReq "IPDStsReq";
BA_ "CompuMethodName" SG_ 836 IRembParkngInMapngRutIDCnfm "RembParkngInMapngRutIDCnfm";
BA_ "ISignalName" SG_ 836 IRembParkngInMapngRutIDCnfm "IRembParkngInMapngRutIDCnfm";
BA_ "LongName" SG_ 836 IRembParkngInMapngRutIDCnfm "Remember Parking In Maping Route Id Confirm";
BA_ "SysSignalName" SG_ 836 IRembParkngInMapngRutIDCnfm "RembParkngInMapngRutIDCnfm";
BA_ "CompuMethodName" SG_ 1007 IGNSSVelNorthsecinfo "GNSSVelNorthsecinfo";
BA_ "ISignalName" SG_ 1007 IGNSSVelNorthsecinfo "IGNSSVelNorthsecinfo";
BA_ "LongName" SG_ 1007 IGNSSVelNorthsecinfo "Gnss_Vel_North";
BA_ "SysSignalName" SG_ 1007 IGNSSVelNorthsecinfo "GNSSVelNorthsecinfo";
BA_ "CompuMethodName" SG_ 1007 IGNSSVelUpsecinfo "GNSSVelUpsecinfo";
BA_ "ISignalName" SG_ 1007 IGNSSVelUpsecinfo "IGNSSVelUpsecinfo";
BA_ "LongName" SG_ 1007 IGNSSVelUpsecinfo "Gnss_Vel_Up";
BA_ "SysSignalName" SG_ 1007 IGNSSVelUpsecinfo "GNSSVelUpsecinfo";
BA_ "CompuMethodName" SG_ 868 IAltSigmaGPSsecinfo "AltSigmaGPSsecinfo";
BA_ "ISignalName" SG_ 868 IAltSigmaGPSsecinfo "IAltSigmaGPSsecinfo";
BA_ "LongName" SG_ 868 IAltSigmaGPSsecinfo "Alt_Sigma_Gps";
BA_ "SysSignalName" SG_ 868 IAltSigmaGPSsecinfo "AltSigmaGPSsecinfo";
BA_ "CompuMethodName" SG_ 868 IGNSSPitchsecinfo "GNSSPitchsecinfo";
BA_ "ISignalName" SG_ 868 IGNSSPitchsecinfo "IGNSSPitchsecinfo";
BA_ "LongName" SG_ 868 IGNSSPitchsecinfo "GNSSPitch";
BA_ "SysSignalName" SG_ 868 IGNSSPitchsecinfo "GNSSPitchsecinfo";
BA_ "CompuMethodName" SG_ 868 IPitchSigmaGPSsecinfo "PitchSigmaGPSsecinfo";
BA_ "ISignalName" SG_ 868 IPitchSigmaGPSsecinfo "IPitchSigmaGPSsecinfo";
BA_ "LongName" SG_ 868 IPitchSigmaGPSsecinfo "Pitch_Sigma_Gps";
BA_ "SysSignalName" SG_ 868 IPitchSigmaGPSsecinfo "PitchSigmaGPSsecinfo";
BA_ "CompuMethodName" SG_ 827 IGNSSLatitudesecinfo "GNSSLatitudesecinfo";
BA_ "ISignalName" SG_ 827 IGNSSLatitudesecinfo "IGNSSLatitudesecinfo";
BA_ "LongName" SG_ 827 IGNSSLatitudesecinfo "Gnss_Latitude";
BA_ "SysSignalName" SG_ 827 IGNSSLatitudesecinfo "GNSSLatitudesecinfo";
BA_ "CompuMethodName" SG_ 828 IGNSSHeadingsecinfo "GNSSHeadingsecinfo";
BA_ "ISignalName" SG_ 828 IGNSSHeadingsecinfo "IGNSSHeadingsecinfo";
BA_ "LongName" SG_ 828 IGNSSHeadingsecinfo "Gnss_Heading";
BA_ "SysSignalName" SG_ 828 IGNSSHeadingsecinfo "GNSSHeadingsecinfo";
BA_ "CompuMethodName" SG_ 828 IGNSSHeightsecinfo "GNSSHeightsecinfo";
BA_ "ISignalName" SG_ 828 IGNSSHeightsecinfo "IGNSSHeightsecinfo";
BA_ "LongName" SG_ 828 IGNSSHeightsecinfo "Gnss_Height";
BA_ "SysSignalName" SG_ 828 IGNSSHeightsecinfo "GNSSHeightsecinfo";
BA_ "CompuMethodName" SG_ 683 IDrvrUseIDBradcst "DrvrUseIDBradcst";
BA_ "ISignalName" SG_ 683 IDrvrUseIDBradcst "IDrvrUseIDBradcst";
BA_ "LongName" SG_ 683 IDrvrUseIDBradcst "Driver User Identity Broadcast";
BA_ "SysSignalName" SG_ 683 IDrvrUseIDBradcst "DrvrUseIDBradcst";
BA_ "CompuMethodName" SG_ 683 IDrvrUseIDRoleInfo "DrvrUseIDRoleInfo";
BA_ "ISignalName" SG_ 683 IDrvrUseIDRoleInfo "IDrvrUseIDRoleInfo";
BA_ "LongName" SG_ 683 IDrvrUseIDRoleInfo "Driver User Identity Role Information";
BA_ "SysSignalName" SG_ 683 IDrvrUseIDRoleInfo "DrvrUseIDRoleInfo";
BA_ "CompuMethodName" SG_ 824 IHeadingSigmaGPSsecinfo "HeadingSigmaGPSsecinfo";
BA_ "ISignalName" SG_ 824 IHeadingSigmaGPSsecinfo "IHeadingSigmaGPSsecinfo";
BA_ "LongName" SG_ 824 IHeadingSigmaGPSsecinfo "Heading_Sigma_Gps";
BA_ "SysSignalName" SG_ 824 IHeadingSigmaGPSsecinfo "HeadingSigmaGPSsecinfo";
BA_ "CompuMethodName" SG_ 824 ILatSigmaGPSsecinfo "LatSigmaGPSsecinfo";
BA_ "ISignalName" SG_ 824 ILatSigmaGPSsecinfo "ILatSigmaGPSsecinfo";
BA_ "LongName" SG_ 824 ILatSigmaGPSsecinfo "Lat_Sigma_Gps";
BA_ "SysSignalName" SG_ 824 ILatSigmaGPSsecinfo "LatSigmaGPSsecinfo";
BA_ "CompuMethodName" SG_ 824 ILonSigmaGPSsecinfo "LonSigmaGPSsecinfo";
BA_ "ISignalName" SG_ 824 ILonSigmaGPSsecinfo "ILonSigmaGPSsecinfo";
BA_ "LongName" SG_ 824 ILonSigmaGPSsecinfo "Lon_Sigma_Gps";
BA_ "SysSignalName" SG_ 824 ILonSigmaGPSsecinfo "LonSigmaGPSsecinfo";
BA_ "CompuMethodName" SG_ 826 IGNSSLongitudesecinfo "GNSSLongitudesecinfo";
BA_ "ISignalName" SG_ 826 IGNSSLongitudesecinfo "IGNSSLongitudesecinfo";
BA_ "LongName" SG_ 826 IGNSSLongitudesecinfo "Gnss_Longitude";
BA_ "SysSignalName" SG_ 826 IGNSSLongitudesecinfo "GNSSLongitudesecinfo";
BA_ "CompuMethodName" SG_ 823 IGNSSUsedSatNumsecinfo "GNSSUsedSatNumsecinfo";
BA_ "ISignalName" SG_ 823 IGNSSUsedSatNumsecinfo "IGNSSUsedSatNumsecinfo";
BA_ "LongName" SG_ 823 IGNSSUsedSatNumsecinfo "Gnss_Used_Sat_Num";
BA_ "SysSignalName" SG_ 823 IGNSSUsedSatNumsecinfo "GNSSUsedSatNumsecinfo";
BA_ "CompuMethodName" SG_ 823 IGPSStatussecinfo "GPSStatussecinfo";
BA_ "ISignalName" SG_ 823 IGPSStatussecinfo "IGPSStatussecinfo";
BA_ "LongName" SG_ 823 IGPSStatussecinfo "Gps_Status";
BA_ "SysSignalName" SG_ 823 IGPSStatussecinfo "GPSStatussecinfo";
BA_ "CompuMethodName" SG_ 823 IRTKDelaysecinfo "RTKDelaysecinfo";
BA_ "ISignalName" SG_ 823 IRTKDelaysecinfo "IRTKDelaysecinfo";
BA_ "LongName" SG_ 823 IRTKDelaysecinfo "Rtk_Delay";
BA_ "SysSignalName" SG_ 823 IRTKDelaysecinfo "RTKDelaysecinfo";
BA_ "CompuMethodName" SG_ 823 IVehiclesStatussecinfo "VehiclesStatussecinfo";
BA_ "ISignalName" SG_ 823 IVehiclesStatussecinfo "IVehiclesStatussecinfo";
BA_ "LongName" SG_ 823 IVehiclesStatussecinfo "Vehicles_Status";
BA_ "SysSignalName" SG_ 823 IVehiclesStatussecinfo "VehiclesStatussecinfo";
BA_ "CompuMethodName" SG_ 823 IGPSHeadingStatussecinfo "GPSHeadingStatussecinfo";
BA_ "ISignalName" SG_ 823 IGPSHeadingStatussecinfo "IGPSHeadingStatussecinfo";
BA_ "LongName" SG_ 823 IGPSHeadingStatussecinfo "Gps_Heading_Status";
BA_ "SysSignalName" SG_ 823 IGPSHeadingStatussecinfo "GPSHeadingStatussecinfo";
BA_ "CompuMethodName" SG_ 823 IECUWarningsecinfo "ECUWarningsecinfo";
BA_ "ISignalName" SG_ 823 IECUWarningsecinfo "IECUWarningsecinfo";
BA_ "LongName" SG_ 823 IECUWarningsecinfo "Ecu_Warning";
BA_ "SysSignalName" SG_ 823 IECUWarningsecinfo "ECUWarningsecinfo";
BA_ "CompuMethodName" SG_ 823 IGPSWarningsecinfo "GPSWarningsecinfo";
BA_ "ISignalName" SG_ 823 IGPSWarningsecinfo "IGPSWarningsecinfo";
BA_ "LongName" SG_ 823 IGPSWarningsecinfo "Gps_Warning";
BA_ "SysSignalName" SG_ 823 IGPSWarningsecinfo "GPSWarningsecinfo";
BA_ "CompuMethodName" SG_ 823 IGPSPosStatussecinfo "GPSPosStatussecinfo";
BA_ "ISignalName" SG_ 823 IGPSPosStatussecinfo "IGPSPosStatussecinfo";
BA_ "LongName" SG_ 823 IGPSPosStatussecinfo "Gps_Pos_Status";
BA_ "SysSignalName" SG_ 823 IGPSPosStatussecinfo "GPSPosStatussecinfo";
BA_ "CompuMethodName" SG_ 823 IGPSVelStatussecinfo "GPSVelStatussecinfo";
BA_ "ISignalName" SG_ 823 IGPSVelStatussecinfo "IGPSVelStatussecinfo";
BA_ "LongName" SG_ 823 IGPSVelStatussecinfo "Gps_Vel_Status";
BA_ "SysSignalName" SG_ 823 IGPSVelStatussecinfo "GPSVelStatussecinfo";
BA_ "CompuMethodName" SG_ 825 IATGyawsecinfo "ATGyawsecinfo";
BA_ "ISignalName" SG_ 825 IATGyawsecinfo "IATGyawsecinfo";
BA_ "LongName" SG_ 825 IATGyawsecinfo "Atg_Yaw";
BA_ "SysSignalName" SG_ 825 IATGyawsecinfo "ATGyawsecinfo";
BA_ "CompuMethodName" SG_ 825 IVeldownsigmaGPSsecinfo "VeldownsigmaGPSsecinfo";
BA_ "ISignalName" SG_ 825 IVeldownsigmaGPSsecinfo "IVeldownsigmaGPSsecinfo";
BA_ "LongName" SG_ 825 IVeldownsigmaGPSsecinfo "Veldown_Sigma_Gps";
BA_ "SysSignalName" SG_ 825 IVeldownsigmaGPSsecinfo "VeldownsigmaGPSsecinfo";
BA_ "CompuMethodName" SG_ 825 IVeleastsigmaGPSsecinfo "VeleastsigmaGPSsecinfo";
BA_ "ISignalName" SG_ 825 IVeleastsigmaGPSsecinfo "IVeleastsigmaGPSsecinfo";
BA_ "LongName" SG_ 825 IVeleastsigmaGPSsecinfo "Veleast_Sigma_Gps";
BA_ "SysSignalName" SG_ 825 IVeleastsigmaGPSsecinfo "VeleastsigmaGPSsecinfo";
BA_ "CompuMethodName" SG_ 825 IVelnorthsigmaGPSsecinfo "VelnorthsigmaGPSsecinfo";
BA_ "ISignalName" SG_ 825 IVelnorthsigmaGPSsecinfo "IVelnorthsigmaGPSsecinfo";
BA_ "LongName" SG_ 825 IVelnorthsigmaGPSsecinfo "Velnorth_Sigma_Gps";
BA_ "SysSignalName" SG_ 825 IVelnorthsigmaGPSsecinfo "VelnorthsigmaGPSsecinfo";
BA_ "CompuMethodName" SG_ 901 IICBVC_100ms_Group78_CRC "ICBVC_100ms_Group78_CRC";
BA_ "ISignalName" SG_ 901 IICBVC_100ms_Group78_CRC "IICBVC_100ms_Group78_CRC";
BA_ "SysSignalName" SG_ 901 IICBVC_100ms_Group78_CRC "ICBVC_100ms_Group78_CRC";
BA_ "CompuMethodName" SG_ 901 IICBVC_100ms_Group78_RC "ICBVC_100ms_Group78_RC";
BA_ "ISignalName" SG_ 901 IICBVC_100ms_Group78_RC "IICBVC_100ms_Group78_RC";
BA_ "SysSignalName" SG_ 901 IICBVC_100ms_Group78_RC "ICBVC_100ms_Group78_RC";
BA_ "CompuMethodName" SG_ 901 IICBVC_100ms_Group78_Reserved1 "ICBVC_100ms_Group78_Reserved1";
BA_ "GenSigStartValue" SG_ 901 IICBVC_100ms_Group78_Reserved1 3;
BA_ "ISignalName" SG_ 901 IICBVC_100ms_Group78_Reserved1 "IICBVC_100ms_Group78_Reserved1";
BA_ "SysSignalName" SG_ 901 IICBVC_100ms_Group78_Reserved1 "ICBVC_100ms_Group78_Reserved1";
BA_ "CompuMethodName" SG_ 901 IIPKDErSts "IPKDErSts";
BA_ "ISignalName" SG_ 901 IIPKDErSts "IIPKDErSts";
BA_ "LongName" SG_ 901 IIPKDErSts "Instrument Cluster Display Error Status";
BA_ "SysSignalName" SG_ 901 IIPKDErSts "IPKDErSts";
BA_ "CompuMethodName" SG_ 901 IICBVC_100ms_Group78_Reserved2 "ICBVC_100ms_Group78_Reserved2";
BA_ "GenSigStartValue" SG_ 901 IICBVC_100ms_Group78_Reserved2 255;
BA_ "ISignalName" SG_ 901 IICBVC_100ms_Group78_Reserved2 "IICBVC_100ms_Group78_Reserved2";
BA_ "SysSignalName" SG_ 901 IICBVC_100ms_Group78_Reserved2 "ICBVC_100ms_Group78_Reserved2";
BA_ "CompuMethodName" SG_ 901 IICBVC_100ms_Group78_Reserved3 "ICBVC_100ms_Group78_Reserved3";
BA_ "GenSigStartValue" SG_ 901 IICBVC_100ms_Group78_Reserved3 255;
BA_ "ISignalName" SG_ 901 IICBVC_100ms_Group78_Reserved3 "IICBVC_100ms_Group78_Reserved3";
BA_ "SysSignalName" SG_ 901 IICBVC_100ms_Group78_Reserved3 "ICBVC_100ms_Group78_Reserved3";
BA_ "CompuMethodName" SG_ 901 IICBVC_100ms_Group78_Reserved4 "ICBVC_100ms_Group78_Reserved4";
BA_ "GenSigStartValue" SG_ 901 IICBVC_100ms_Group78_Reserved4 63;
BA_ "ISignalName" SG_ 901 IICBVC_100ms_Group78_Reserved4 "IICBVC_100ms_Group78_Reserved4";
BA_ "SysSignalName" SG_ 901 IICBVC_100ms_Group78_Reserved4 "ICBVC_100ms_Group78_Reserved4";
BA_ "CompuMethodName" SG_ 901 IICMErSts "ICMErSts";
BA_ "ISignalName" SG_ 901 IICMErSts "IICMErSts";
BA_ "LongName" SG_ 901 IICMErSts "Intelligent Cockpit Module Error Status";
BA_ "SysSignalName" SG_ 901 IICMErSts "ICMErSts";
BA_ "CompuMethodName" SG_ 901 IICBVC_100ms_Group78_Reserved5 "ICBVC_100ms_Group78_Reserved5";
BA_ "GenSigStartValue" SG_ 901 IICBVC_100ms_Group78_Reserved5 255;
BA_ "ISignalName" SG_ 901 IICBVC_100ms_Group78_Reserved5 "IICBVC_100ms_Group78_Reserved5";
BA_ "SysSignalName" SG_ 901 IICBVC_100ms_Group78_Reserved5 "ICBVC_100ms_Group78_Reserved5";
BA_ "CompuMethodName" SG_ 901 IICBVC_100ms_Group78_Reserved6 "ICBVC_100ms_Group78_Reserved6";
BA_ "GenSigStartValue" SG_ 901 IICBVC_100ms_Group78_Reserved6 255;
BA_ "ISignalName" SG_ 901 IICBVC_100ms_Group78_Reserved6 "IICBVC_100ms_Group78_Reserved6";
BA_ "SysSignalName" SG_ 901 IICBVC_100ms_Group78_Reserved6 "ICBVC_100ms_Group78_Reserved6";
BA_ "CompuMethodName" SG_ 901 IICBVC_100ms_Group78_Reserved7 "ICBVC_100ms_Group78_Reserved7";
BA_ "GenSigStartValue" SG_ 901 IICBVC_100ms_Group78_Reserved7 255;
BA_ "ISignalName" SG_ 901 IICBVC_100ms_Group78_Reserved7 "IICBVC_100ms_Group78_Reserved7";
BA_ "SysSignalName" SG_ 901 IICBVC_100ms_Group78_Reserved7 "ICBVC_100ms_Group78_Reserved7";
BA_ "CompuMethodName" SG_ 292 ISCREEN_COORD_AX "SCREEN_COORD_AX";
BA_ "ISignalName" SG_ 292 ISCREEN_COORD_AX "ISCREEN_COORD_AX";
BA_ "LongName" SG_ 292 ISCREEN_COORD_AX "SCREEN_COORD_AX";
BA_ "SysSignalName" SG_ 292 ISCREEN_COORD_AX "SCREEN_COORD_AX";
BA_ "CompuMethodName" SG_ 292 ITOUCH_SCREEN_ACMD "TOUCH_SCREEN_ACMD";
BA_ "ISignalName" SG_ 292 ITOUCH_SCREEN_ACMD "ITOUCH_SCREEN_ACMD";
BA_ "LongName" SG_ 292 ITOUCH_SCREEN_ACMD "TOUCH_SCREEN_ACMD";
BA_ "SysSignalName" SG_ 292 ITOUCH_SCREEN_ACMD "TOUCH_SCREEN_ACMD";
BA_ "CompuMethodName" SG_ 292 ISCREEN_COORD_AY "SCREEN_COORD_AY";
BA_ "ISignalName" SG_ 292 ISCREEN_COORD_AY "ISCREEN_COORD_AY";
BA_ "LongName" SG_ 292 ISCREEN_COORD_AY "SCREEN_COORD_AY";
BA_ "SysSignalName" SG_ 292 ISCREEN_COORD_AY "SCREEN_COORD_AY";
BA_ "CompuMethodName" SG_ 292 ITOUCH_SCREEN_BCMD "TOUCH_SCREEN_BCMD";
BA_ "ISignalName" SG_ 292 ITOUCH_SCREEN_BCMD "ITOUCH_SCREEN_BCMD";
BA_ "LongName" SG_ 292 ITOUCH_SCREEN_BCMD "TOUCH_SCREEN_BCMD";
BA_ "SysSignalName" SG_ 292 ITOUCH_SCREEN_BCMD "TOUCH_SCREEN_BCMD";
BA_ "CompuMethodName" SG_ 292 ISCREEN_COORD_BX "SCREEN_COORD_BX";
BA_ "ISignalName" SG_ 292 ISCREEN_COORD_BX "ISCREEN_COORD_BX";
BA_ "LongName" SG_ 292 ISCREEN_COORD_BX "SCREEN_COORD_BX";
BA_ "SysSignalName" SG_ 292 ISCREEN_COORD_BX "SCREEN_COORD_BX";
BA_ "CompuMethodName" SG_ 292 ITOUCH_SCREEN_STATUS "TOUCH_SCREEN_STATUS";
BA_ "ISignalName" SG_ 292 ITOUCH_SCREEN_STATUS "ITOUCH_SCREEN_STATUS";
BA_ "LongName" SG_ 292 ITOUCH_SCREEN_STATUS "Two_Points_Touched_States";
BA_ "SysSignalName" SG_ 292 ITOUCH_SCREEN_STATUS "TOUCH_SCREEN_STATUS";
BA_ "CompuMethodName" SG_ 292 ISCREEN_COORD_BY "SCREEN_COORD_BY";
BA_ "ISignalName" SG_ 292 ISCREEN_COORD_BY "ISCREEN_COORD_BY";
BA_ "LongName" SG_ 292 ISCREEN_COORD_BY "SCREEN_COORD_BY";
BA_ "SysSignalName" SG_ 292 ISCREEN_COORD_BY "SCREEN_COORD_BY";
BA_ "CompuMethodName" SG_ 292 IDMSAvlbly "DMSAvlbly";
BA_ "GenSigStartValue" SG_ 292 IDMSAvlbly 1;
BA_ "ISignalName" SG_ 292 IDMSAvlbly "IDMSAvlbly";
BA_ "LongName" SG_ 292 IDMSAvlbly "DMS Availability";
BA_ "SysSignalName" SG_ 292 IDMSAvlbly "DMSAvlbly";
BA_ "CompuMethodName" SG_ 482 IICBVC_50ms_Group11_CRC "ICBVC_50ms_Group11_CRC";
BA_ "ISignalName" SG_ 482 IICBVC_50ms_Group11_CRC "IICBVC_50ms_Group11_CRC";
BA_ "SysSignalName" SG_ 482 IICBVC_50ms_Group11_CRC "ICBVC_50ms_Group11_CRC";
BA_ "CompuMethodName" SG_ 482 IICBVC_50ms_Group11_RC "ICBVC_50ms_Group11_RC";
BA_ "ISignalName" SG_ 482 IICBVC_50ms_Group11_RC "IICBVC_50ms_Group11_RC";
BA_ "SysSignalName" SG_ 482 IICBVC_50ms_Group11_RC "ICBVC_50ms_Group11_RC";
BA_ "CompuMethodName" SG_ 482 IICBVC_50ms_Group11_Reserved1 "ICBVC_50ms_Group11_Reserved1";
BA_ "GenSigStartValue" SG_ 482 IICBVC_50ms_Group11_Reserved1 15;
BA_ "ISignalName" SG_ 482 IICBVC_50ms_Group11_Reserved1 "IICBVC_50ms_Group11_Reserved1";
BA_ "SysSignalName" SG_ 482 IICBVC_50ms_Group11_Reserved1 "ICBVC_50ms_Group11_Reserved1";
BA_ "CompuMethodName" SG_ 482 IICBVC_50ms_Group11_Reserved2 "ICBVC_50ms_Group11_Reserved2";
BA_ "GenSigStartValue" SG_ 482 IICBVC_50ms_Group11_Reserved2 255;
BA_ "ISignalName" SG_ 482 IICBVC_50ms_Group11_Reserved2 "IICBVC_50ms_Group11_Reserved2";
BA_ "SysSignalName" SG_ 482 IICBVC_50ms_Group11_Reserved2 "ICBVC_50ms_Group11_Reserved2";
BA_ "CompuMethodName" SG_ 482 IICBVC_50ms_Group11_Reserved3 "ICBVC_50ms_Group11_Reserved3";
BA_ "GenSigStartValue" SG_ 482 IICBVC_50ms_Group11_Reserved3 255;
BA_ "ISignalName" SG_ 482 IICBVC_50ms_Group11_Reserved3 "IICBVC_50ms_Group11_Reserved3";
BA_ "SysSignalName" SG_ 482 IICBVC_50ms_Group11_Reserved3 "ICBVC_50ms_Group11_Reserved3";
BA_ "CompuMethodName" SG_ 482 IICBVC_50ms_Group11_Reserved4 "ICBVC_50ms_Group11_Reserved4";
BA_ "GenSigStartValue" SG_ 482 IICBVC_50ms_Group11_Reserved4 1;
BA_ "ISignalName" SG_ 482 IICBVC_50ms_Group11_Reserved4 "IICBVC_50ms_Group11_Reserved4";
BA_ "SysSignalName" SG_ 482 IICBVC_50ms_Group11_Reserved4 "ICBVC_50ms_Group11_Reserved4";
BA_ "CompuMethodName" SG_ 482 IErrRespStrgWhlSwMdl_L "ErrRespStrgWhlSwMdl_L";
BA_ "ISignalName" SG_ 482 IErrRespStrgWhlSwMdl_L "IErrRespStrgWhlSwMdl_L";
BA_ "LongName" SG_ 482 IErrRespStrgWhlSwMdl_L "Error Response Steering Wheel 
Switch Model_Left";
BA_ "SysSignalName" SG_ 482 IErrRespStrgWhlSwMdl_L "ErrRespStrgWhlSwMdl_L";
BA_ "CompuMethodName" SG_ 482 ICCSwStsDistIncSwA "CCSwStsDistIncSwA";
BA_ "ISignalName" SG_ 482 ICCSwStsDistIncSwA "ICCSwStsDistIncSwA";
BA_ "LongName" SG_ 482 ICCSwStsDistIncSwA "Cruise_Control_Switch_Status_Distance_Increase_Switch_Active";
BA_ "SysSignalName" SG_ 482 ICCSwStsDistIncSwA "CCSwStsDistIncSwA";
BA_ "CompuMethodName" SG_ 482 ICCSwStsDistDecSwA "CCSwStsDistDecSwA";
BA_ "ISignalName" SG_ 482 ICCSwStsDistDecSwA "ICCSwStsDistDecSwA";
BA_ "LongName" SG_ 482 ICCSwStsDistDecSwA "Cruise_Control_Switch_Status_Distance_Decrease_Switch_Active";
BA_ "SysSignalName" SG_ 482 ICCSwStsDistDecSwA "CCSwStsDistDecSwA";
BA_ "CompuMethodName" SG_ 482 ICCSwStsSpdIncSwA "CCSwStsSpdIncSwA";
BA_ "ISignalName" SG_ 482 ICCSwStsSpdIncSwA "ICCSwStsSpdIncSwA";
BA_ "LongName" SG_ 482 ICCSwStsSpdIncSwA "Cruise_Control_Switch_Status_Speed_Increase_Switch_Active";
BA_ "SysSignalName" SG_ 482 ICCSwStsSpdIncSwA "CCSwStsSpdIncSwA";
BA_ "CompuMethodName" SG_ 482 ICCSwStsSpdDecSwA "CCSwStsSpdDecSwA";
BA_ "ISignalName" SG_ 482 ICCSwStsSpdDecSwA "ICCSwStsSpdDecSwA";
BA_ "LongName" SG_ 482 ICCSwStsSpdDecSwA "Cruise_Control_Switch_Status_Speed_Decrease_Switch_Active";
BA_ "SysSignalName" SG_ 482 ICCSwStsSpdDecSwA "CCSwStsSpdDecSwA";
BA_ "CompuMethodName" SG_ 482 ICCSwStsSwDataIntgty "CCSwStsSwDataIntgty";
BA_ "ISignalName" SG_ 482 ICCSwStsSwDataIntgty "ICCSwStsSwDataIntgty";
BA_ "LongName" SG_ 482 ICCSwStsSwDataIntgty "Cruise_Control_Switch_Status_Switch_Data_Integrity";
BA_ "SysSignalName" SG_ 482 ICCSwStsSwDataIntgty "CCSwStsSwDataIntgty";
BA_ "CompuMethodName" SG_ 482 IICBVC_50ms_Group11_Reserved5 "ICBVC_50ms_Group11_Reserved5";
BA_ "GenSigStartValue" SG_ 482 IICBVC_50ms_Group11_Reserved5 255;
BA_ "ISignalName" SG_ 482 IICBVC_50ms_Group11_Reserved5 "IICBVC_50ms_Group11_Reserved5";
BA_ "SysSignalName" SG_ 482 IICBVC_50ms_Group11_Reserved5 "ICBVC_50ms_Group11_Reserved5";
BA_ "CompuMethodName" SG_ 482 IICBVC_50ms_Group11_Reserved6 "ICBVC_50ms_Group11_Reserved6";
BA_ "GenSigStartValue" SG_ 482 IICBVC_50ms_Group11_Reserved6 255;
BA_ "ISignalName" SG_ 482 IICBVC_50ms_Group11_Reserved6 "IICBVC_50ms_Group11_Reserved6";
BA_ "SysSignalName" SG_ 482 IICBVC_50ms_Group11_Reserved6 "ICBVC_50ms_Group11_Reserved6";
BA_ "CompuMethodName" SG_ 482 IICBVC_50ms_Group11_Reserved7 "ICBVC_50ms_Group11_Reserved7";
BA_ "GenSigStartValue" SG_ 482 IICBVC_50ms_Group11_Reserved7 255;
BA_ "ISignalName" SG_ 482 IICBVC_50ms_Group11_Reserved7 "IICBVC_50ms_Group11_Reserved7";
BA_ "SysSignalName" SG_ 482 IICBVC_50ms_Group11_Reserved7 "ICBVC_50ms_Group11_Reserved7";
VAL_ 859 ISpdLmtMdResp 0 "SpdLmtMdResp_0_AIPilotSwReq_0_Unavailable" 1 "SpdLmtMdResp_1_Off" 2 "SpdLmtMdResp_2_SLIF" 3 "SpdLmtMdResp_3_ISA";
VAL_ 859 IAutoMainBeamLghtReq 0 "AutoMainBeamLghtReq_0_NoRequest" 1 "AutoMainBeamLghtReq_1_RequestOnFromCamera" 2 "AutoMainBeamLghtReq_2_RequestOffFromCamera" 3 "AutoMainBeamLghtReq_3_CannotDetectedTheEnvironment";
VAL_ 895 INarwSpcAstSwSts 0 "NarwSpcAstSwSts_0_Narwspcastswsts_0_Unavailable" 1 "NarwSpcAstSwSts_1_ON" 2 "NarwSpcAstSwSts_2_OFF";
VAL_ 895 INarwSpcAstBtnSts 0 "NarwSpcAstBtnSts_0_Off" 1 "NarwSpcAstBtnSts_1_OnlyForwardAvailable" 2 "NarwSpcAstBtnSts_2_OnlyBackwardAvailable" 3 "NarwSpcAstBtnSts_3_ForwardAndBackwardAvailable" 4 "NarwSpcAstBtnSts_4_Unavailable";
VAL_ 895 IIPD_VehLckCtrlReq 0 "VehLckCtrlReq_0_No_Request" 1 "VehLckCtrlReq_1_Interior_Unlock_Request" 2 "VehLckCtrlReq_2_Exterior_Unlock_Request" 3 "VehLckCtrlReq_3_Interior_Lock_Request" 4 "VehLckCtrlReq_4_Exterior_Lock_Request";
VAL_ 895 IRembParkngInPrmt 0 "RembParkngInPrmt_0_False" 1 "RembParkngInPrmt_1_True";
VAL_ 895 IRembParkngInMapngResp 0 "RembParkngInMapngResp_0_False" 1 "RembParkngInMapngResp_1_True";
VAL_ 895 IRembParkngInPrmtSwSts 0 "RembParkngInPrmtSwSts_0_Rembparknginprmtswsts_0_Unavailable" 1 "RembParkngInPrmtSwSts_1_ON" 2 "RembParkngInPrmtSwSts_2_OFF";
VAL_ 895 IRembParkngInMapngIndcr 0 "RembParkngInMapngIndcr_0_NoRequest" 1 "RembParkngInMapngIndcr_1_ParkingInMappingFailed" 2 "RembParkngInMapngIndcr_2_ParkingInManualRequest" 3 "RembParkngInMapngIndcr_3_ParkingOutRequest" 4 "RembParkngInMapngIndcr_4_ParkingOutMappingSucceed" 5 "RembParkngInMapngIndcr_5_RememberParkingFinished" 6 "RembParkngInMapngIndcr_6_MapIsBeingGenerated" 7 "RembParkngInMapngIndcr_7_ContinueScanningRequest";
VAL_ 895 IRembParkngInMapRutSeln 0 "RembParkngInMapRutSeln_0_NoRequest" 1 "RembParkngInMapRutSeln_1_Remember_Park_In" 2 "RembParkngInMapRutSeln_2_Remember_Park_Out" 3 "RembParkngInMapRutSeln_3_Reseverd" 4 "RembParkngInMapRutSeln_4_Reseverd" 5 "RembParkngInMapRutSeln_5_Reseverd" 6 "RembParkngInMapRutSeln_6_Reseverd" 7 "RembParkngInMapRutSeln_7_Reseverd";
VAL_ 895 IIPDMCUTemp 255 "IPDAurixTemp_255_Invalid_Value";
VAL_ 895 IIPDWtrClntInltReqFlg 0 "IPDWtrClntInltReqFlg_0_Request" 1 "IPDWtrClntInltReqFlg_1_No_Request";
VAL_ 895 ITrfGreenLghtActn 0 "TrfGreenLghtActn_0_NoDisplay" 1 "TrfGreenLghtActn_1_GreenLight_warning";
VAL_ 895 IRembParkngInMapngRutID 0 "RembParkngInMapngRutID_0_No_request" 1 "RembParkngInMapngRutID_1_First_map_for_Parking_In" 2 "RembParkngInMapngRutID_2_Second_map_for_Parking_In" 3 "RembParkngInMapngRutID_3_Third_map_for_Parking_In" 4 "RembParkngInMapngRutID_4_4th_map_for_Parking_In" 5 "RembParkngInMapngRutID_5_5th_map_for_Parking_In" 6 "RembParkngInMapngRutID_6_6th_map_for_Parking_In" 7 "RembParkngInMapngRutID_7_7th_map_for_Parking_In" 8 "RembParkngInMapngRutID_8_8th_map_for_Parking_In" 9 "RembParkngInMapngRutID_9_9th_map_for_Parking_In" 10 "RembParkngInMapngRutID_10_10th_map_for_Parking_In" 11 "RembParkngInMapngRutID_11_First_map_for_Parking_Out" 12 "RembParkngInMapngRutID_12_Second_map_for_Parking_Out" 13 "RembParkngInMapngRutID_13_Third_map_for_Parking_Out" 14 "RembParkngInMapngRutID_14_4th_map_for_Parking_Out" 15 "RembParkngInMapngRutID_15_5th_map_for_Parking_Out" 16 "RembParkngInMapngRutID_16_6th_map_for_Parking_Out" 17 "RembParkngInMapngRutID_17_7th_map_for_Parking_Out" 18 "RembParkngInMapngRutID_18_8th_map_for_Parking_Out" 19 "RembParkngInMapngRutID_19_9th_map_for_Parking_Out" 20 "RembParkngInMapngRutID_20_10th_map_for_Parking_Out";
VAL_ 895 IRembParkngInMapRutDltSeln 0 "RembParkngInMapRutDltSeln_0_NoRequest" 1 "RembParkngInMapRutDltSeln_1_MapRouteOne" 2 "RembParkngInMapRutDltSeln_2_MapRouteTwo" 3 "RembParkngInMapRutDltSeln_3_MapRouteThree" 4 "RembParkngInMapRutDltSeln_4_MapRouteFour" 5 "RembParkngInMapRutDltSeln_5_MapRouteFive" 6 "RembParkngInMapRutDltSeln_6_MapRouteSix" 7 "RembParkngInMapRutDltSeln_7_MapRouteSeven" 8 "RembParkngInMapRutDltSeln_8_MapRouteEight" 9 "RembParkngInMapRutDltSeln_9_MapRouteNine" 10 "RembParkngInMapRutDltSeln_10_MapRouteTen" 11 "RembParkngInMapRutDltSeln_11_MapRouteEleven" 12 "RembParkngInMapRutDltSeln_12_MapRouteTwelve" 13 "RembParkngInMapRutDltSeln_13_MapRouteThirteen" 14 "RembParkngInMapRutDltSeln_14_MapRouteFourteen" 15 "RembParkngInMapRutDltSeln_15_MapRouteFifteen";
VAL_ 820 IHzrdLampsCtrl 0 "HzrdLampsCtrl_0_No_Request" 1 "HzrdLampsCtrl_1_ON" 2 "HzrdLampsCtrl_2_OFF" 3 "HzrdLampsCtrl_3_Reserved";
VAL_ 820 IDILampsCtrl 0 "DILampsCtrl_0_No_Request" 1 "DILampsCtrl_1_Left_ON" 2 "DILampsCtrl_2_Right_ON" 3 "DILampsCtrl_3_OFF";
VAL_ 820 IAutoLaneChngSetResp 0 "AutoLaneChngSetResp_0_unavailable" 1 "AutoLaneChngSetResp_1_Level1" 2 "AutoLaneChngSetResp_2_Level2" 3 "AutoLaneChngSetResp_3_Level3";
VAL_ 820 IAutoLaneChngSwDspCmd 0 "AutoLaneChngSwDspCmd_0_unavailable" 1 "AutoLaneChngSwDspCmd_1_off" 2 "AutoLaneChngSwDspCmd_2_LaneChangeSuggestion" 3 "AutoLaneChngSwDspCmd_3_AlcWithDriver" 4 "AutoLaneChngSwDspCmd_4_AlcWithoutDriver_reserved" 5 "AutoLaneChngSwDspCmd_5_Reserved" 6 "AutoLaneChngSwDspCmd_6_Reserved" 7 "AutoLaneChngSwDspCmd_7_Reserved";
VAL_ 820 IAutoLaneChngMsgReq 0 "AutoLaneChngMsgReq_0_NoDisplay" 1 "AutoLaneChngMsgReq_1_LaneChangeInhibit" 2 "AutoLaneChngMsgReq_2_WaitingForLaneChangeStarting" 3 "AutoLaneChngMsgReq_3_LaneChangeInProgress" 4 "AutoLaneChngMsgReq_4_LaneChangeSucces" 5 "AutoLaneChngMsgReq_5_LaneChangeFailed" 6 "AutoLaneChngMsgReq_6_LaneChangeSuppressByDriver" 7 "AutoLaneChngMsgReq_7_ReturnToEgoLaneByDriver" 8 "AutoLaneChngMsgReq_8_ReturnToEgoLaneByALC" 9 "AutoLaneChngMsgReq_9_LaneChange_ManoeuvreWithRisk" 16 "AutoLaneChngMsgReq_16_ReturnToEgoLaneSuccess" 17 "AutoLaneChngMsgReq_17_TOR" 18 "AutoLaneChngMsgReq_18_LowSpeed";
VAL_ 820 IOtsdMirFoldReq 0 "OtsdMirFoldReq_0_No_Request" 1 "OtsdMirFoldReq_1_Fold_Request" 2 "OtsdMirFoldReq_2_Unfold_Request";
VAL_ 1105 IELKSysSts 0 "ELKSysSts_0_ELKOFF" 1 "ELKSysSts_1_StandBy" 2 "ELKSysSts_2_Active" 3 "ELKSysSts_3_Override" 4 "ELKSysSts_4_service_required" 5 "ELKSysSts_5_system_temporary_unavailable" 6 "ELKSysSts_6_Reserved" 7 "ELKSysSts_7_Reserved";
VAL_ 1105 IELKSysFltSts 0 "ELKSysFltSts_0_IELKSysFltSts_no_error" 1 "ELKSysFltSts_1_performance_degradation" 2 "ELKSysFltSts_2_system_temporary_unavailable" 3 "ELKSysFltSts_3_service_required" 4 "ELKSysFltSts_4_Reserved" 5 "ELKSysFltSts_5_Reserved" 6 "ELKSysFltSts_6_Reserved";
VAL_ 1105 IAIParkngSpdswSts 0 "AIParkngSpdswSts_0_Low_speed" 1 "AIParkngSpdswSts_1_Normal_speed" 2 "AIParkngSpdswSts_2_High_speed" 3 "AIParkngSpdswSts_3_Reserve";
VAL_ 1105 INrwroadFwdSta 0 "NrwroadFwdSta_0_No_request" 1 "NrwroadFwdSta_1_ON" 2 "NrwroadFwdSta_2_OFF" 3 "NrwroadFwdSta_3_Unavailable";
VAL_ 1105 INrwroadsltSta 0 "NrwroadsltSta_0_No_request" 1 "NrwroadsltSta_1_ON" 2 "NrwroadsltSta_2_OFF" 3 "NrwroadsltSta_3_Unavailable";
VAL_ 1105 IIPDELKDspCmd 0 "IPDELKDspCmd_0_unavailable" 1 "IPDELKDspCmd_1_off" 2 "IPDELKDspCmd_2_on" 3 "IPDELKDspCmd_3_Reserved";
VAL_ 1105 IMemParkngStrtBtnSts 0 "MemParkngStrtBtnSts_0_Off" 1 "MemParkngStrtBtnSts_1_Active" 2 "MemParkngStrtBtnSts_2_Passive" 3 "MemParkngStrtBtnSts_3_Reserve";
VAL_ 1105 IMemParkngBtnRcnm 0 "MemParkngBtnRcnm_0_noRecommended" 1 "MemParkngBtnRcnm_1_Recommended" 2 "MemParkngBtnRcnm_2_Reserve1" 3 "MemParkngBtnRcnm_3_Reserve2";
VAL_ 1105 IMemParkngBtnSts 0 "MemParkngBtnSts_0_noRecommended" 1 "MemParkngBtnSts_1_Recommended" 2 "MemParkngBtnSts_2_Reserve1" 3 "MemParkngBtnSts_3_Reserve2";
VAL_ 1106 INarrowRoadForwardSts 0 "NarrowRoadForwardSts_0_off" 1 "NarrowRoadForwardSts_1_enable" 2 "NarrowRoadForwardSts_2_Unavailable" 3 "NarrowRoadForwardSts_3_The_conditions_are_not_met" 4 "NarrowRoadForwardSts_4_Rready" 5 "NarrowRoadForwardSts_5_Moving_forward" 6 "NarrowRoadForwardSts_6_Moving_forward_Is_Over" 7 "NarrowRoadForwardSts_7_Interruption";
VAL_ 1106 INarrowRoadBackwardSts 0 "NarrowRoadBackwardSts_0_off" 1 "NarrowRoadBackwardSts_1_enable" 2 "NarrowRoadBackwardSts_2_Unavailable" 3 "NarrowRoadBackwardSts_3_The_conditions_are_not_met" 4 "NarrowRoadBackwardSts_4_Rready" 5 "NarrowRoadBackwardSts_5_Moving_backward" 6 "NarrowRoadBackwardSts_6_Moving_backward_Is_Over" 7 "NarrowRoadBackwardSts_7_Interruption";
VAL_ 1106 ITrfcLghtStSp 0 "TrfcLghtStSp_0_off" 1 "TrfcLghtStSp_1_enable" 2 "TrfcLghtStSp_2_Unavailable" 3 "TrfcLghtStSp_3_override" 4 "TrfcLghtStSp_4_Yellow_light_ahead_automatic_deceleration_in_progress" 5 "TrfcLghtStSp_5_Red_light_ahead_automatic_parking_in_progress" 6 "TrfcLghtStSp_6_Red_light_ahead_stopped" 7 "TrfcLghtStSp_7_Green_light_ahead_automatic_go_off" 8 "TrfcLghtStSp_8_Green_light_ahead_automatic_start_successful";
VAL_ 151 IAIParkngEPAMdsts 0 "AIParkngEPAMdsts_0_Lockmode" 1 "AIParkngEPAMdsts_1_Simplemode";
VAL_ 151 ID2DSwReqResps 0 "D2DSwReqResps_0_unavailable" 1 "D2DSwReqResps_1_off" 2 "D2DSwReqResps_2_on" 3 "D2DSwReqResps_3_reserved";
VAL_ 151 IFCTBSysFltSts 0 "FCTBSysFltSts_0_No_Error" 1 "FCTBSysFltSts_1_System_Temporary_Unvailable" 2 "FCTBSysFltSts_2_Service_Required" 3 "FCTBSysFltSts_3_Service_Required";
VAL_ 151 ID2DPriETClanSwReqResps 0 "D2DPriETClanSwReqResps_0_unavailable" 1 "D2DPriETClanSwReqResps_1_off" 2 "D2DPriETClanSwReqResps_2_on" 3 "D2DPriETClanSwReqResps_3_reserved";
VAL_ 382 IACCSdslReq 0 "ACCSdslReq_0_No_Request" 1 "ACCSdslReq_1_Request";
VAL_ 382 IACCGoReq 0 "ACCGoReq_0_NoRequest" 1 "ACCGoReq_1_Request";
VAL_ 382 IACCAccReqSts_CH 0 "ACCAccReqSts_CH_0_No_Request" 1 "ACCAccReqSts_CH_1_ACC_Acceleration_Request";
VAL_ 382 IACCSysFltSts 0 "ACCSysFltSts_0_NoError" 1 "ACCSysFltSts_1_PerformanceDegradation" 2 "ACCSysFltSts_2_SystemTemporaryUnvailable" 3 "ACCSysFltSts_3_ServiceRequired" 4 "ACCSysFltSts_4_Reserved" 5 "ACCSysFltSts_5_Reserved" 6 "ACCSysFltSts_6_Reserved" 7 "ACCSysFltSts_7_Reserved";
VAL_ 382 IACCSysSts 0 "ACCSysSts_0_Off" 1 "ACCSysSts_1_StandBy" 2 "ACCSysSts_2_Active" 3 "ACCSysSts_3_Override" 4 "ACCSysSts_4_BrakeOnly" 5 "ACCSysSts_5_StandstillActive" 6 "ACCSysSts_6_StandstillWait" 7 "ACCSysSts_7_Reserved";
VAL_ 385 INSAReqAVMDis 0 "NSAReqAVMDis_0_NoRequest" 1 "NSAReqAVMDis_1_Request";
VAL_ 385 INSADisFucSts 0 "NSADisFucSts_0_Off" 1 "NSADisFucSts_1_Standby" 2 "NSADisFucSts_2_Active" 3 "NSADisFucSts_3_Fault";
VAL_ 385 INSABacSysSts 0 "NSABacSysSts_0_Off" 1 "NSABacSysSts_1_Standby" 2 "NSABacSysSts_2_BackwardActive" 3 "NSABacSysSts_3_Quit" 4 "NSABacSysSts_4_Error";
VAL_ 385 INSAForSysSts 0 "NSAForSysSts_0_Off" 1 "NSAForSysSts_1_Standby" 2 "NSAForSysSts_2_ForwardActive" 3 "NSAForSysSts_3_Quit" 4 "NSAForSysSts_4_Error" 5 "NSAForSysSts_5_Pause" 6 "NSAForSysSts_6_Reserve" 7 "NSAForSysSts_7_Reserve";
VAL_ 385 IILDP_ELKWrnng 0 "ILDP_ELKWrnng_0_Not_Active" 1 "ILDP_ELKWrnng_1_Take_Over_Warning" 2 "ILDP_ELKWrnng_2_Take_Over_Safety" 3 "ILDP_ELKWrnng_3_Suppressed" 4 "ILDP_ELKWrnng_4_Reserved" 5 "ILDP_ELKWrnng_5_Reserved" 6 "ILDP_ELKWrnng_6__Reserved" 7 "ILDP_ELKWrnng_7__Reserved";
VAL_ 736 IFrtMidRObsRng 0 "FrtMidRObsRng_0_NoObstacle" 1 "FrtMidRObsRng_1_Range1" 2 "FrtMidRObsRng_2_Range2" 3 "FrtMidRObsRng_3_Range3" 4 "FrtMidRObsRng_4_Range4" 5 "FrtMidRObsRng_5_Range5" 6 "FrtMidRObsRng_6_Range6" 7 "FrtMidRObsRng_7_Range7" 8 "FrtMidRObsRng_8_Range8" 9 "FrtMidRObsRng_9_Range9" 10 "FrtMidRObsRng_10_Range10" 11 "FrtMidRObsRng_11_Range11" 12 "FrtMidRObsRng_12_Range12" 13 "FrtMidRObsRng_13_Range13" 14 "FrtMidRObsRng_14_Range14" 15 "FrtMidRObsRng_15_Range15";
VAL_ 736 IFrtPDCAudWrnng 0 "FrtPDCAudWrnng_0_No_Obstacle" 1 "FrtPDCAudWrnng_1_Range_1" 2 "FrtPDCAudWrnng_2_Range_2" 3 "FrtPDCAudWrnng_3_Range_3" 4 "FrtPDCAudWrnng_4_Range_4" 5 "FrtPDCAudWrnng_5_Range_5" 6 "FrtPDCAudWrnng_6_Range_6" 7 "FrtPDCAudWrnng_7_Range_7" 8 "FrtPDCAudWrnng_8_Range_8" 9 "FrtPDCAudWrnng_9_Range_9" 10 "FrtPDCAudWrnng_10_Range_10" 11 "FrtPDCAudWrnng_11_Range_11" 12 "FrtPDCAudWrnng_12_Range_12" 13 "FrtPDCAudWrnng_13_Range_13" 14 "FrtPDCAudWrnng_14_Range_14" 15 "FrtPDCAudWrnng_15_Range_15";
VAL_ 736 IRrMidLObsRng 0 "RrMidLObsRng_0_NoObstacle" 1 "RrMidLObsRng_1_Range1" 2 "RrMidLObsRng_2_Range2" 3 "RrMidLObsRng_3_Range3" 4 "RrMidLObsRng_4_Range4" 5 "RrMidLObsRng_5_Range5" 6 "RrMidLObsRng_6_Range6" 7 "RrMidLObsRng_7_Range7" 8 "RrMidLObsRng_8_Range8" 9 "RrMidLObsRng_9_Range9" 10 "RrMidLObsRng_10_Range10" 11 "RrMidLObsRng_11_Range11" 12 "RrMidLObsRng_12_Range12" 13 "RrMidLObsRng_13_Range13" 14 "RrMidLObsRng_14_Range14" 15 "RrMidLObsRng_15_Range15";
VAL_ 736 IRLObsRng 0 "RLObsRng_0_NoObstacle" 1 "RLObsRng_1_Range1" 2 "RLObsRng_2_Range2" 3 "RLObsRng_3_Range3" 4 "RLObsRng_4_Range4" 5 "RLObsRng_5_Range5" 6 "RLObsRng_6_Range6" 7 "RLObsRng_7_Range7" 8 "RLObsRng_8_Range8" 9 "RLObsRng_9_Range9" 10 "RLObsRng_10_Range10" 11 "RLObsRng_11_Range11" 12 "RLObsRng_12_Range12" 13 "RLObsRng_13_Range13" 14 "RLObsRng_14_Range14" 15 "RLObsRng_15_Range15";
VAL_ 736 IRrMidRObsRng 0 "RrMidRObsRng_0_NoObstacle" 1 "RrMidRObsRng_1_Range1" 2 "RrMidRObsRng_2_Range2" 3 "RrMidRObsRng_3_Range3" 4 "RrMidRObsRng_4_Range4" 5 "RrMidRObsRng_5_Range5" 6 "RrMidRObsRng_6_Range6" 7 "RrMidRObsRng_7_Range7" 8 "RrMidRObsRng_8_Range8" 9 "RrMidRObsRng_9_Range9" 10 "RrMidRObsRng_10_Range10" 11 "RrMidRObsRng_11_Range11" 12 "RrMidRObsRng_12_Range12" 13 "RrMidRObsRng_13_Range13" 14 "RrMidRObsRng_14_Range14" 15 "RrMidRObsRng_15_Range15";
VAL_ 736 IPDCSysSts 0 "PDCSysSts_0_System_OK" 1 "PDCSysSts_1_System_initialization_sucessful" 2 "PDCSysSts_2_System_Failed" 3 "PDCSysSts_3_System_Disabled" 4 "PDCSysSts_4_Front_PDC_Disabled" 5 "PDCSysSts_5_Front_PDC_Failed" 6 "PDCSysSts_6_Rear_PDC_Failed" 7 "PDCSysSts_7_Rear_PDC_Disabled";
VAL_ 736 IFLSideObsRng 0 "FLSideObsRng_0_NoObstacle" 1 "FLSideObsRng_1_Range1" 2 "FLSideObsRng_2_Range2" 3 "FLSideObsRng_3_Range3" 4 "FLSideObsRng_4_Range4" 5 "FLSideObsRng_5_Range5" 6 "FLSideObsRng_6_Range6" 7 "FLSideObsRng_7_Range7" 8 "FLSideObsRng_8_Range8" 9 "FLSideObsRng_9_Range9" 10 "FLSideObsRng_10_Range10" 11 "FLSideObsRng_11_Range11" 12 "FLSideObsRng_12_Range12" 13 "FLSideObsRng_13_Range13" 14 "FLSideObsRng_14_Range14" 15 "FLSideObsRng_15_Range15";
VAL_ 736 IRrPDCAudWrnng 0 "RrPDCAudWrnng_0_No_Obstacle" 1 "RrPDCAudWrnng_1_Range_1" 2 "RrPDCAudWrnng_2_Range_2" 3 "RrPDCAudWrnng_3_Range_3" 4 "RrPDCAudWrnng_4_Range_4" 5 "RrPDCAudWrnng_5_Range_5" 6 "RrPDCAudWrnng_6_Range_6" 7 "RrPDCAudWrnng_7_Range_7" 8 "RrPDCAudWrnng_8_Range_8" 9 "RrPDCAudWrnng_9_Range_9" 10 "RrPDCAudWrnng_10_Range_10" 11 "RrPDCAudWrnng_11_Range_11" 12 "RrPDCAudWrnng_12_Range_12" 13 "RrPDCAudWrnng_13_Range_13" 14 "RrPDCAudWrnng_14_Range_14" 15 "RrPDCAudWrnng_15_Range_15";
VAL_ 736 IRLSideObsRng 0 "RLSideObsRng_0_NoObstacle" 1 "RLSideObsRng_1_Range1" 2 "RLSideObsRng_2_Range2" 3 "RLSideObsRng_3_Range3" 4 "RLSideObsRng_4_Range4" 5 "RLSideObsRng_5_Range5" 6 "RLSideObsRng_6_Range6" 7 "RLSideObsRng_7_Range7" 8 "RLSideObsRng_8_Range8" 9 "RLSideObsRng_9_Range9" 10 "RLSideObsRng_10_Range10" 11 "RLSideObsRng_11_Range11" 12 "RLSideObsRng_12_Range12" 13 "RLSideObsRng_13_Range13" 14 "RLSideObsRng_14_Range14" 15 "RLSideObsRng_15_Range15";
VAL_ 736 IFRSideObsRng 0 "FRSideObsRng_0_NoObstacle" 1 "FRSideObsRng_1_Range1" 2 "FRSideObsRng_2_Range2" 3 "FRSideObsRng_3_Range3" 4 "FRSideObsRng_4_Range4" 5 "FRSideObsRng_5_Range5" 6 "FRSideObsRng_6_Range6" 7 "FRSideObsRng_7_Range7" 8 "FRSideObsRng_8_Range8" 9 "FRSideObsRng_9_Range9" 10 "FRSideObsRng_10_Range10" 11 "FRSideObsRng_11_Range11" 12 "FRSideObsRng_12_Range12" 13 "FRSideObsRng_13_Range13" 14 "FRSideObsRng_14_Range14" 15 "FRSideObsRng_15_Range15";
VAL_ 736 IUndergndParkngGrgSts 0 "UndergndParkngGrgSts_0_Default" 1 "UndergndParkngGrgSts_1_In" 2 "UndergndParkngGrgSts_2_Reserved" 3 "UndergndParkngGrgSts_3_Reserved";
VAL_ 736 IRRSideObsRng 0 "RRSideObsRng_0_NoObstacle" 1 "RRSideObsRng_1_Range1" 2 "RRSideObsRng_2_Range2" 3 "RRSideObsRng_3_Range3" 4 "RRSideObsRng_4_Range4" 5 "RRSideObsRng_5_Range5" 6 "RRSideObsRng_6_Range6" 7 "RRSideObsRng_7_Range7" 8 "RRSideObsRng_8_Range8" 9 "RRSideObsRng_9_Range9" 10 "RRSideObsRng_10_Range10" 11 "RRSideObsRng_11_Range11" 12 "RRSideObsRng_12_Range12" 13 "RRSideObsRng_13_Range13" 14 "RRSideObsRng_14_Range14" 15 "RRSideObsRng_15_Range15";
VAL_ 736 IFLObsRng 0 "FLObsRng_0_NoObstacle" 1 "FLObsRng_1_Range1" 2 "FLObsRng_2_Range2" 3 "FLObsRng_3_Range3" 4 "FLObsRng_4_Range4" 5 "FLObsRng_5_Range5" 6 "FLObsRng_6_Range6" 7 "FLObsRng_7_Range7" 8 "FLObsRng_8_Range8" 9 "FLObsRng_9_Range9" 10 "FLObsRng_10_Range10" 11 "FLObsRng_11_Range11" 12 "FLObsRng_12_Range12" 13 "FLObsRng_13_Range13" 14 "FLObsRng_14_Range14" 15 "FLObsRng_15_Range15";
VAL_ 736 IRRObsRng 0 "RRObsRng_0_NoObstacle" 1 "RRObsRng_1_Range1" 2 "RRObsRng_2_Range2" 3 "RRObsRng_3_Range3" 4 "RRObsRng_4_Range4" 5 "RRObsRng_5_Range5" 6 "RRObsRng_6_Range6" 7 "RRObsRng_7_Range7" 8 "RRObsRng_8_Range8" 9 "RRObsRng_9_Range9" 10 "RRObsRng_10_Range10" 11 "RRObsRng_11_Range11" 12 "RRObsRng_12_Range12" 13 "RRObsRng_13_Range13" 14 "RRObsRng_14_Range14" 15 "RRObsRng_15_Range15";
VAL_ 736 IFRObsRng 0 "FRObsRng_0_NoObstacle" 1 "FRObsRng_1_Range1" 2 "FRObsRng_2_Range2" 3 "FRObsRng_3_Range3" 4 "FRObsRng_4_Range4" 5 "FRObsRng_5_Range5" 6 "FRObsRng_6_Range6" 7 "FRObsRng_7_Range7" 8 "FRObsRng_8_Range8" 9 "FRObsRng_9_Range9" 10 "FRObsRng_10_Range10" 11 "FRObsRng_11_Range11" 12 "FRObsRng_12_Range12" 13 "FRObsRng_13_Range13" 14 "FRObsRng_14_Range14" 15 "FRObsRng_15_Range15";
VAL_ 736 ILADSAFnInd 0 "LADSAFnInd_0_IDLE" 1 "LADSAFnInd_1_RADS" 2 "LADSAFnInd_2_ESSSwap_Park" 3 "LADSAFnInd_3_NPA" 4 "LADSAFnInd_4_AVP" 5 "LADSAFnInd_5_Remember_Build_Map" 6 "LADSAFnInd_6_Remember_Summon" 7 "LADSAFnInd_7_Remember_ParkIn" 8 "LADSAFnInd_8_RemoteOnekeyParkIn_Super" 9 "LADSAFnInd_9_ParkIn_super" 10 "LADSAFnInd_10_ParkIn" 11 "LADSAFnInd_11_ParkOut" 12 "LADSAFnInd_12_NRCD" 13 "LADSAFnInd_13_RemoteOnekeyParkIn" 14 "LADSAFnInd_14_RemoteOnekeyParkOut" 15 "LADSAFnInd_15_NCP";
VAL_ 736 IFrtMidLObsRng 0 "FrtMidLObsRng_0_NoObstacle" 1 "FrtMidLObsRng_1_Range1" 2 "FrtMidLObsRng_2_Range2" 3 "FrtMidLObsRng_3_Range3" 4 "FrtMidLObsRng_4_Range4" 5 "FrtMidLObsRng_5_Range5" 6 "FrtMidLObsRng_6_Range6" 7 "FrtMidLObsRng_7_Range7" 8 "FrtMidLObsRng_8_Range8" 9 "FrtMidLObsRng_9_Range9" 10 "FrtMidLObsRng_10_Range10" 11 "FrtMidLObsRng_11_Range11" 12 "FrtMidLObsRng_12_Range12" 13 "FrtMidLObsRng_13_Range13" 14 "FrtMidLObsRng_14_Range14" 15 "FrtMidLObsRng_15_Range15";
VAL_ 736 IFRSObsRng 0 "FRSObsRng1_0_NoObstacle" 1 "FRSObsRng1_1_Range1" 2 "FRSObsRng1_2_Range2" 3 "FRSObsRng1_3_Range3" 4 "FRSObsRng1_4_Range4" 5 "FRSObsRng1_5_Range5" 6 "FRSObsRng1_6_Range6" 7 "FRSObsRng1_7_Range7" 8 "FRSObsRng1_8_Range8" 9 "FRSObsRng1_9_Range9" 10 "FRSObsRng1_10_Range10" 11 "FRSObsRng1_11_Range11" 12 "FRSObsRng1_12_Range12" 13 "FRSObsRng1_13_Range13" 14 "FRSObsRng1_14_Range14" 15 "FRSObsRng1_15_Range15";
VAL_ 736 IFLSObsRng 0 "FLSObsRng1_0_NoObstacle" 1 "FLSObsRng1_1_Range1" 2 "FLSObsRng1_2_Range2" 3 "FLSObsRng1_3_Range3" 4 "FLSObsRng1_4_Range4" 5 "FLSObsRng1_5_Range5" 6 "FLSObsRng1_6_Range6" 7 "FLSObsRng1_7_Range7" 8 "FLSObsRng1_8_Range8" 9 "FLSObsRng1_9_Range9" 10 "FLSObsRng1_10_Range10" 11 "FLSObsRng1_11_Range11" 12 "FLSObsRng1_12_Range12" 13 "FLSObsRng1_13_Range13" 14 "FLSObsRng1_14_Range14" 15 "FLSObsRng1_15_Range15";
VAL_ 736 IRRSObsRng 0 "RRSObsRng1_0_NoObstacle" 1 "RRSObsRng1_1_Range1" 2 "RRSObsRng1_2_Range2" 3 "RRSObsRng1_3_Range3" 4 "RRSObsRng1_4_Range4" 5 "RRSObsRng1_5_Range5" 6 "RRSObsRng1_6_Range6" 7 "RRSObsRng1_7_Range7" 8 "RRSObsRng1_8_Range8" 9 "RRSObsRng1_9_Range9" 10 "RRSObsRng1_10_Range10" 11 "RRSObsRng1_11_Range11" 12 "RRSObsRng1_12_Range12" 13 "RRSObsRng1_13_Range13" 14 "RRSObsRng1_14_Range14" 15 "RRSObsRng1_15_Range15";
VAL_ 736 IRLSObsRng 0 "RLSObsRng1_0_NoObstacle" 1 "RLSObsRng1_1_Range1" 2 "RLSObsRng1_2_Range2" 3 "RLSObsRng1_3_Range3" 4 "RLSObsRng1_4_Range4" 5 "RLSObsRng1_5_Range5" 6 "RLSObsRng1_6_Range6" 7 "RLSObsRng1_7_Range7" 8 "RLSObsRng1_8_Range8" 9 "RLSObsRng1_9_Range9" 10 "RLSObsRng1_10_Range10" 11 "RLSObsRng1_11_Range11" 12 "RLSObsRng1_12_Range12" 13 "RLSObsRng1_13_Range13" 14 "RLSObsRng1_14_Range14" 15 "RLSObsRng1_15_Range15";
VAL_ 314 ID2DSysSts 0 "D2DSysSts_0_Off" 1 "D2DSysSts_1_Passive" 2 "D2DSysSts_2_Standby" 3 "D2DSysSts_3_active_LPNP" 4 "D2DSysSts_4_active_NP" 5 "D2DSysSts_5_Override" 6 "D2DSysSts_6_TOR" 7 "D2DSysSts_7_Prohibit" 8 "D2DSysSts_8_Fault" 9 "D2DSysSts_9_SafeStop" 10 "D2DSysSts_10_reserved" 11 "D2DSysSts_11_reserved";
VAL_ 50 IIPDTripCntResetResp 0 "IPDTripCntResetResp_0_Failed" 1 "IPDTripCntResetResp_1_Success";
VAL_ 178 IIPDAlgFlag 0 "IPDAlgFlag_0_NationalAlgorism" 1 "IPDAlgFlag_1_InternationalAlgorism";
VAL_ 178 IIPDFailedReason 0 "IPDFailedReason_0_Default" 1 "IPDFailedReason_1_VerifyFailed" 2 "IPDFailedReason_2_WrongFV" 3 "IPDFailedReason_3_WrongBuildMAC";
VAL_ 178 IIPDTripNvmTag 0 "IPDTripNvmTag_0_Success" 1 "IPDTripNvmTag_1_Failed";
VAL_ 178 IIPDKeyStatus 0 "IPDKeyStatus_0_WrittenAndReadSuccess" 1 "IPDKeyStatus_1_NotWrittenOrReadFailed";
VAL_ 81 ITJAICASysFltSts 0 "TJAICASysFltSts_0_noerror" 1 "TJAICASysFltSts_1_performancedegradation" 2 "TJAICASysFltSts_2_systemtemporaryunavailable" 3 "TJAICASysFltSts_3_servicerequired" 4 "TJAICASysFltSts_4_Reserved" 5 "TJAICASysFltSts_5_Reserved" 6 "TJAICASysFltSts_6_Reserved" 7 "TJAICASysFltSts_7_Reserved";
VAL_ 81 ILKASysFltSts 0 "LKASysFltSts_0_noerror" 1 "LKASysFltSts_1_performancedegradation" 2 "LKASysFltSts_2_systemtemporaryunavailable" 3 "LKASysFltSts_3_servicerequired";
VAL_ 81 ITJAICASysSts 0 "TJAICASysSts_0_Off" 1 "TJAICASysSts_1_Standby" 2 "TJAICASysSts_2_Active" 3 "TJAICASysSts_3_Override" 4 "TJAICASysSts_4_Passive" 5 "TJAICASysSts_5_Degradation" 6 "TJAICASysSts_6_SafeStop" 7 "TJAICASysSts_7_Prohibition";
VAL_ 81 ILKASysSts 0 "LKASysSts_0_Off" 1 "LKASysSts_1_Standby" 2 "LKASysSts_2_Active" 3 "LKASysSts_3_Override";
VAL_ 1282 IMnvrngPntTypNav 0 "MnvrngPntTypNav_0_TurnInvalid" 1 "MnvrngPntTypNav_1_TurnFront" 2 "MnvrngPntTypNav_2_TurnLeft" 3 "MnvrngPntTypNav_3_TurnRight" 4 "MnvrngPntTypNav_4_KeepLeft" 5 "MnvrngPntTypNav_5_KeepRight" 6 "MnvrngPntTypNav_6_TurnLeftFront" 7 "MnvrngPntTypNav_7_TurnRightFront" 8 "MnvrngPntTypNav_8_TurnLeftBack" 9 "MnvrngPntTypNav_9_TurnRightBack" 10 "MnvrngPntTypNav_10_TurnLeftUturn" 11 "MnvrngPntTypNav_11_TurnRightUturn" 12 "MnvrngPntTypNav_12_TurnThreebranchLeft" 13 "MnvrngPntTypNav_13_TurnThreebranchCenter" 14 "MnvrngPntTypNav_14_TurnThreebranchRight" 15 "MnvrngPntTypNav_15_TurnExitbranchMainLeft" 16 "MnvrngPntTypNav_16_TurnExitbranchMainRight" 17 "MnvrngPntTypNav_17_TurnExitbranchRampLeft" 18 "MnvrngPntTypNav_18_TurnExitbranchRampRight" 19 "MnvrngPntTypNav_19_GoStraightLeft" 20 "MnvrngPntTypNav_20_GoStraightRight" 21 "MnvrngPntTypNav_21_TurnRing" 22 "MnvrngPntTypNav_22_TurnRingOut" 23 "MnvrngPntTypNav_23_TurnRingOutAnticlockwise135" 24 "MnvrngPntTypNav_24_TurnRingOutAnticlockwise90" 25 "MnvrngPntTypNav_25_TurnRingOutAnticlockwise45" 26 "MnvrngPntTypNav_26_TurnRingOutAnticlockwise0" 27 "MnvrngPntTypNav_27_TurnRingOutAnticlockwise225" 28 "MnvrngPntTypNav_28_TurnRingOutAnticlockwise270" 29 "MnvrngPntTypNav_29_TurnRingOutAnticlockwise135" 30 "MnvrngPntTypNav_30_TurnRingOutAnticlockwise360" 31 "MnvrngPntTypNav_31_TurnRingOutClockwise225" 32 "MnvrngPntTypNav_32_TurnRingOutClockwise270" 33 "MnvrngPntTypNav_33_TurnRingOutClockwise315" 34 "MnvrngPntTypNav_34_TurnRingOutClockwise360" 35 "MnvrngPntTypNav_35_TurnRingOutClockwise45" 36 "MnvrngPntTypNav_36_TurnRingOutClockwise90" 37 "MnvrngPntTypNav_37_TurnRingOutClockwise135" 38 "MnvrngPntTypNav_38_TurnRingOutClockwise180" 39 "MnvrngPntTypNav_39_DirectRouteDrive" 40 "MnvrngPntTypNav_40_TollStation" 41 "MnvrngPntTypNav_41_Ferry" 42 "MnvrngPntTypNav_42_TunnelEntrance" 43 "MnvrngPntTypNav_43_BridgeEntrance" 44 "MnvrngPntTypNav_44_StartingPoint" 45 "MnvrngPntTypNav_45_PassedPoint1" 46 "MnvrngPntTypNav_46_PassedPoint2" 47 "MnvrngPntTypNav_47_PassedPoint3" 48 "MnvrngPntTypNav_48_PassedPoint4" 49 "MnvrngPntTypNav_49_PassedPoint5" 50 "MnvrngPntTypNav_50_destination";
VAL_ 1282 INavSts 0 "NavSts_0_Cruise" 1 "NavSts_1_navigation" 2 "NavSts_2_invalid";
VAL_ 66 IDspMeasmtSys 0 "DspMeasmtSys_0_kph" 1 "DspMeasmtSys_1_mph";
VAL_ 66 IUsgMdExtrCtrlAvlbl 0 "UsgMdExtrCtrlAvlbl_0_Unavailable" 1 "UsgMdExtrCtrlAvlbl_1_Available";
VAL_ 66 IUsgMdCtrlSts 0 "UsgMdCtrlSts_0_NormalMode" 1 "UsgMdCtrlSts_1_AutomatedDrivingMode";
VAL_ 66 IRWSDrvMdReqV 0 "RWSDrvMdReqV_0_Valid" 1 "RWSDrvMdReqV_1_Invalid";
VAL_ 66 IRWSDrvMdReq 0 "RWSDrvMdReq_0_Standart" 1 "RWSDrvMdReq_1_Comfortable" 2 "RWSDrvMdReq_2_Sport" 3 "RWSDrvMdReq_3_Reserved" 4 "RWSDrvMdReq_4_Reserved" 5 "RWSDrvMdReq_5_Reserved" 6 "RWSDrvMdReq_6_Reserved" 7 "RWSDrvMdReq_7_Reserved";
VAL_ 66 IPDCSwReq 0 "PDCSwReq_0_No_request" 1 "PDCSwReq_1_Short_Press" 2 "PDCSwReq_2_Long_press" 3 "PDCSwReq_3_Reserved";
VAL_ 66 IPwrMdExtrCtrlAvlbl 0 "PwrMdExtrCtrlAvlbl_0_NotAvailable" 1 "PwrMdExtrCtrlAvlbl_1_Available";
VAL_ 66 IMdOfPwrMd 0 "MdOfPwrMd_0_NormalMode" 1 "MdOfPwrMd_1_AutomatedDrivingMode";
VAL_ 66 IClstrDspdVehSpd 255 "ClstrDspdVehSpd_255_Speed_Signal_Missing_Error_of_SCS";
VAL_ 66 IFRSeatVentCtrlSts 0 "FRSeatVentCtrlSts_0_Inactive" 1 "FRSeatVentCtrlSts_1_Local_control" 2 "FRSeatVentCtrlSts_2__1" 3 "FRSeatVentCtrlSts_3__2" 4 "FRSeatVentCtrlSts_4_Remote_control";
VAL_ 66 IFLSeatVentCtrlSts 0 "FLSeatVentCtrlSts_0_Inactive" 1 "FLSeatVentCtrlSts_1_Local_control" 2 "FLSeatVentCtrlSts_2__1" 3 "FLSeatVentCtrlSts_3__2" 4 "FLSeatVentCtrlSts_4_Remote_control";
VAL_ 66 IFRSeatHeatCtrlSts 0 "FRSeatHeatCtrlSts_0_Inactive" 1 "FRSeatHeatCtrlSts_1_Local_control" 2 "FRSeatHeatCtrlSts_2__1" 3 "FRSeatHeatCtrlSts_3__2" 4 "FRSeatHeatCtrlSts_4_Remote_control";
VAL_ 66 IFLSeatHeatCtrlSts 0 "FLSeatHeatCtrlSts_0_Inactive" 1 "FLSeatHeatCtrlSts_1_Local_control" 2 "FLSeatHeatCtrlSts_2__1" 3 "FLSeatHeatCtrlSts_3__2" 4 "FLSeatHeatCtrlSts_4_Remote_control";
VAL_ 871 IRembMapBldngResp 0 "RembMapBldngResp_0_No_Response" 1 "RembMapBldngResp_1_Remember_MapBuilding_Parking_out_Response" 2 "RembMapBldngResp_2_RememberMapBuilding_Parking_In_Response" 3 "RembMapBldngResp_3_Reserved";
VAL_ 871 IRembBldMapResp 0 "RembBldMapResp_0_No_Response" 1 "RembBldMapResp_1_Remember_BuildMap__Parking_out__Response" 2 "RembBldMapResp_2_Remember_BuildMap__Parking_In__Response";
VAL_ 871 IAVMSt 0 "AVMSt_0_NoDisplay" 1 "AVMSt_1_Display" 2 "AVMSt_2_DriverCloseAVM" 3 "AVMSt_3_Fault";
VAL_ 871 IRstrFctryDeftsReq 0 "RstrFctryDeftsReq_0_False" 1 "RstrFctryDeftsReq_1_True";
VAL_ 871 IMapListReq 0 "MapListReq_0_No_Request" 1 "MapListReq_1_Map_List_Request";
VAL_ 871 IRembParkngInMapRutResp 0 "RembParkngInMapRutResp_0_NoRequest" 1 "RembParkngInMapRutResp_1_MapRouteOne" 2 "RembParkngInMapRutResp_2_MapRouteTwo" 3 "RembParkngInMapRutResp_3_MapRouteThree" 4 "RembParkngInMapRutResp_4_MapRouteFour" 5 "RembParkngInMapRutResp_5_MapRouteFive" 6 "RembParkngInMapRutResp_6_MapRouteSix" 7 "RembParkngInMapRutResp_7_MapRouteSeven" 8 "RembParkngInMapRutResp_8_MapRouteEight" 9 "RembParkngInMapRutResp_9_MapRouteNine" 10 "RembParkngInMapRutResp_10_MapRouteTen" 11 "RembParkngInMapRutResp_11_MapRouteEleven" 12 "RembParkngInMapRutResp_12_MapRouteTwelve" 13 "RembParkngInMapRutResp_13_MapRouteThirteen" 14 "RembParkngInMapRutResp_14_MapRouteFourteen" 15 "RembParkngInMapRutResp_15_MapRouteFifteen";
VAL_ 871 IOtrIntlgntMdTrigHvacReq 0 "OtrIntlgntMdTrigHvacReq_0_No_Requset" 1 "OtrIntlgntMdTrigHvacReq_1_Refreshing_Mode" 2 "OtrIntlgntMdTrigHvacReq_2_Relax_Mode" 3 "OtrIntlgntMdTrigHvacReq_3_Calming_Mode" 4 "OtrIntlgntMdTrigHvacReq_4_Middle_Level_Tired_Mode" 5 "OtrIntlgntMdTrigHvacReq_5_Heavy_Level_Tired_Mode" 6 "OtrIntlgntMdTrigHvacReq_6_Rain_Mode" 7 "OtrIntlgntMdTrigHvacReq_7_Dressing_Mode" 8 "OtrIntlgntMdTrigHvacReq_8_Pet_Mode" 9 "OtrIntlgntMdTrigHvacReq_9_Reserved" 10 "OtrIntlgntMdTrigHvacReq_10_Reserved" 11 "OtrIntlgntMdTrigHvacReq_11_Reserved" 12 "OtrIntlgntMdTrigHvacReq_12_Reserved" 13 "OtrIntlgntMdTrigHvacReq_13_Reserved" 14 "OtrIntlgntMdTrigHvacReq_14_Reserved" 15 "OtrIntlgntMdTrigHvacReq_15_Reserved";
VAL_ 871 IIPDCoDrivingPlusFunReq 0 "IPDCoDrivingPlusFunReq_0__0" 1 "IPDCoDrivingPlusFunReq_1__1" 2 "IPDCoDrivingPlusFunReq_2__2" 3 "IPDCoDrivingPlusFunReq_3__3" 4 "IPDCoDrivingPlusFunReq_4__4" 5 "IPDCoDrivingPlusFunReq_5__5" 6 "IPDCoDrivingPlusFunReq_6__6" 7 "IPDCoDrivingPlusFunReq_7__7" 8 "IPDCoDrivingPlusFunReq_8__8" 9 "IPDCoDrivingPlusFunReq_9__9" 10 "IPDCoDrivingPlusFunReq_10__10" 11 "IPDCoDrivingPlusFunReq_11__11" 12 "IPDCoDrivingPlusFunReq_12__12" 13 "IPDCoDrivingPlusFunReq_13__13" 14 "IPDCoDrivingPlusFunReq_14__14" 15 "IPDCoDrivingPlusFunReq_15__15";
VAL_ 871 IICBE2EFunSwReq 0 "ICBE2EFunSwReq_0__0" 1 "ICBE2EFunSwReq_1__1" 2 "ICBE2EFunSwReq_2__2" 3 "ICBE2EFunSwReq_3__3" 4 "ICBE2EFunSwReq_4__4" 5 "ICBE2EFunSwReq_5__5" 6 "ICBE2EFunSwReq_6__6" 7 "ICBE2EFunSwReq_7__7" 8 "ICBE2EFunSwReq_8__8" 9 "ICBE2EFunSwReq_9__9" 10 "ICBE2EFunSwReq_10__10" 11 "ICBE2EFunSwReq_11__11" 12 "ICBE2EFunSwReq_12__12" 13 "ICBE2EFunSwReq_13__13" 14 "ICBE2EFunSwReq_14__14" 15 "ICBE2EFunSwReq_15__15";
VAL_ 871 IDCDCVolStptBkup 254 "DCDCVolStptBkup_254_Init" 255 "DCDCVolStptBkup_255_Invalid";
VAL_ 863 IDstrctnDetnSts 0 "DstrctnDetnSts_0_SignalNotAvailable" 1 "DstrctnDetnSts_1_Off" 2 "DstrctnDetnSts_2_On";
VAL_ 863 IFtgDetnSts 0 "FtgDetnSts_0_SignalNotAvailable" 1 "FtgDetnSts_1_Off" 2 "FtgDetnSts_2_On";
VAL_ 906 INavCrntRoadTyp 0 "NavCrntRoadTyp_0_Unknown" 1 "NavCrntRoadTyp_1_Highway" 2 "NavCrntRoadTyp_2_inter_urban_roads" 3 "NavCrntRoadTyp_3_City_roads" 4 "NavCrntRoadTyp_4_Ramp" 5 "NavCrntRoadTyp_5_National_road" 6 "NavCrntRoadTyp_6_Provincial_road" 7 "NavCrntRoadTyp_7_County_road" 8 "NavCrntRoadTyp_8_Village_road" 9 "NavCrntRoadTyp_9_City_express_way" 10 "NavCrntRoadTyp_10_Major_urban_road" 11 "NavCrntRoadTyp_11_Secondary_urban_road" 12 "NavCrntRoadTyp_12_Normal_urban_road" 13 "NavCrntRoadTyp_13_Non_Navigation_Road" 14 "NavCrntRoadTyp_14_Reserve";
VAL_ 906 INavNewIcon 0 "NavNewIcon_0_unknown" 1 "NavNewIcon_1_left" 2 "NavNewIcon_2_right" 3 "NavNewIcon_3_LeftFront" 4 "NavNewIcon_4_RightFront" 5 "NavNewIcon_5_LeftRear" 6 "NavNewIcon_6_RightRear" 7 "NavNewIcon_7_LeftU_turn" 8 "NavNewIcon_8_RightU_turn" 9 "NavNewIcon_9_GoStraight" 10 "NavNewIcon_10_RoundaboutEntrance" 11 "NavNewIcon_11_RoundaboutExit" 12 "NavNewIcon_12_ServiceArea" 13 "NavNewIcon_13_TollStation" 14 "NavNewIcon_14_tunnel" 15 "NavNewIcon_15_NotUsed";
VAL_ 906 IVceCntrl_CriSpdDecreValu 255 "VceCntrl_CriSpdDecreValu_255_SpeedSignalMissingErrorOfScs";
VAL_ 906 IVceCntrl_CriSpdIncreValu 255 "VceCntrl_CriSpdIncreValu_255_SpeedSignalMissingErrorOfScs";
VAL_ 906 IVceCntrl_CriSpdValu 255 "VceCntrl_CriSpdValu_255_SpeedSignalMissingErrorOfScs";
VAL_ 906 IMinorAdjSetReq 0 "MinorAdjSetReq_0_NoRequest" 1 "MinorAdjSetReq_1_OFF" 2 "MinorAdjSetReq_2_ON" 3 "MinorAdjSetReq_3_Reserved";
VAL_ 906 IVceCntrl_DistanLevl 0 "VceCntrl_DistanLevl_0_NoGapSet" 1 "VceCntrl_DistanLevl_1_DistanceLevel1" 2 "VceCntrl_DistanLevl_2_DistanceLevel2" 3 "VceCntrl_DistanLevl_3_DistanceLevel3" 4 "VceCntrl_DistanLevl_4_DistanceLevel4" 5 "VceCntrl_DistanLevl_5_DistanceLevel5" 6 "VceCntrl_DistanLevl_6_DistanceLevel6" 7 "VceCntrl_DistanLevl_7_DistanceLevel7";
VAL_ 906 IVceCntrl_DecreCriSpd 0 "VceCntrl_DecreCriSpd_0_NoRequest" 1 "VceCntrl_DecreCriSpd_1_Decrese5kmh" 2 "VceCntrl_DecreCriSpd_2_Decrese10kmh" 3 "VceCntrl_DecreCriSpd_3_Decrese15kmh" 4 "VceCntrl_DecreCriSpd_4_Decrese20kmh" 5 "VceCntrl_DecreCriSpd_5_Decrese25kmh" 6 "VceCntrl_DecreCriSpd_6_Decrese30kmh" 7 "VceCntrl_DecreCriSpd_7_Decrese35kmh";
VAL_ 906 IParkOutEntrySetReq 0 "ParkOutEntrySetReq_0_NoRequest" 1 "ParkOutEntrySetReq_1_OFF" 2 "ParkOutEntrySetReq_2_ON" 3 "ParkOutEntrySetReq_3_Reserved";
VAL_ 906 IVceCntrl_AIPilot 0 "VceCntrl_AIPilot_0_NoRequest" 1 "VceCntrl_AIPilot_1_AccActiveRequest" 2 "VceCntrl_AIPilot_2_AipilotActiveRequest" 3 "VceCntrl_AIPilot_3_Close";
VAL_ 906 INavTrfcLghtInfo 0 "NavTrfcLghtInfo_0_NoDisplay" 1 "NavTrfcLghtInfo_1_TrafficLight0" 2 "NavTrfcLghtInfo_2_TrafficLight1" 3 "NavTrfcLghtInfo_3_TrafficLight2" 4 "NavTrfcLghtInfo_4_TrafficLight3" 5 "NavTrfcLghtInfo_5_TrafficLight4";
VAL_ 906 IVceCntrl_DistanLevlIncre 0 "VceCntrl_DistanLevlIncre_0_NoGapSet" 1 "VceCntrl_DistanLevlIncre_1_Increase1" 2 "VceCntrl_DistanLevlIncre_2_Increase2" 3 "VceCntrl_DistanLevlIncre_3_Increase3" 4 "VceCntrl_DistanLevlIncre_4_Increase4" 5 "VceCntrl_DistanLevlIncre_5_Increase5" 6 "VceCntrl_DistanLevlIncre_6_Increase6" 7 "VceCntrl_DistanLevlIncre_7_Increase7";
VAL_ 906 IVceCntrl_DistanLevlDecre 0 "VceCntrl_DistanLevlDecre_0_NoGapSet" 1 "VceCntrl_DistanLevlDecre_1_Decrease1" 2 "VceCntrl_DistanLevlDecre_2_Decrease2" 3 "VceCntrl_DistanLevlDecre_3_Decrease3" 4 "VceCntrl_DistanLevlDecre_4_Decrease4" 5 "VceCntrl_DistanLevlDecre_5_Decrease5" 6 "VceCntrl_DistanLevlDecre_6_Decrease6" 7 "VceCntrl_DistanLevlDecre_7_Decrease7";
VAL_ 906 INavSpdLmtValUnit 0 "NavSpdLmtValUnit_0_Unknown" 1 "NavSpdLmtValUnit_1_MPH" 2 "NavSpdLmtValUnit_2_KMH" 3 "NavSpdLmtValUnit_3_Reserved";
VAL_ 906 INavNewIconDist 0 "NavNewIconDist_0_no_newIcon_ahead" 21 "NavNewIconDist_21_over_2km";
VAL_ 906 INavSpdLmtValSts 0 "NavSpdLmtValSts_0_Fault" 1 "NavSpdLmtValSts_1_Inactive" 2 "NavSpdLmtValSts_2_Active";
VAL_ 906 INavDistFromFrtEleccEye 0 "NavDistFromFrtEleccEye_0_no_SLC_ahead" 61 "NavDistFromFrtEleccEye_61_over_6km";
VAL_ 906 INavItvalSpdDetnDistRetDist 0 "NavItvalSpdDetnDistRetDist_0_not_in_ISD" 251 "NavItvalSpdDetnDistRetDist_251_over_70km";
VAL_ 906 IVceCntrl_IncreCriSpd 0 "VceCntrl_IncreCriSpd_0_NoRequest" 1 "VceCntrl_IncreCriSpd_1_Increse5kmh" 2 "VceCntrl_IncreCriSpd_2_Increse10kmh" 3 "VceCntrl_IncreCriSpd_3_Increse15kmh" 4 "VceCntrl_IncreCriSpd_4_Increse20kmh" 5 "VceCntrl_IncreCriSpd_5_Increse25kmh" 6 "VceCntrl_IncreCriSpd_6_Increse30kmh" 7 "VceCntrl_IncreCriSpd_7_Increse35kmh";
VAL_ 906 INavSpdLmtTyp 0 "NavSpdLmtTyp_0_Not_specific" 1 "NavSpdLmtTyp_1_Camera_detection" 2 "NavSpdLmtTyp_2_Interval_speed_detection";
VAL_ 932 ITrnptVehBodyDspReq 0 "TrnptVehBodyDspReq_0_NoRequest" 1 "TrnptVehBodyDspReq_1_Open" 2 "TrnptVehBodyDspReq_2_Close";
VAL_ 932 INextPicture 0 "NextPicture_0_NoRequest" 1 "NextPicture_1_NextPicture";
VAL_ 932 IUnSelePoint 0 "UnSelePoint_0_NoRequest" 1 "UnSelePoint_1_PointSelectUndo";
VAL_ 932 IStartCalib 0 "StartCalib_0_NoRequest" 1 "StartCalib_1_Start_EndLine_Calibration" 2 "StartCalib_2_Start_4S_Calibration";
VAL_ 932 IVehDragMdSts 0 "VehDragMdSts_0_Off" 1 "VehDragMdSts_1_On" 2 "VehDragMdSts_2_Failed" 3 "VehDragMdSts_3_reserved" 4 "VehDragMdSts_4_reserved" 5 "VehDragMdSts_5_reserved" 6 "VehDragMdSts_6_reserved" 7 "VehDragMdSts_7_reserved";
VAL_ 1104 IParkngFuncICMRsrv01 0 "ParkngFuncICMRsrv01_0_Reserve" 1 "ParkngFuncICMRsrv01_1_Reserve" 2 "ParkngFuncICMRsrv01_2_Reserve" 3 "ParkngFuncICMRsrv01_3_Reserve" 4 "ParkngFuncICMRsrv01_4_Reserve" 5 "ParkngFuncICMRsrv01_5_Reserve" 6 "ParkngFuncICMRsrv01_6_Reserve" 7 "ParkngFuncICMRsrv01_7_Reserve";
VAL_ 1104 IMapDelete 0 "MapDelete_0_No_Request" 1 "MapDelete_1_Delete_Map1" 2 "MapDelete_2_Delete_Map5" 3 "MapDelete_3_Delete_Map2" 4 "MapDelete_4_Delete_Map6" 5 "MapDelete_5_Delete_Map3" 6 "MapDelete_6_Delete_Map7" 7 "MapDelete_7_Delete_Map4" 8 "MapDelete_8_Delete_Map8";
VAL_ 1104 IParkngFuncICMRsrv03 0 "ParkngFuncICMRsrv03_0_Reserve" 1 "ParkngFuncICMRsrv03_1_Reserve" 2 "ParkngFuncICMRsrv03_2_Reserve" 3 "ParkngFuncICMRsrv03_3_Reserve" 4 "ParkngFuncICMRsrv03_4_Reserve" 5 "ParkngFuncICMRsrv03_5_Reserve" 6 "ParkngFuncICMRsrv03_6_Reserve" 7 "ParkngFuncICMRsrv03_7_Reserve";
VAL_ 1104 IParkngFuncICMRsrv02 0 "ParkngFuncICMRsrv02_0_Reserve" 1 "ParkngFuncICMRsrv02_1_Reserve" 2 "ParkngFuncICMRsrv02_2_Reserve" 3 "ParkngFuncICMRsrv02_3_Reserve" 4 "ParkngFuncICMRsrv02_4_Reserve" 5 "ParkngFuncICMRsrv02_5_Reserve" 6 "ParkngFuncICMRsrv02_6_Reserve" 7 "ParkngFuncICMRsrv02_7_Reserve";
VAL_ 1104 IFrntWhlMinorAdjLeft 0 "FrntWhMinorAdjLeft_0_0" 1 "FrntWhMinorAdjLeft_1_5" 2 "FrntWhMinorAdjLeft_2_10" 3 "FrntWhMinorAdjLeft_3_15" 4 "FrntWhMinorAdjLeft_4_20" 5 "FrntWhMinorAdjLeft_5_25" 6 "FrntWhMinorAdjLeft_6_30" 7 "FrntWhMinorAdjLeft_7_35" 8 "FrntWhMinorAdjLeft_8_40" 9 "FrntWhMinorAdjLeft_9_45" 10 "FrntWhMinorAdjLeft_10_50" 11 "FrntWhMinorAdjLeft_11_55" 12 "FrntWhMinorAdjLeft_12_60";
VAL_ 1104 INrwroadFwdCtlReq 0 "NrwroadFwdCtlReq_0_NoRequest" 1 "NrwroadFwdCtlReq_1_Entry" 2 "NrwroadFwdCtlReq_2_Start" 3 "NrwroadFwdCtlReq_3_Pause" 4 "NrwroadFwdCtlReq_4_Continue" 5 "NrwroadFwdCtlReq_5_Exit" 6 "NrwroadFwdCtlReq_6_Reserved6" 7 "NrwroadFwdCtlReq_7_Reserved7" 8 "NrwroadFwdCtlReq_8_Reserved8" 9 "NrwroadFwdCtlReq_9_Reserved9" 10 "NrwroadFwdCtlReq_10_Reserved10" 11 "NrwroadFwdCtlReq_11_Reserved11" 12 "NrwroadFwdCtlReq_12_Reserved12" 13 "NrwroadFwdCtlReq_13_Reserved13" 14 "NrwroadFwdCtlReq_14_Reserved14" 15 "NrwroadFwdCtlReq_15_Reserved15";
VAL_ 1104 IRearWhlMinorAdjLeft 0 "RearWhMinorAdjLeft_0_0" 1 "RearWhMinorAdjLeft_1_5" 2 "RearWhMinorAdjLeft_2_10" 3 "RearWhMinorAdjLeft_3_15" 4 "RearWhMinorAdjLeft_4_20" 5 "RearWhMinorAdjLeft_5_25" 6 "RearWhMinorAdjLeft_6_30" 7 "RearWhMinorAdjLeft_7_35" 8 "RearWhMinorAdjLeft_8_40" 9 "RearWhMinorAdjLeft_9_45" 10 "RearWhMinorAdjLeft_10_50" 11 "RearWhMinorAdjLeft_11_55" 12 "RearWhMinorAdjLeft_12_60";
VAL_ 1104 IFrntWhlMinorAdjRight 0 "FrntWhMinorAdjRight_0_0" 1 "FrntWhMinorAdjRight_1_5" 2 "FrntWhMinorAdjRight_2_10" 3 "FrntWhMinorAdjRight_3_15" 4 "FrntWhMinorAdjRight_4_20" 5 "FrntWhMinorAdjRight_5_25" 6 "FrntWhMinorAdjRight_6_30" 7 "FrntWhMinorAdjRight_7_35" 8 "FrntWhMinorAdjRight_8_40" 9 "FrntWhMinorAdjRight_9_45" 10 "FrntWhMinorAdjRight_10_50" 11 "FrntWhMinorAdjRight_11_55" 12 "FrntWhMinorAdjRight_12_60";
VAL_ 1104 IMinorAdjForward 0 "MinorAdjForward_0_0" 1 "MinorAdjForward_1_5" 2 "MinorAdjForward_2_10" 3 "MinorAdjForward_3_15" 4 "MinorAdjForward_4_20" 5 "MinorAdjForward_5_25" 6 "MinorAdjForward_6_30" 7 "MinorAdjForward_7_35" 8 "MinorAdjForward_8_40" 9 "MinorAdjForward_9_45" 10 "MinorAdjForward_10_50" 11 "MinorAdjForward_11_55" 12 "MinorAdjForward_12_60";
VAL_ 1104 IRearWhlMinorAdjRight 0 "RearWhMinorAdjRight_0_0" 1 "RearWhMinorAdjRight_1_5" 2 "RearWhMinorAdjRight_2_10" 3 "RearWhMinorAdjRight_3_15" 4 "RearWhMinorAdjRight_4_20" 5 "RearWhMinorAdjRight_5_25" 6 "RearWhMinorAdjRight_6_30" 7 "RearWhMinorAdjRight_7_35" 8 "RearWhMinorAdjRight_8_40" 9 "RearWhMinorAdjRight_9_45" 10 "RearWhMinorAdjRight_10_50" 11 "RearWhMinorAdjRight_11_55" 12 "RearWhMinorAdjRight_12_60";
VAL_ 1104 ISpeedRegulationFixedReq 0 "SpeedRegulationFixedReq_0_Fixed_0" 1 "SpeedRegulationFixedReq_1_Fixed_5" 2 "SpeedRegulationFixedReq_2_Fixed_10" 3 "SpeedRegulationFixedReq_3_Fixed_15" 4 "SpeedRegulationFixedReq_4_Fixed_20" 5 "SpeedRegulationFixedReq_5_Fixed__5" 6 "SpeedRegulationFixedReq_6_Fixed__10" 7 "SpeedRegulationFixedReq_7_Fixed__15" 8 "SpeedRegulationFixedReq_8_Fixed__20";
VAL_ 1104 IMinorAdjBackward 0 "MinorAdjBackward_0_0" 1 "MinorAdjBackward_1_5" 2 "MinorAdjBackward_2_10" 3 "MinorAdjBackward_3_15" 4 "MinorAdjBackward_4_20" 5 "MinorAdjBackward_5_25" 6 "MinorAdjBackward_6_30" 7 "MinorAdjBackward_7_35" 8 "MinorAdjBackward_8_40" 9 "MinorAdjBackward_9_45" 10 "MinorAdjBackward_10_50" 11 "MinorAdjBackward_11_55" 12 "MinorAdjBackward_12_60";
VAL_ 1104 IMemParkngReq 0 "MemParkngReq_0_No_request" 1 "MemParkngReq_1_Request_LPNP";
VAL_ 1104 IParkngOutDirChs 0 "ParkngOutDirChs_0_NoRequest" 1 "ParkngOutDirChs_1_FrontLeft" 2 "ParkngOutDirChs_2_FrontRight" 3 "ParkngOutDirChs_3_RearLeft" 4 "ParkngOutDirChs_4_RearRight" 5 "ParkngOutDirChs_5_Reserve" 6 "ParkngOutDirChs_6_Reserve" 7 "ParkngOutDirChs_7_Reserve";
VAL_ 1104 ISpeedRegulationPerReq 0 "SpeedRegulationPerReq_0_Per_0" 1 "SpeedRegulationPerReq_1_Per_5" 2 "SpeedRegulationPerReq_2_Per_10" 3 "SpeedRegulationPerReq_3_Per_15" 4 "SpeedRegulationPerReq_4_Per_20" 5 "SpeedRegulationPerReq_5_Per__5" 6 "SpeedRegulationPerReq_6_Per__10" 7 "SpeedRegulationPerReq_7_Per__15" 8 "SpeedRegulationPerReq_8_Per__20";
VAL_ 1104 ISlntSrchParkngLotSet 0 "SlntSrchParkngLotSet_0_NoRequest" 1 "SlntSrchParkngLotSet_1_OFF" 2 "SlntSrchParkngLotSet_2_ON" 3 "SlntSrchParkngLotSet_3_Reserve";
VAL_ 1104 IDIYParkngLotSty 0 "DIYParkngLotSty_0_NoRequest" 1 "DIYParkngLotSty_1_vertical" 2 "DIYParkngLotSty_2_Horizontal" 3 "DIYParkngLotSty_3_Reserved" 4 "DIYParkngLotSty_4_Reserved" 5 "DIYParkngLotSty_5_Reserved" 6 "DIYParkngLotSty_6_Reserved";
VAL_ 1104 IAIParkngDrvStySet 0 "AIParkngDrvStySet_0_Norequest" 1 "AIParkngDrvStySet_1_normal" 2 "AIParkngDrvStySet_2_conservative" 3 "AIParkngDrvStySet_3_radical";
VAL_ 1104 IFucSwReq1 0 "FucSwReq1_0_NoRequest" 1 "FucSwReq1_1_ON" 2 "FucSwReq1_2_OFF";
VAL_ 1104 IAIParkngSpdsw 0 "AIParkngSpdsw_0_no_request" 1 "AIParkngSpdsw_1_Low_speed" 2 "AIParkngSpdsw_2_Normal_speed" 3 "AIParkngSpdsw_3_High_speed";
VAL_ 1104 IMnrAdjCntrlReq 0 "MnrAdjCntrlReq_0_NoRequest" 1 "MnrAdjCntrlReq_1_Start" 2 "MnrAdjCntrlReq_2_Pause" 3 "MnrAdjCntrlReq_3_Continue" 4 "MnrAdjCntrlReq_4_Exit" 5 "MnrAdjCntrlReq_5_Reserve" 6 "MnrAdjCntrlReq_6_Reserve" 7 "MnrAdjCntrlReq_7_Reserve";
VAL_ 1104 IUNPSwReq 0 "UNPSwReq_0_NoRequest" 1 "UNPSwReq_1_ON" 2 "UNPSwReq_2_OFF";
VAL_ 1104 IFucSwReq2 0 "FucSwReq2_0_NoRequest" 1 "FucSwReq2_1_Gear1" 2 "FucSwReq2_2_Gear2" 3 "FucSwReq2_3_Gear3" 4 "FucSwReq2_4_Gear4";
VAL_ 1104 IVoicBrdstMode 0 "VoicBrdstMode_0_No_request" 1 "VoicBrdstMode_1_Mute" 2 "VoicBrdstMode_2_Simple" 3 "VoicBrdstMode_3_Detail";
VAL_ 1104 IManualpilotSwReq 0 "ManualpilotSwReq_0_NoRequest" 1 "ManualpilotSwReq_1_ON" 2 "ManualpilotSwReq_2_OFF";
VAL_ 1104 INrwroadsltReq 0 "NrwroadsltReq_0_No_request" 1 "NrwroadsltReq_1_ON" 2 "NrwroadsltReq_2_OFF" 3 "NrwroadsltReq_3_Unavailable";
VAL_ 1104 INrwroadFwdReq 0 "NrwroadFwdReq_0_No_request" 1 "NrwroadFwdReq_1_ON" 2 "NrwroadFwdReq_2_OFF" 3 "NrwroadFwdReq_3_Unavailable";
VAL_ 1104 IPilotplusSwReq 0 "PilotplusSwReq_0_NoRequest" 1 "PilotplusSwReq_1_ON" 2 "PilotplusSwReq_2_OFF" 3 "PilotplusSwReq_3_Other";
VAL_ 1104 IParkngrampastsltReq 0 "ParkngrampastsltReq_0_No_request" 1 "ParkngrampastsltReq_1_ON" 2 "ParkngrampastsltReq_2_OFF" 3 "ParkngrampastsltReq_3_Unavailable";
VAL_ 1104 IParkngrampastReq 0 "ParkngrampastReq_0_No_request" 1 "ParkngrampastReq_1_ON" 2 "ParkngrampastReq_2_OFF" 3 "ParkngrampastReq_3_Unavailable";
VAL_ 1104 IParkngOutRcmnSet 0 "ParkngOutRcmnSet_0_NoRequest" 1 "ParkngOutRcmnSet_1_OFF" 2 "ParkngOutRcmnSet_2_ON" 3 "ParkngOutRcmnSet_3_Reserve";
VAL_ 1104 IAIParkngOutSty 0 "AIParkngOutSty_0_NoRequest" 1 "AIParkngOutSty_1_HeadOut" 2 "AIParkngOutSty_2_VehicleOut" 3 "AIParkngOutSty_3_Reserve";
VAL_ 1104 IRvrsTrckParkng 0 "RvrsTrckParkng_0_NoRequest" 1 "RvrsTrckParkng_1_Request" 2 "RvrsTrckParkng_2_Reserved" 3 "RvrsTrckParkng_3_Reserved";
VAL_ 1104 ISpeedRegulationModeReq 0 "SpeedRegulationModeReq_0_Fixed" 1 "SpeedRegulationModeReq_1_Per";
VAL_ 1104 IMnrAdjReq 0 "MnrAdjReq_0_NoRequest" 1 "MnrAdjReq_1_Request";
VAL_ 1104 IDIYParkngLotReq 0 "DIYParkngLotReq_0_NoRequest" 1 "DIYParkngLotReq_1_Request";
VAL_ 1104 IEdtNameInd 0 "EdtNameInd_0_Inactive" 1 "EdtNameInd_1_Active";
VAL_ 1104 ITryMemParkngNw 0 "TryMemParkngNw_0_No_request" 1 "TryMemParkngNw_1_Request";
VAL_ 1104 IDIYParkngLotSet 0 "DIYParkngLotSet_0_NoRequest" 1 "DIYParkngLotSet_1_OFF" 2 "DIYParkngLotSet_2_ON" 3 "DIYParkngLotSet_3_Reserve";
VAL_ 1104 IParkngrampastCtlReq 0 "ParkngrampastCtlReq_0_NoRequest" 1 "ParkngrampastCtlReq_1_Entry" 2 "ParkngrampastCtlReq_2_Start" 3 "ParkngrampastCtlReq_3_Pause" 4 "ParkngrampastCtlReq_4_Continue" 5 "ParkngrampastCtlReq_5_Exit" 6 "ParkngrampastCtlReq_6_Reserved6" 7 "ParkngrampastCtlReq_7_Reserved7" 8 "ParkngrampastCtlReq_8_Reserved8" 9 "ParkngrampastCtlReq_9_Reserved9" 10 "ParkngrampastCtlReq_10_Reserved10" 11 "ParkngrampastCtlReq_11_Reserved11" 12 "ParkngrampastCtlReq_12_Reserved12" 13 "ParkngrampastCtlReq_13_Reserved13" 14 "ParkngrampastCtlReq_14_Reserved14" 15 "ParkngrampastCtlReq_15_Reserved15";
VAL_ 832 IAIPilotSwReq 0 "AIPilotSwReq_0_NoRequest" 1 "AIPilotSwReq_1_ACC" 2 "AIPilotSwReq_2_Pilot" 3 "AIPilotSwReq_3_SuperPilot";
VAL_ 832 IAIPilotDrvMdlReq 0 "AIPilotDrvMdlReq_0_NoRequest" 1 "AIPilotDrvMdlReq_1_SafeDrivingModel" 2 "AIPilotDrvMdlReq_2_SteadyDrivingModel" 3 "AIPilotDrvMdlReq_3_RadicalDrivingModel" 4 "AIPilotDrvMdlReq_4_SelfLearningModel" 5 "AIPilotDrvMdlReq_5_CustomizedDrivingModel";
VAL_ 832 IFCWSnstvtLvlReq 0 "FCWSnstvtLvlReq_0_NoRequest" 1 "FCWSnstvtLvlReq_1_level1_low" 2 "FCWSnstvtLvlReq_2_level2_middle" 3 "FCWSnstvtLvlReq_3_level3_high" 4 "FCWSnstvtLvlReq_4_reserved" 5 "FCWSnstvtLvlReq_5_reserved" 6 "FCWSnstvtLvlReq_6_reserved" 7 "FCWSnstvtLvlReq_7_reserved";
VAL_ 832 IELKSwReq 0 "ELKSwReq_0_no_request" 1 "ELKSwReq_1_off" 2 "ELKSwReq_2_on" 3 "ELKSwReq_3_reserved";
VAL_ 832 ILDWAdoWrnngReq 0 "LDWAdoWrnngReq_0_no_request" 1 "LDWAdoWrnngReq_1_off" 2 "LDWAdoWrnngReq_2_on" 3 "LDWAdoWrnngReq_3_on";
VAL_ 832 IFCWSwReq 0 "FCWSwReq_0_NoRequest" 1 "FCWSwReq_1_off" 2 "FCWSwReq_2_on" 3 "FCWSwReq_3_reserved";
VAL_ 832 ITrfcLghtFuctionSwReq 0 "TrfcLghtFuctionSwReq_0_TrfcLghtFnSwReq_0_NoRequest" 1 "TrfcLghtFuctionSwReq_1_TrfcLghtFnSwReq_1_OFF" 2 "TrfcLghtFuctionSwReq_2_TrfcLghtFnSwReq_2_Warning" 3 "TrfcLghtFuctionSwReq_3_TrfcLghtFnSwReq_3_Contorl";
VAL_ 832 IDOWSelReq 0 "DOWSelReq_0_no_request" 1 "DOWSelReq_1_driver_switch_off_request" 2 "DOWSelReq_2_driver_switch_on_request" 3 "DOWSelReq_3_reserve";
VAL_ 832 IBSDSelReq 0 "BSDSelReq_0_no_request" 1 "BSDSelReq_1_driver_switch_off_request" 2 "BSDSelReq_2_driver_switch_on_request" 3 "BSDSelReq_3_reserve";
VAL_ 832 IAIPilotAudSwReq 0 "AIPilotAudSwReq_0_NoRequest" 1 "AIPilotAudSwReq_1_ON" 2 "AIPilotAudSwReq_2_OFF";
VAL_ 832 IEndToEndPilotSwReq 0 "EndToEndPilotSwReq_0_NoRequest" 1 "EndToEndPilotSwReq_1_ON" 2 "EndToEndPilotSwReq_2_OFF";
VAL_ 832 ILaneChngRecmedMdlReq 0 "LaneChngRecmedMdlReq_0_NoRequest" 1 "LaneChngRecmedMdlReq_1_ON" 2 "LaneChngRecmedMdlReq_2_OFF";
VAL_ 832 IAEBSwReq 0 "AEBSwReq_0_NoRequest" 1 "AEBSwReq_1_off" 2 "AEBSwReq_2_on" 3 "AEBSwReq_3_reserved";
VAL_ 832 ILDWLKAHptWrnngReq 0 "LDWLKAHptWrnngReq_0_no_request" 1 "LDWLKAHptWrnngReq_1_off" 2 "LDWLKAHptWrnngReq_2_on";
VAL_ 832 IRCWSelReq 0 "RCWSelReq_0_no_request" 1 "RCWSelReq_1_ON" 2 "RCWSelReq_2_OFF";
VAL_ 832 ILaneChngCnfmSwReq 0 "LaneChngCnfmSwReq_0_NoRequest" 1 "LaneChngCnfmSwReq_1_ON" 2 "LaneChngCnfmSwReq_2_OFF";
VAL_ 832 IIntscnDclSwReq 0 "IntscnDclSwReq_0_NoRequest" 1 "IntscnDclSwReq_1_ON" 2 "IntscnDclSwReq_2_OFF";
VAL_ 832 IIntlgntParkngWifiSwReq 0 "IntlgntParkngWifiSwReq_0_NoRequest" 1 "IntlgntParkngWifiSwReq_1_ON" 2 "IntlgntParkngWifiSwReq_2_OFF";
VAL_ 832 IIntlgntParkngNavSwReq 0 "IntlgntParkngNavSwReq_0_NoRequest" 1 "IntlgntParkngNavSwReq_1_ON" 2 "IntlgntParkngNavSwReq_2_OFF";
VAL_ 832 INOASwReq 0 "NOASwReq_0_NoRequest" 1 "NOASwReq_1_ON" 2 "NOASwReq_2_OFF";
VAL_ 832 INOAQukSwReq 0 "NOAQukSwReq_0_NOASwReq_0_NoRequest" 1 "NOAQukSwReq_1_NOASwReq_1_ON" 2 "NOAQukSwReq_2_NOASwReq_2_OFF";
VAL_ 832 INarwSpcAstSwReq 0 "NarwSpcAstSwReq_0_NoRequest" 1 "NarwSpcAstSwReq_1_ON" 2 "NarwSpcAstSwReq_2_OFF";
VAL_ 832 ILaneChngWrnngSwReq 0 "LaneChngWrnngSwReq_0_NoRequest" 1 "LaneChngWrnngSwReq_1_Off" 2 "LaneChngWrnngSwReq_2_Vioce" 3 "LaneChngWrnngSwReq_3_Beep";
VAL_ 832 ILDWSnstvtLvlReq 0 "LDWSnstvtLvlReq_0_NoRequest" 1 "LDWSnstvtLvlReq_1_Low" 2 "LDWSnstvtLvlReq_2_Standard" 3 "LDWSnstvtLvlReq_3_High";
VAL_ 832 IRembParkngInPrmtSwReq 0 "RembParkngInPrmtSwReq_0_NoRequest" 1 "RembParkngInPrmtSwReq_1_ON" 2 "RembParkngInPrmtSwReq_2_OFF";
VAL_ 832 IRDASwReq 0 "RDASwReq_0_no_request" 1 "RDASwReq_1_driver_switch_off_request" 2 "RDASwReq_2_driver_switch_on_request" 3 "RDASwReq_3_reserve";
VAL_ 832 IRCTSysSelReq 0 "RCTSysSelReq_0_no_request" 1 "RCTSysSelReq_1_driver_switch_RCTA_off_request" 2 "RCTSysSelReq_2_driver_switch_RCTA_on_request" 3 "RCTSysSelReq_3_driver_switch_RCTB_RCTA_on_request";
VAL_ 832 ILCASelReq 0 "LCASelReq_0_no_request" 1 "LCASelReq_1_driver_switch_off_request" 2 "LCASelReq_2_driver_switch_on_request" 3 "LCASelReq_3_reserve";
VAL_ 832 ILDWLKASwReq 0 "LDWLKASwReq_0_no_request" 1 "LDWLKASwReq_1_off" 2 "LDWLKASwReq_2_LDW" 3 "LDWLKASwReq_3_LDP" 4 "LDWLKASwReq_4_LKA" 5 "LDWLKASwReq_5_ELK";
VAL_ 832 ISpdLmtMdlReq 0 "SpdLmtMdlReq_0_NoRequest" 1 "SpdLmtMdlReq_1_SpeedOffset0" 2 "SpdLmtMdlReq_2_SpeedOffset_5" 3 "SpdLmtMdlReq_3_SpeedOffset_10" 4 "SpdLmtMdlReq_4_SpeedOffset_5";
VAL_ 836 IDIYParkngSpcConfirming 0 "DIYParkngSpcConfirming_0_False" 1 "DIYParkngSpcConfirming_1_True";
VAL_ 836 IRembParkngInMapngReq 0 "RembParkngInMapngReq_0_False" 1 "RembParkngInMapngReq_1_True";
VAL_ 836 IRembParkngInMapngIndcrCnfm 0 "RembParkngInMapngIndcrCnfm_0_NoRequest" 1 "RembParkngInMapngIndcrCnfm_1_ParkingInMappingFailedConfirmed" 2 "RembParkngInMapngIndcrCnfm_2_ParkingInManualRequestConfirmed" 3 "RembParkngInMapngIndcrCnfm_3_ParkingOutRequestConfirmed" 4 "RembParkngInMapngIndcrCnfm_4_ParkingOutRequestCancelled" 5 "RembParkngInMapngIndcrCnfm_5_RememberParkingConfirmed" 6 "RembParkngInMapngIndcrCnfm_6_RememberParkingSettingFinished" 7 "RembParkngInMapngIndcrCnfm_7_ContinueScanningConfirmed";
VAL_ 836 IRembParkngInPrmtCnfm 0 "RembParkngInPrmtCnfm_0_False" 1 "RembParkngInPrmtCnfm_1_True";
VAL_ 836 IRembParkngInMapRutDltReq 0 "RembParkngInMapRutDltReq_0_NoRequest" 1 "RembParkngInMapRutDltReq_1_MapRouteOne" 2 "RembParkngInMapRutDltReq_2_MapRouteTwo" 3 "RembParkngInMapRutDltReq_3_MapRouteThree" 4 "RembParkngInMapRutDltReq_4_MapRouteFour" 5 "RembParkngInMapRutDltReq_5_MapRouteFive" 6 "RembParkngInMapRutDltReq_6_MapRouteSix" 7 "RembParkngInMapRutDltReq_7_MapRouteSeven" 8 "RembParkngInMapRutDltReq_8_MapRouteEight" 9 "RembParkngInMapRutDltReq_9_MapRouteNine" 10 "RembParkngInMapRutDltReq_10_MapRouteTen" 11 "RembParkngInMapRutDltReq_11_MapRouteEleven" 12 "RembParkngInMapRutDltReq_12_MapRouteTwelve" 13 "RembParkngInMapRutDltReq_13_MapRouteThirteen" 14 "RembParkngInMapRutDltReq_14_MapRouteFourteen" 15 "RembParkngInMapRutDltReq_15_MapRouteFifteen";
VAL_ 836 IRembParkngInMapRutReq 0 "RembParkngInMapRutReq_0_NoRequest" 1 "RembParkngInMapRutReq_1_MapRouteOne" 2 "RembParkngInMapRutReq_2_MapRouteTwo" 3 "RembParkngInMapRutReq_3_MapRouteThree" 4 "RembParkngInMapRutReq_4_MapRouteFour" 5 "RembParkngInMapRutReq_5_MapRouteFive" 6 "RembParkngInMapRutReq_6_MapRouteSix" 7 "RembParkngInMapRutReq_7_MapRouteSeven" 8 "RembParkngInMapRutReq_8_MapRouteEight" 9 "RembParkngInMapRutReq_9_MapRouteNine" 10 "RembParkngInMapRutReq_10_MapRouteTen" 11 "RembParkngInMapRutReq_11_MapRouteEleven" 12 "RembParkngInMapRutReq_12_MapRouteTwelve" 13 "RembParkngInMapRutReq_13_MapRouteThirteen" 14 "RembParkngInMapRutReq_14_MapRouteFourteen" 15 "RembParkngInMapRutReq_15_MapRouteFifteen";
VAL_ 836 IIPDStsReq 0 "IPDStsReq_0_NoRequest" 1 "IPDStsReq_1_ON" 2 "IPDStsReq_2_OFF";
VAL_ 836 IRembParkngInMapngRutIDCnfm 0 "RembParkngInMapngRutIDCnfm_0_No_Request" 1 "RembParkngInMapngRutIDCnfm_1_Check_First_map_for_Parking_In" 2 "RembParkngInMapngRutIDCnfm_2_Check_Second_map_for_Parking_In" 3 "RembParkngInMapngRutIDCnfm_3_Check_Third_map_for_Parking_In" 4 "RembParkngInMapngRutIDCnfm_4_Check_4th_map_for_Parking_In" 5 "RembParkngInMapngRutIDCnfm_5_Check_5th_map_for_Parking_In" 6 "RembParkngInMapngRutIDCnfm_6_Check_6th_map_for_Parking_In" 7 "RembParkngInMapngRutIDCnfm_7_Check_7th_map_for_Parking_In" 8 "RembParkngInMapngRutIDCnfm_8_Check_8th_map_for_Parking_In" 9 "RembParkngInMapngRutIDCnfm_9_Check_9th_map_for_Parking_In" 10 "RembParkngInMapngRutIDCnfm_10_Check_10th_map_for_Parking_In" 11 "RembParkngInMapngRutIDCnfm_11_Check_First_map_for_Parking_Out" 12 "RembParkngInMapngRutIDCnfm_12_Check_Second_map_for_Parking_Out" 13 "RembParkngInMapngRutIDCnfm_13_Check_Third_map_for_Parking_Out" 14 "RembParkngInMapngRutIDCnfm_14_Check_4th_map_for_Parking_Out" 15 "RembParkngInMapngRutIDCnfm_15_Check_5th_map_for_Parking_Out" 16 "RembParkngInMapngRutIDCnfm_16_Check_6th_map_for_Parking_Out" 17 "RembParkngInMapngRutIDCnfm_17_Check_7th_map_for_Parking_Out" 18 "RembParkngInMapngRutIDCnfm_18_Check_8th_map_for_Parking_Out" 19 "RembParkngInMapngRutIDCnfm_19_Check_9th_map_for_Parking_Out" 20 "RembParkngInMapngRutIDCnfm_20_Check_10th_map_for_Parking_Out";
VAL_ 683 IDrvrUseIDRoleInfo 0 "DrvrUseIDRoleInfo_0_Guest" 1 "DrvrUseIDRoleInfo_1_VehicleOwner" 2 "DrvrUseIDRoleInfo_2_AuthorizedUser" 3 "DrvrUseIDRoleInfo_3_FansUser" 4 "DrvrUseIDRoleInfo_4_4SServiceUser" 5 "DrvrUseIDRoleInfo_5_ChargingServiceUser" 6 "DrvrUseIDRoleInfo_6_EngineerServiceUser";
VAL_ 823 IECUWarningsecinfo 0 "ECUWarningsecinfo_0_No_Warning" 1 "ECUWarningsecinfo_1_Warning";
VAL_ 823 IGPSWarningsecinfo 0 "GPSWarningsecinfo_0_No_Warning" 1 "GPSWarningsecinfo_1_Warning";
VAL_ 901 IIPKDErSts 0 "IPKDErSts_0_No_Error" 1 "IPKDErSts_1_Error";
VAL_ 901 IICMErSts 0 "ICMErSts_0_No_Error" 1 "ICMErSts_1_Error";
VAL_ 292 ITOUCH_SCREEN_ACMD 0 "TOUCH_SCREEN_ACMD_0_No_command" 1 "TOUCH_SCREEN_ACMD_1_ScreenTouched" 2 "TOUCH_SCREEN_ACMD_2_ScreenHold_reserved" 3 "TOUCH_SCREEN_ACMD_3_ScreenRelease";
VAL_ 292 ITOUCH_SCREEN_BCMD 0 "TOUCH_SCREEN_BCMD_0_No_command" 1 "TOUCH_SCREEN_BCMD_1_ScreenTouched" 3 "TOUCH_SCREEN_BCMD_3_ScreenRelease";
VAL_ 292 ITOUCH_SCREEN_STATUS 0 "TOUCH_SCREEN_STATUS_0_NoCommand" 1 "TOUCH_SCREEN_STATUS_1_2PointsScreenTouched" 2 "TOUCH_SCREEN_STATUS_2_reserved" 3 "TOUCH_SCREEN_STATUS_3_LessThan2PointsScreenTouched";
VAL_ 292 IDMSAvlbly 0 "DMSAvlbly_0__False" 1 "DMSAvlbly_1__True";
VAL_ 482 IErrRespStrgWhlSwMdl_L 0 "ErrRespStrgWhlSwMdl_L_0_No_Error" 1 "ErrRespStrgWhlSwMdl_L_1_Error";
VAL_ 482 ICCSwStsDistIncSwA 0 "CCSwStsDistIncSwA_0_False" 1 "CCSwStsDistIncSwA_1_True";
VAL_ 482 ICCSwStsDistDecSwA 0 "CCSwStsDistDecSwA_0_False" 1 "CCSwStsDistDecSwA_1_True";
VAL_ 482 ICCSwStsSpdIncSwA 0 "CCSwStsSpdIncSwA_0_False" 1 "CCSwStsSpdIncSwA_1_True";
VAL_ 482 ICCSwStsSpdDecSwA 0 "CCSwStsSpdDecSwA_0_False" 1 "CCSwStsSpdDecSwA_1_True";
VAL_ 482 ICCSwStsSwDataIntgty 0 "CCSwStsSwDataIntgty_0_DataValid" 1 "CCSwStsSwDataIntgty_1_DataInvalid" 2 "CCSwStsSwDataIntgty_2_FailureDetected" 3 "CCSwStsSwDataIntgty_3_IllegalRange";
SIG_GROUP_ 820 IICBAD_100ms_Group37 1 : IAutoLaneChngMsgReq IAutoLaneChngSetResp IAutoLaneChngSwDspCmd IDILampsCtrl IHzrdLampsCtrl IICBAD_100ms_Group37_CRC IICBAD_100ms_Group37_RC IICBAD_100ms_Group37_Reserved1 IICBAD_100ms_Group37_Reserved2 IICBAD_100ms_Group37_Reserved3 IICBAD_100ms_Group37_Reserved4 IICBAD_100ms_Group37_Reserved5 IICBAD_100ms_Group37_Reserved6 IICBAD_100ms_Group37_Reserved7 IOtsdMirFoldReq;
SIG_GROUP_ 382 IICBAD_20ms_Group07 1 : IACCAccReqSts_CH IACCAccReqVal IACCGoReq IACCSdslReq IACCSysFltSts IACCSysSts IICBAD_20ms_Group07_CRC IICBAD_20ms_Group07_RC IICBAD_20ms_Group07_Reserved1 IICBAD_20ms_Group07_Reserved2 IICBAD_20ms_Group07_Reserved3 IICBAD_20ms_Group07_Reserved4 IICBAD_20ms_Group07_Reserved5 IICBAD_20ms_Group07_Reserved6;
SIG_GROUP_ 81 IICBAD_ZONE_20ms_Group13 1 : IICBAD_ZONE_20ms_Group13_CRC IICBAD_ZONE_20ms_Group13_RC IICBAD_ZONE_20ms_Group13_Reserve0 IICBAD_ZONE_20ms_Group13_Reserve2 IICBAD_ZONE_20ms_Group13_Reserve1 IICBAD_ZONE_20ms_Group13_Reserve3 IICBAD_ZONE_20ms_Group13_Reserve4 IICBAD_ZONE_20ms_Group13_Reserve5 IICBAD_ZONE_20ms_Group13_Reserve6 IICBAD_ZONE_20ms_Group13_Reserve7 ILKASysFltSts ILKASysSts ITJAICASysFltSts ITJAICASysSts;
SIG_GROUP_ 901 IICBVC_100ms_Group78 1 : IICBVC_100ms_Group78_CRC IICBVC_100ms_Group78_RC IICBVC_100ms_Group78_Reserved1 IICBVC_100ms_Group78_Reserved2 IICBVC_100ms_Group78_Reserved3 IICBVC_100ms_Group78_Reserved4 IICBVC_100ms_Group78_Reserved5 IICBVC_100ms_Group78_Reserved6 IICBVC_100ms_Group78_Reserved7 IICMErSts IIPKDErSts;
SIG_GROUP_ 482 IICBVC_50ms_Group11 1 : ICCSwStsDistDecSwA ICCSwStsDistIncSwA ICCSwStsSpdDecSwA ICCSwStsSpdIncSwA ICCSwStsSwDataIntgty IErrRespStrgWhlSwMdl_L IICBVC_50ms_Group11_CRC IICBVC_50ms_Group11_RC IICBVC_50ms_Group11_Reserved1 IICBVC_50ms_Group11_Reserved2 IICBVC_50ms_Group11_Reserved3 IICBVC_50ms_Group11_Reserved4 IICBVC_50ms_Group11_Reserved5 IICBVC_50ms_Group11_Reserved6 IICBVC_50ms_Group11_Reserved7;
